VERSION "ZCUD_CAN1"

NS_ :

BS_:

BU_: ETC OGM POT SRS3 TRM ZCUD

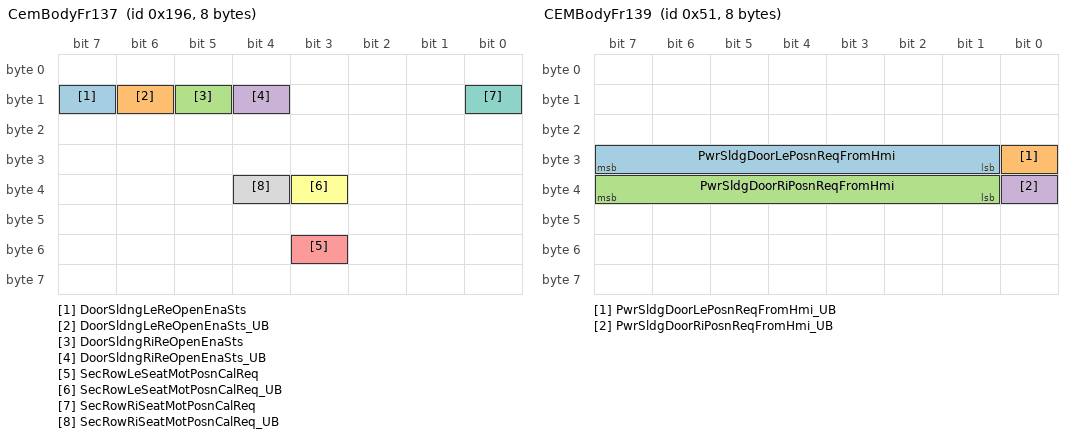
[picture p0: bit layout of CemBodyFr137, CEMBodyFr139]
BO_ 406 CemBodyFr137: 8 ZCUD
 SG_ DoorSldngLeReOpenEnaSts : 15|1@0+ (1,0) [0|1] "" Vector__XXX
 SG_ DoorSldngLeReOpenEnaSts_UB : 14|1@0+ (1,0) [0|1] "" Vector__XXX
 SG_ DoorSldngRiReOpenEnaSts : 13|1@0+ (1,0) [0|1] "" Vector__XXX
 SG_ DoorSldngRiReOpenEnaSts_UB : 12|1@0+ (1,0) [0|1] "" Vector__XXX
 SG_ SecRowLeSeatMotPosnCalReq : 51|1@0+ (1,0) [0|1] "" Vector__XXX
 SG_ SecRowLeSeatMotPosnCalReq_UB : 35|1@0+ (1,0) [0|1] "" Vector__XXX
 SG_ SecRowRiSeatMotPosnCalReq : 8|1@0+ (1,0) [0|1] "" Vector__XXX
 SG_ SecRowRiSeatMotPosnCalReq_UB : 36|1@0+ (1,0) [0|1] "" Vector__XXX

BO_ 81 CEMBodyFr139: 8 ZCUD
 SG_ PwrSldgDoorLePosnReqFromHmi : 31|7@0+ (1,0) [0|101] "%" Vector__XXX
 SG_ PwrSldgDoorLePosnReqFromHmi_UB : 24|1@0+ (1,0) [0|1] "" Vector__XXX
 SG_ PwrSldgDoorRiPosnReqFromHmi : 39|7@0+ (1,0) [0|101] "%" Vector__XXX
 SG_ PwrSldgDoorRiPosnReqFromHmi_UB : 32|1@0+ (1,0) [0|1] "" Vector__XXX

BO_ 1441 EtcToCmdXcpFr01: 8 ETC

BO_ 1412 EtcToRmlXcpFr01: 8 ETC

BO_ 1409 EtcToRmrXcpFr01: 8 ETC

BO_ 1413 EtcToSmblXcpFr01: 8 ETC

BO_ 1415 EtcToSmbrXcpFr01: 8 ETC

BO_ 1472 EtcToSmpXcpFr01: 8 ETC

BO_ 1465 EtcToTrmXcpFr01: 8 ETC

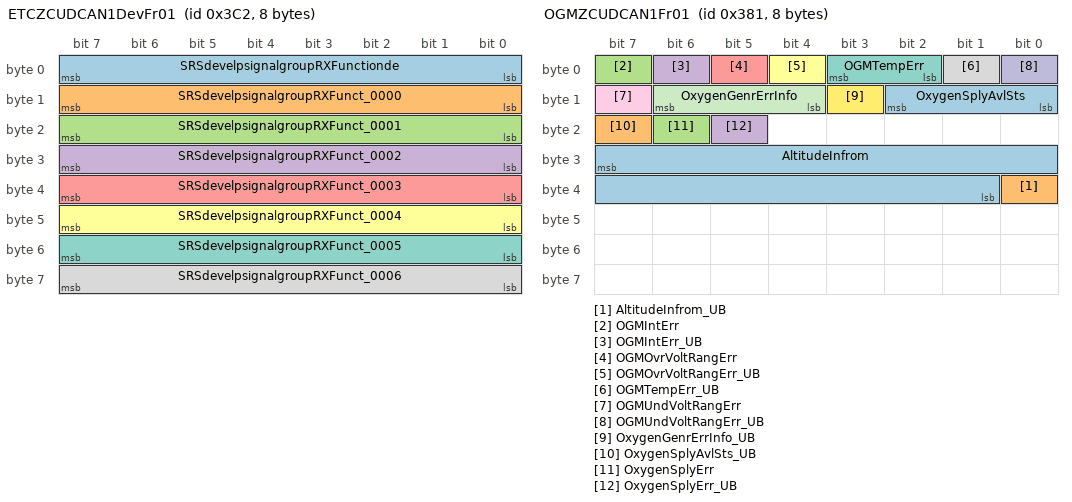
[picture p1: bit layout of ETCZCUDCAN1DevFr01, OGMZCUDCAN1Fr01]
BO_ 962 ETCZCUDCAN1DevFr01: 8 ETC
 SG_ SRSdevelpsignalgroupRXFunctionde : 7|8@0+ (1,0) [0|255] "Unitless"  SRS3
 SG_ SRSdevelpsignalgroupRXFunct_0000 : 15|8@0+ (1,0) [0|255] "Unitless"  SRS3
 SG_ SRSdevelpsignalgroupRXFunct_0001 : 23|8@0+ (1,0) [0|255] "Unitless"  SRS3
 SG_ SRSdevelpsignalgroupRXFunct_0002 : 31|8@0+ (1,0) [0|255] "Unitless"  SRS3
 SG_ SRSdevelpsignalgroupRXFunct_0003 : 39|8@0+ (1,0) [0|255] "Unitless"  SRS3
 SG_ SRSdevelpsignalgroupRXFunct_0004 : 47|8@0+ (1,0) [0|255] "Unitless"  SRS3
 SG_ SRSdevelpsignalgroupRXFunct_0005 : 55|8@0+ (1,0) [0|255] "Unitless"  SRS3
 SG_ SRSdevelpsignalgroupRXFunct_0006 : 63|8@0+ (1,0) [0|255] "Unitless"  SRS3

BO_ 1596 OgmToZcudZCUDCAN1DiagResFrame: 8 OGM
 SG_ OgmToZcudZCUDCan1DiagResNpdu : 7|64@0+ (1,0) [0|0] ""  ZCUD

BO_ 897 OGMZCUDCAN1Fr01: 8 OGM
 SG_ AltitudeInfrom : 31|15@0+ (1,0) [0|32767] "Unitless"  ZCUD
 SG_ AltitudeInfrom_UB : 32|1@0+ (1,0) [0|1] ""  ZCUD
 SG_ OGMIntErr : 7|1@0+ (1,0) [0|1] ""  ZCUD
 SG_ OGMIntErr_UB : 6|1@0+ (1,0) [0|1] ""  ZCUD
 SG_ OGMOvrVoltRangErr : 5|1@0+ (1,0) [0|1] ""  ZCUD
 SG_ OGMOvrVoltRangErr_UB : 4|1@0+ (1,0) [0|1] ""  ZCUD
 SG_ OGMTempErr : 3|2@0+ (1,0) [0|3] ""  ZCUD
 SG_ OGMTempErr_UB : 1|1@0+ (1,0) [0|1] ""  ZCUD
 SG_ OGMUndVoltRangErr : 15|1@0+ (1,0) [0|1] ""  ZCUD
 SG_ OGMUndVoltRangErr_UB : 0|1@0+ (1,0) [0|1] ""  ZCUD
 SG_ OxygenGenrErrInfo : 14|3@0+ (1,0) [0|7] ""  ZCUD
 SG_ OxygenGenrErrInfo_UB : 11|1@0+ (1,0) [0|1] ""  ZCUD
 SG_ OxygenSplyAvlSts : 10|3@0+ (1,0) [0|7] ""  ZCUD
 SG_ OxygenSplyAvlSts_UB : 23|1@0+ (1,0) [0|1] ""  ZCUD
 SG_ OxygenSplyErr : 22|1@0+ (1,0) [0|1] ""  ZCUD
 SG_ OxygenSplyErr_UB : 21|1@0+ (1,0) [0|1] ""  ZCUD

BO_ 769 OGMZCUDCAN1Fr02: 8 OGM
 SG_ OGMMissingSlaveSignal : 7|1@0+ (1,0) [0|1] ""  ZCUD
 SG_ OGMMissingSlaveSignal_UB : 6|1@0+ (1,0) [0|1] ""  ZCUD

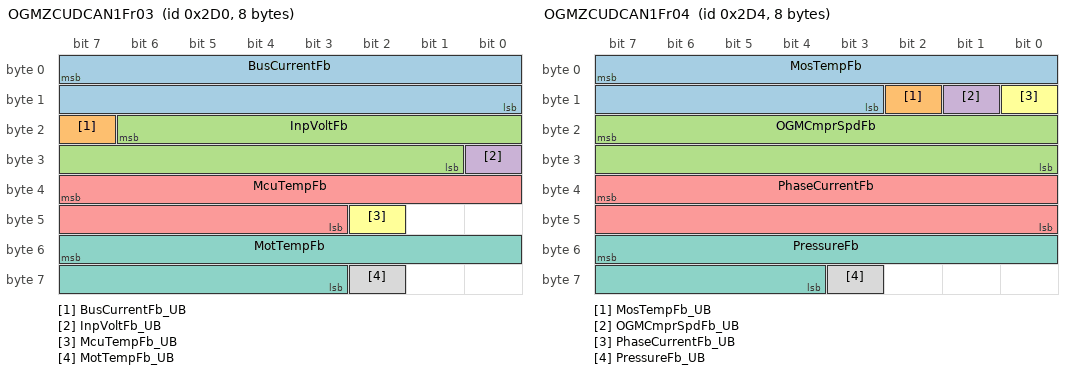
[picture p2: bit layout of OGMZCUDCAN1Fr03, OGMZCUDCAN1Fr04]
BO_ 720 OGMZCUDCAN1Fr03: 8 OGM
 SG_ BusCurrentFb : 7|16@0- (0.1,0) [-3276.8|3276.7] "A"  ZCUD
 SG_ BusCurrentFb_UB : 23|1@0+ (1,0) [0|1] ""  ZCUD
 SG_ InpVoltFb : 22|14@0+ (0.1,0) [0|1638.3] "Volt"  ZCUD
 SG_ InpVoltFb_UB : 24|1@0+ (1,0) [0|1] ""  ZCUD
 SG_ McuTempFb : 39|13@0- (0.1,0) [-256|255.9] "degC"  ZCUD
 SG_ McuTempFb_UB : 42|1@0+ (1,0) [0|1] ""  ZCUD
 SG_ MotTempFb : 55|13@0- (0.1,0) [-256|255.9] "degC"  ZCUD
 SG_ MotTempFb_UB : 58|1@0+ (1,0) [0|1] ""  ZCUD

BO_ 724 OGMZCUDCAN1Fr04: 8 OGM
 SG_ MosTempFb : 7|13@0- (0.1,0) [-256|255.9] "degC"  ZCUD
 SG_ MosTempFb_UB : 10|1@0+ (1,0) [0|1] ""  ZCUD
 SG_ OGMCmprSpdFb : 23|16@0+ (1,0) [0|65535] "Unitless"  ZCUD
 SG_ OGMCmprSpdFb_UB : 9|1@0+ (1,0) [0|1] ""  ZCUD
 SG_ PhaseCurrentFb : 39|16@0- (0.1,0) [-3276.8|3276.7] "A"  ZCUD
 SG_ PhaseCurrentFb_UB : 8|1@0+ (1,0) [0|1] ""  ZCUD
 SG_ PressureFb : 55|12@0+ (0.1,0) [0|409.5] "bar"  ZCUD
 SG_ PressureFb_UB : 59|1@0+ (1,0) [0|1] ""  ZCUD

BO_ 730 OGMZCUDCAN1Fr05: 8 OGM
 SG_ BackflushVlvErr : 7|2@0+ (1,0) [0|3] "Unitless"  ZCUD
 SG_ BackflushVlvErr_UB : 29|1@0+ (1,0) [0|1] ""  ZCUD
 SG_ ChgFilElmWarn : 5|2@0+ (1,0) [0|3] "Unitless"  ZCUD
 SG_ ChgFilElmWarn_UB : 28|1@0+ (1,0) [0|1] ""  ZCUD
 SG_ CoolgFanErr : 3|2@0+ (1,0) [0|3] "Unitless"  ZCUD
 SG_ CoolgFanErr_UB : 27|1@0+ (1,0) [0|1] ""  ZCUD
 SG_ McuOvrTempErr : 1|2@0+ (1,0) [0|3] "Unitless"  ZCUD
 SG_ McuOvrTempErr_UB : 26|1@0+ (1,0) [0|1] ""  ZCUD
 SG_ McuTempSnsrErr : 15|2@0+ (1,0) [0|3] "Unitless"  ZCUD
 SG_ McuTempSnsrErr_UB : 25|1@0+ (1,0) [0|1] ""  ZCUD
 SG_ MosOvrTempErr : 13|2@0+ (1,0) [0|3] "Unitless"  ZCUD
 SG_ MosOvrTempErr_UB : 24|1@0+ (1,0) [0|1] ""  ZCUD
 SG_ MosTempSnsrErr : 11|2@0+ (1,0) [0|3] "Unitless"  ZCUD
 SG_ MosTempSnsrErr_UB : 39|1@0+ (1,0) [0|1] ""  ZCUD
 SG_ MotTempSnsrErr : 9|2@0+ (1,0) [0|3] "Unitless"  ZCUD
 SG_ MotTempSnsrErr_UB : 38|1@0+ (1,0) [0|1] ""  ZCUD
 SG_ OxygenConcFlt : 23|2@0+ (1,0) [0|3] "Unitless"  ZCUD
 SG_ OxygenConcFlt_UB : 37|1@0+ (1,0) [0|1] ""  ZCUD
 SG_ OxygenTubeBlk : 21|2@0+ (1,0) [0|3] "Unitless"  ZCUD
 SG_ OxygenTubeBlk_UB : 36|1@0+ (1,0) [0|1] ""  ZCUD
 SG_ PressureFlt : 19|2@0+ (1,0) [0|3] "Unitless"  ZCUD
 SG_ PressureFlt_UB : 35|1@0+ (1,0) [0|1] ""  ZCUD
 SG_ PressureSnsrErr : 17|2@0+ (1,0) [0|3] "Unitless"  ZCUD
 SG_ PressureSnsrErr_UB : 34|1@0+ (1,0) [0|1] ""  ZCUD
 SG_ VlvVoltFlt : 31|2@0+ (1,0) [0|3] "Unitless"  ZCUD
 SG_ VlvVoltFlt_UB : 33|1@0+ (1,0) [0|1] ""  ZCUD

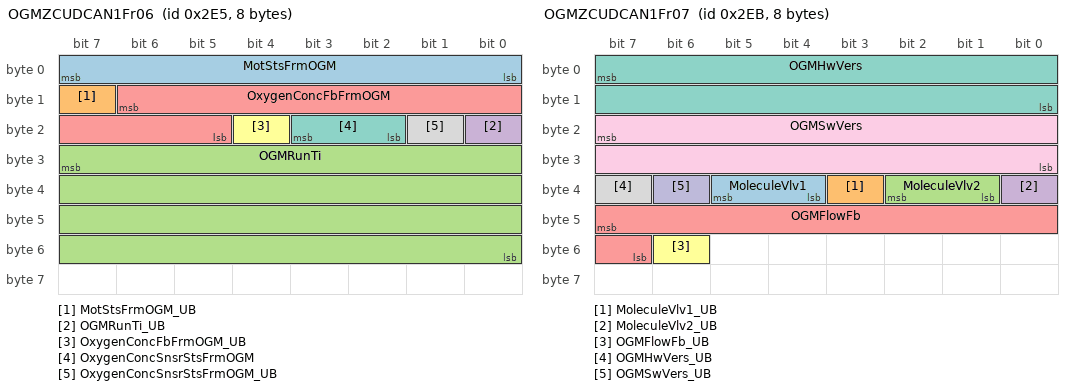
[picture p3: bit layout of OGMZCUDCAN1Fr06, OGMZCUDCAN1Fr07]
BO_ 741 OGMZCUDCAN1Fr06: 8 OGM
 SG_ MotStsFrmOGM : 7|8@0+ (1,0) [0|255] "Unitless"  ZCUD
 SG_ MotStsFrmOGM_UB : 15|1@0+ (1,0) [0|1] ""  ZCUD
 SG_ OGMRunTi : 31|32@0+ (1,0) [0|4294967295] "Unitless"  ZCUD
 SG_ OGMRunTi_UB : 16|1@0+ (1,0) [0|1] ""  ZCUD
 SG_ OxygenConcFbFrmOGM : 14|10@0+ (0.1,0) [0|100] "%"  ZCUD
 SG_ OxygenConcFbFrmOGM_UB : 20|1@0+ (1,0) [0|1] ""  ZCUD
 SG_ OxygenConcSnsrStsFrmOGM : 19|2@0+ (1,0) [0|3] "Unitless"  ZCUD
 SG_ OxygenConcSnsrStsFrmOGM_UB : 17|1@0+ (1,0) [0|1] ""  ZCUD

BO_ 747 OGMZCUDCAN1Fr07: 8 OGM
 SG_ MoleculeVlv1 : 37|2@0+ (1,0) [0|3] "Unitless"  ZCUD
 SG_ MoleculeVlv1_UB : 35|1@0+ (1,0) [0|1] ""  ZCUD
 SG_ MoleculeVlv2 : 34|2@0+ (1,0) [0|3] "Unitless"  ZCUD
 SG_ MoleculeVlv2_UB : 32|1@0+ (1,0) [0|1] ""  ZCUD
 SG_ OGMFlowFb : 47|9@0+ (0.1,0) [0|51.1] "L / min"  ZCUD
 SG_ OGMFlowFb_UB : 54|1@0+ (1,0) [0|1] ""  ZCUD
 SG_ OGMHwVers : 7|16@0+ (1,0) [0|65535] "Unitless"  ZCUD
 SG_ OGMHwVers_UB : 39|1@0+ (1,0) [0|1] ""  ZCUD
 SG_ OGMSwVers : 23|16@0+ (1,0) [0|65535] "Unitless"  ZCUD
 SG_ OGMSwVers_UB : 38|1@0+ (1,0) [0|1] ""  ZCUD

BO_ 704 OGMZCUDCAN1Fr08: 8 OGM
 SG_ OxygenSplyDesPwrCns : 7|11@0+ (1,0) [0|2047] "W"  ZCUD
 SG_ OxygenSplyDesPwrCns_UB : 12|1@0+ (1,0) [0|1] ""  ZCUD

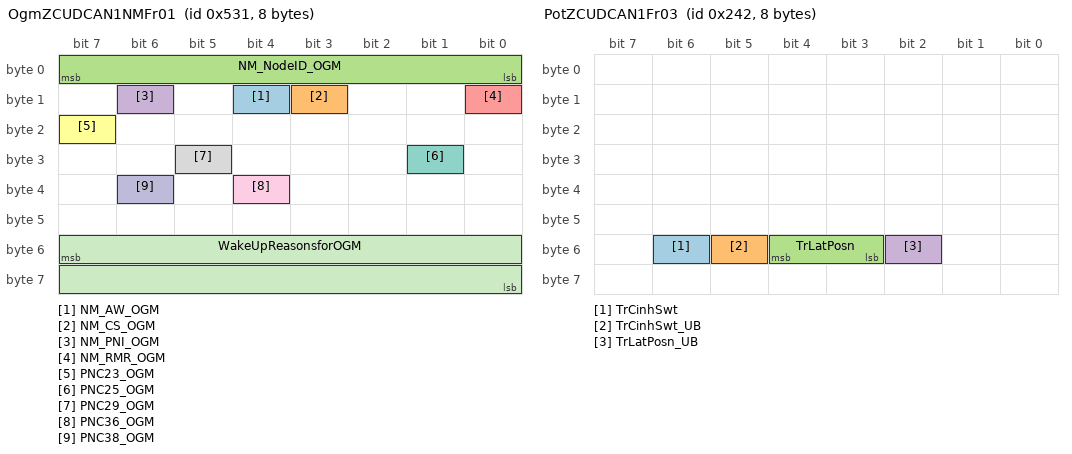
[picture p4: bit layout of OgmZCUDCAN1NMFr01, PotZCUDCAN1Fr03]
BO_ 1329 OgmZCUDCAN1NMFr01: 8 OGM
 SG_ NM_AW_OGM : 12|1@0+ (1,0) [0|0] ""  ZCUD
 SG_ NM_CS_OGM : 11|1@0+ (1,0) [0|0] ""  ZCUD
 SG_ NM_NodeID_OGM : 7|8@0+ (1,0) [0|0] ""  ZCUD
 SG_ NM_PNI_OGM : 14|1@0+ (1,0) [0|0] ""  ZCUD
 SG_ NM_RMR_OGM : 8|1@0+ (1,0) [0|0] ""  ZCUD
 SG_ PNC23_OGM : 23|1@0+ (1,0) [0|0] ""  ZCUD
 SG_ PNC25_OGM : 25|1@0+ (1,0) [0|0] ""  ZCUD
 SG_ PNC29_OGM : 29|1@0+ (1,0) [0|0] ""  ZCUD
 SG_ PNC36_OGM : 36|1@0+ (1,0) [0|0] ""  ZCUD
 SG_ PNC38_OGM : 38|1@0+ (1,0) [0|0] ""  ZCUD
 SG_ WakeUpReasonsforOGM : 55|16@0+ (1,0) [0|65535] "" Vector__XXX

BO_ 1346 OGMZCUDCAN1VFCVectorFr: 8 OGM
 SG_ VFCVectorOGMBlockID : 1|2@0+ (1,0) [0|3] "Unitless"  ZCUD
 SG_ VFCVectorOGMVFCid0 : 2|1@0+ (1,0) [0|1] ""  ZCUD
 SG_ VFCVectorOGMVFCid1 : 3|1@0+ (1,0) [0|1] ""  ZCUD
 SG_ VFCVectorOGMVFCid10 : 12|1@0+ (1,0) [0|1] ""  ZCUD
 SG_ VFCVectorOGMVFCid11 : 13|1@0+ (1,0) [0|1] ""  ZCUD
 SG_ VFCVectorOGMVFCid12 : 14|1@0+ (1,0) [0|1] ""  ZCUD
 SG_ VFCVectorOGMVFCid13 : 15|1@0+ (1,0) [0|1] ""  ZCUD
 SG_ VFCVectorOGMVFCid14 : 16|1@0+ (1,0) [0|1] ""  ZCUD
 SG_ VFCVectorOGMVFCid15 : 17|1@0+ (1,0) [0|1] ""  ZCUD
 SG_ VFCVectorOGMVFCid16 : 18|1@0+ (1,0) [0|1] ""  ZCUD
 SG_ VFCVectorOGMVFCid17 : 19|1@0+ (1,0) [0|1] ""  ZCUD
 SG_ VFCVectorOGMVFCid18 : 20|1@0+ (1,0) [0|1] ""  ZCUD
 SG_ VFCVectorOGMVFCid19 : 21|1@0+ (1,0) [0|1] ""  ZCUD
 SG_ VFCVectorOGMVFCid2 : 4|1@0+ (1,0) [0|1] ""  ZCUD
 SG_ VFCVectorOGMVFCid20 : 22|1@0+ (1,0) [0|1] ""  ZCUD
 SG_ VFCVectorOGMVFCid21 : 23|1@0+ (1,0) [0|1] ""  ZCUD
 SG_ VFCVectorOGMVFCid22 : 24|1@0+ (1,0) [0|1] ""  ZCUD
 SG_ VFCVectorOGMVFCid23 : 25|1@0+ (1,0) [0|1] ""  ZCUD
 SG_ VFCVectorOGMVFCid24 : 26|1@0+ (1,0) [0|1] ""  ZCUD
 SG_ VFCVectorOGMVFCid25 : 27|1@0+ (1,0) [0|1] ""  ZCUD
 SG_ VFCVectorOGMVFCid26 : 28|1@0+ (1,0) [0|1] ""  ZCUD
 SG_ VFCVectorOGMVFCid27 : 29|1@0+ (1,0) [0|1] ""  ZCUD
 SG_ VFCVectorOGMVFCid28 : 30|1@0+ (1,0) [0|1] ""  ZCUD
 SG_ VFCVectorOGMVFCid29 : 31|1@0+ (1,0) [0|1] ""  ZCUD
 SG_ VFCVectorOGMVFCid3 : 5|1@0+ (1,0) [0|1] ""  ZCUD
 SG_ VFCVectorOGMVFCid30 : 32|1@0+ (1,0) [0|1] ""  ZCUD
 SG_ VFCVectorOGMVFCid31 : 33|1@0+ (1,0) [0|1] ""  ZCUD
 SG_ VFCVectorOGMVFCid32 : 34|1@0+ (1,0) [0|1] ""  ZCUD
 SG_ VFCVectorOGMVFCid33 : 35|1@0+ (1,0) [0|1] ""  ZCUD
 SG_ VFCVectorOGMVFCid34 : 36|1@0+ (1,0) [0|1] ""  ZCUD
 SG_ VFCVectorOGMVFCid35 : 37|1@0+ (1,0) [0|1] ""  ZCUD
 SG_ VFCVectorOGMVFCid36 : 38|1@0+ (1,0) [0|1] ""  ZCUD
 SG_ VFCVectorOGMVFCid37 : 39|1@0+ (1,0) [0|1] ""  ZCUD
 SG_ VFCVectorOGMVFCid38 : 40|1@0+ (1,0) [0|1] ""  ZCUD
 SG_ VFCVectorOGMVFCid39 : 41|1@0+ (1,0) [0|1] ""  ZCUD
 SG_ VFCVectorOGMVFCid4 : 6|1@0+ (1,0) [0|1] ""  ZCUD
 SG_ VFCVectorOGMVFCid40 : 42|1@0+ (1,0) [0|1] ""  ZCUD
 SG_ VFCVectorOGMVFCid41 : 43|1@0+ (1,0) [0|1] ""  ZCUD
 SG_ VFCVectorOGMVFCid42 : 44|1@0+ (1,0) [0|1] ""  ZCUD
 SG_ VFCVectorOGMVFCid43 : 45|1@0+ (1,0) [0|1] ""  ZCUD
 SG_ VFCVectorOGMVFCid44 : 46|1@0+ (1,0) [0|1] ""  ZCUD
 SG_ VFCVectorOGMVFCid45 : 47|1@0+ (1,0) [0|1] ""  ZCUD
 SG_ VFCVectorOGMVFCid46 : 48|1@0+ (1,0) [0|1] ""  ZCUD
 SG_ VFCVectorOGMVFCid47 : 49|1@0+ (1,0) [0|1] ""  ZCUD
 SG_ VFCVectorOGMVFCid48 : 50|1@0+ (1,0) [0|1] ""  ZCUD
 SG_ VFCVectorOGMVFCid49 : 51|1@0+ (1,0) [0|1] ""  ZCUD
 SG_ VFCVectorOGMVFCid5 : 7|1@0+ (1,0) [0|1] ""  ZCUD
 SG_ VFCVectorOGMVFCid50 : 52|1@0+ (1,0) [0|1] ""  ZCUD
 SG_ VFCVectorOGMVFCid51 : 53|1@0+ (1,0) [0|1] ""  ZCUD
 SG_ VFCVectorOGMVFCid52 : 54|1@0+ (1,0) [0|1] ""  ZCUD
 SG_ VFCVectorOGMVFCid53 : 55|1@0+ (1,0) [0|1] ""  ZCUD
 SG_ VFCVectorOGMVFCid54 : 56|1@0+ (1,0) [0|1] ""  ZCUD
 SG_ VFCVectorOGMVFCid55 : 57|1@0+ (1,0) [0|1] ""  ZCUD
 SG_ VFCVectorOGMVFCid56 : 58|1@0+ (1,0) [0|1] ""  ZCUD
 SG_ VFCVectorOGMVFCid57 : 59|1@0+ (1,0) [0|1] ""  ZCUD
 SG_ VFCVectorOGMVFCid58 : 60|1@0+ (1,0) [0|1] ""  ZCUD
 SG_ VFCVectorOGMVFCid59 : 61|1@0+ (1,0) [0|1] ""  ZCUD
 SG_ VFCVectorOGMVFCid6 : 8|1@0+ (1,0) [0|1] ""  ZCUD
 SG_ VFCVectorOGMVFCid60 : 62|1@0+ (1,0) [0|1] ""  ZCUD
 SG_ VFCVectorOGMVFCid61 : 63|1@0+ (1,0) [0|1] ""  ZCUD
 SG_ VFCVectorOGMVFCid7 : 9|1@0+ (1,0) [0|1] ""  ZCUD
 SG_ VFCVectorOGMVFCid8 : 10|1@0+ (1,0) [0|1] ""  ZCUD
 SG_ VFCVectorOGMVFCid9 : 11|1@0+ (1,0) [0|1] ""  ZCUD

BO_ 1557 PotToZcudZCUDCan1DiagResFr: 8 POT
 SG_ PotToZcudZCUDCan1DiagResNpdu : 7|64@0+ (1,0) [0|0] ""  ZCUD

BO_ 416 PotZCUDCAN1Fr01: 8 POT
 SG_ TrCrashUnlckSts : 7|1@0+ (1,0) [0|1] ""  ZCUD
 SG_ TrCrashUnlckSts_UB : 6|1@0+ (1,0) [0|1] ""  ZCUD

BO_ 149 PotZCUDCAN1Fr02: 8 POT
 SG_ TrInsdOpenSwtSts : 51|1@0+ (1,0) [0|1] ""  ZCUD
 SG_ TrInsdOpenSwtSts_UB : 50|1@0+ (1,0) [0|1] ""  ZCUD

BO_ 578 PotZCUDCAN1Fr03: 8 POT
 SG_ TrCinhSwt : 54|1@0+ (1,0) [0|1] ""  ZCUD
 SG_ TrCinhSwt_UB : 53|1@0+ (1,0) [0|1] ""  ZCUD
 SG_ TrLatPosn : 52|2@0+ (1,0) [0|3] ""  ZCUD
 SG_ TrLatPosn_UB : 50|1@0+ (1,0) [0|1] ""  ZCUD

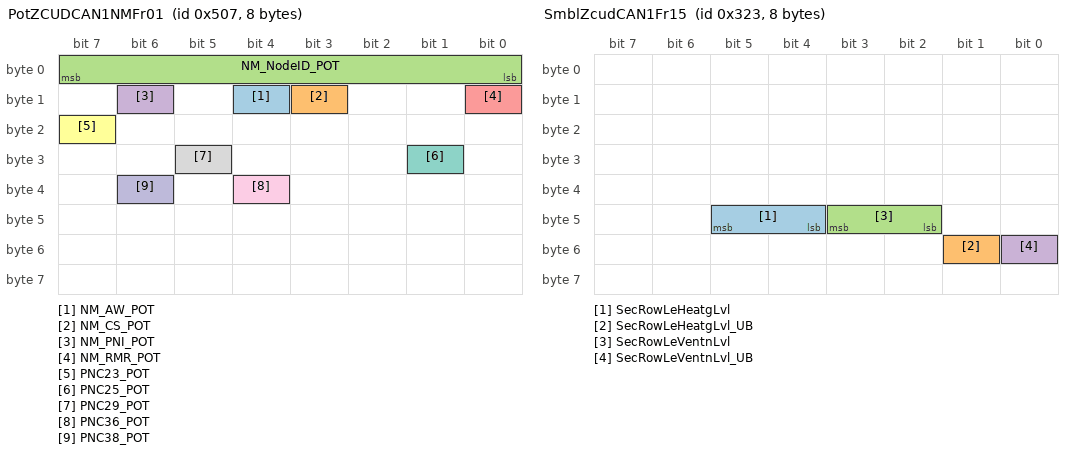
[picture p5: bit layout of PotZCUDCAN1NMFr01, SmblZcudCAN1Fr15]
BO_ 1287 PotZCUDCAN1NMFr01: 8 POT
 SG_ NM_AW_POT : 12|1@0+ (1,0) [0|0] ""  OGM
 SG_ NM_CS_POT : 11|1@0+ (1,0) [0|0] ""  OGM
 SG_ NM_NodeID_POT : 7|8@0+ (1,0) [0|0] ""  OGM
 SG_ NM_PNI_POT : 14|1@0+ (1,0) [0|0] ""  OGM
 SG_ NM_RMR_POT : 8|1@0+ (1,0) [0|0] ""  OGM
 SG_ PNC23_POT : 23|1@0+ (1,0) [0|0] ""  OGM
 SG_ PNC25_POT : 25|1@0+ (1,0) [0|0] ""  OGM
 SG_ PNC29_POT : 29|1@0+ (1,0) [0|0] ""  OGM
 SG_ PNC36_POT : 36|1@0+ (1,0) [0|0] ""  OGM
 SG_ PNC38_POT : 38|1@0+ (1,0) [0|0] ""  OGM

BO_ 803 SmblZcudCAN1Fr15: 8 ZCUD
 SG_ SecRowLeHeatgLvl : 45|2@0+ (1,0) [0|3] "" Vector__XXX
 SG_ SecRowLeHeatgLvl_UB : 49|1@0+ (1,0) [0|1] "" Vector__XXX
 SG_ SecRowLeVentnLvl : 43|2@0+ (1,0) [0|3] "" Vector__XXX
 SG_ SecRowLeVentnLvl_UB : 48|1@0+ (1,0) [0|1] "" Vector__XXX

BO_ 262 SmtlZcudCAN1Fr01: 8 ZCUD
 SG_ RowReLeModSwtSts : 2|1@0+ (1,0) [0|1] "" Vector__XXX
 SG_ RowReLeModSwtSts_UB : 15|1@0+ (1,0) [0|1] "" Vector__XXX

BO_ 261 SmtrZcudCAN1Fr01: 8 ZCUD
 SG_ RowReRiModSwtSts : 2|1@0+ (1,0) [0|1] "" Vector__XXX
 SG_ RowReRiModSwtSts_UB : 15|1@0+ (1,0) [0|1] "" Vector__XXX

BO_ 2041 SrsToZcudISO26021ZCUCAN1DiagResF: 8 SRS3
 SG_ SrsToZcudISO26021ZCUDCan1ResNpdu : 7|64@0+ (1,0) [0|0] ""  ZCUD

BO_ 1593 SrsToZcudZCUDCan1DiagResFr: 8 SRS3
 SG_ SrsToZcudZCUDCan1DiagResNpdu : 7|64@0+ (1,0) [0|0] ""  ZCUD

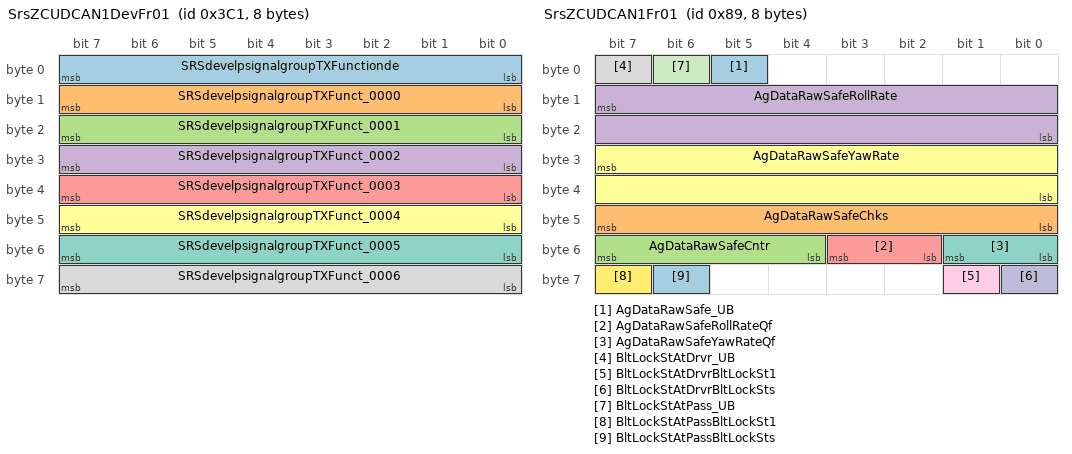
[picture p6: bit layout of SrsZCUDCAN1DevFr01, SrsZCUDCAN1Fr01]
BO_ 961 SrsZCUDCAN1DevFr01: 8 SRS3
 SG_ SRSdevelpsignalgroupTXFunctionde : 7|8@0+ (1,0) [0|255] "Unitless"  ETC
 SG_ SRSdevelpsignalgroupTXFunct_0000 : 15|8@0+ (1,0) [0|255] "Unitless"  ETC
 SG_ SRSdevelpsignalgroupTXFunct_0001 : 23|8@0+ (1,0) [0|255] "Unitless"  ETC
 SG_ SRSdevelpsignalgroupTXFunct_0002 : 31|8@0+ (1,0) [0|255] "Unitless"  ETC
 SG_ SRSdevelpsignalgroupTXFunct_0003 : 39|8@0+ (1,0) [0|255] "Unitless"  ETC
 SG_ SRSdevelpsignalgroupTXFunct_0004 : 47|8@0+ (1,0) [0|255] "Unitless"  ETC
 SG_ SRSdevelpsignalgroupTXFunct_0005 : 55|8@0+ (1,0) [0|255] "Unitless"  ETC
 SG_ SRSdevelpsignalgroupTXFunct_0006 : 63|8@0+ (1,0) [0|255] "Unitless"  ETC

BO_ 137 SrsZCUDCAN1Fr01: 8 SRS3
 SG_ AgDataRawSafe_UB : 5|1@0+ (1,0) [0|1] ""  ZCUD
 SG_ AgDataRawSafeChks : 47|8@0+ (1,0) [0|255] "Unitless"  ZCUD
 SG_ AgDataRawSafeCntr : 55|4@0+ (1,0) [0|15] "Unitless"  ZCUD
 SG_ AgDataRawSafeRollRate : 15|16@0- (0.000244140625,0) [-6|6] "rad/s"  ZCUD
 SG_ AgDataRawSafeRollRateQf : 51|2@0+ (1,0) [0|3] ""  ZCUD
 SG_ AgDataRawSafeYawRate : 31|16@0- (0.000244140625,0) [-6|6] "rad/s"  ZCUD
 SG_ AgDataRawSafeYawRateQf : 49|2@0+ (1,0) [0|3] ""  ZCUD
 SG_ BltLockStAtDrvr_UB : 7|1@0+ (1,0) [0|1] ""  ZCUD
 SG_ BltLockStAtDrvrBltLockSt1 : 57|1@0+ (1,0) [0|1] ""  ZCUD
 SG_ BltLockStAtDrvrBltLockSts : 56|1@0+ (1,0) [0|1] ""  ZCUD
 SG_ BltLockStAtPass_UB : 6|1@0+ (1,0) [0|1] ""  ZCUD
 SG_ BltLockStAtPassBltLockSt1 : 63|1@0+ (1,0) [0|1] ""  ZCUD
 SG_ BltLockStAtPassBltLockSts : 62|1@0+ (1,0) [0|1] ""  ZCUD

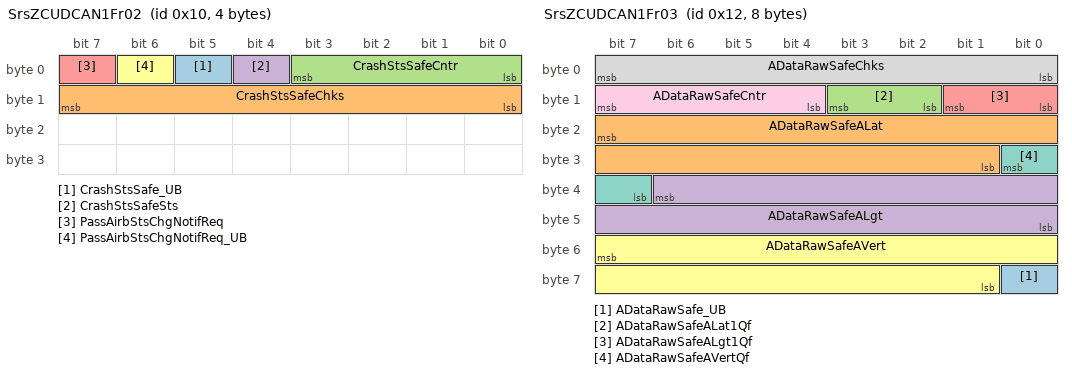
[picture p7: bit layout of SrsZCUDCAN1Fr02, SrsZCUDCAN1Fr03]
BO_ 16 SrsZCUDCAN1Fr02: 4 SRS3
 SG_ CrashStsSafe_UB : 5|1@0+ (1,0) [0|1] ""  ZCUD
 SG_ CrashStsSafeChks : 15|8@0+ (1,0) [0|255] "Unitless"  ZCUD
 SG_ CrashStsSafeCntr : 3|4@0+ (1,0) [0|15] "Unitless"  ZCUD
 SG_ CrashStsSafeSts : 4|1@0+ (1,0) [0|1] ""  ZCUD
 SG_ PassAirbStsChgNotifReq : 7|1@0+ (1,0) [0|1] ""  ZCUD
 SG_ PassAirbStsChgNotifReq_UB : 6|1@0+ (1,0) [0|1] ""  ZCUD

BO_ 18 SrsZCUDCAN1Fr03: 8 SRS3
 SG_ ADataRawSafe_UB : 56|1@0+ (1,0) [0|1] ""  ZCUD
 SG_ ADataRawSafeALat : 23|15@0- (0.0085,0) [-138.992|139.0005] "m/s^2"  ZCUD
 SG_ ADataRawSafeALat1Qf : 11|2@0+ (1,0) [0|3] ""  ZCUD
 SG_ ADataRawSafeALgt : 38|15@0- (0.0085,0) [-138.992|139.0005] "m/s^2"  ZCUD
 SG_ ADataRawSafeALgt1Qf : 9|2@0+ (1,0) [0|3] ""  ZCUD
 SG_ ADataRawSafeAVert : 55|15@0- (0.0085,0) [-138.992|139.0005] "m/s^2"  ZCUD
 SG_ ADataRawSafeAVertQf : 24|2@0+ (1,0) [0|3] ""  ZCUD
 SG_ ADataRawSafeChks : 7|8@0+ (1,0) [0|255] "Unitless"  ZCUD
 SG_ ADataRawSafeCntr : 15|4@0+ (1,0) [0|15] "Unitless"  ZCUD

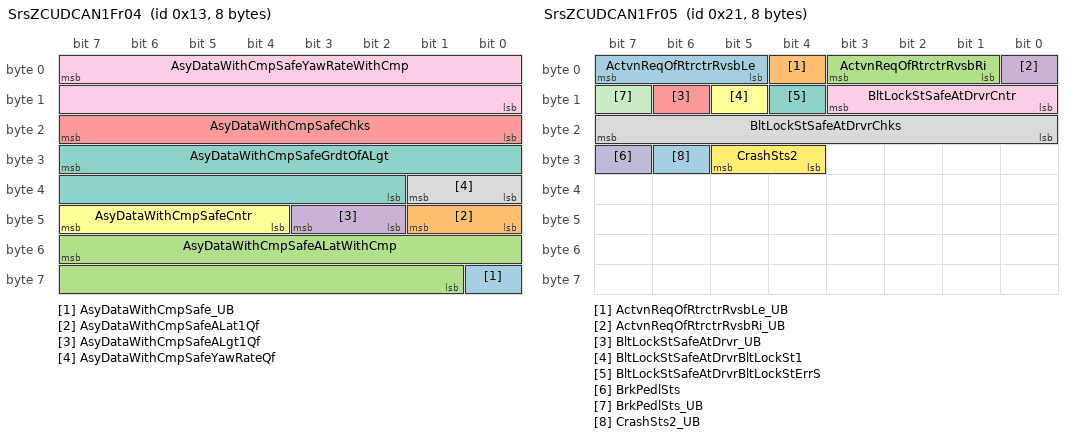
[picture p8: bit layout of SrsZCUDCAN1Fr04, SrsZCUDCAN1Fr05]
BO_ 19 SrsZCUDCAN1Fr04: 8 SRS3
 SG_ AsyDataWithCmpSafe_UB : 56|1@0+ (1,0) [0|1] ""  ZCUD
 SG_ AsyDataWithCmpSafeALat1Qf : 41|2@0+ (1,0) [0|3] ""  ZCUD
 SG_ AsyDataWithCmpSafeALatWithCmp : 55|15@0- (0.0085,0) [-138.992|139.0005] "m/s^2"  ZCUD
 SG_ AsyDataWithCmpSafeALgt1Qf : 43|2@0+ (1,0) [0|3] ""  ZCUD
 SG_ AsyDataWithCmpSafeChks : 23|8@0+ (1,0) [0|255] "Unitless"  ZCUD
 SG_ AsyDataWithCmpSafeCntr : 47|4@0+ (1,0) [0|15] "Unitless"  ZCUD
 SG_ AsyDataWithCmpSafeGrdtOfALgt : 31|14@0- (0.00390625,0) [-30|30] "m/s^3"  ZCUD
 SG_ AsyDataWithCmpSafeYawRateQf : 33|2@0+ (1,0) [0|3] ""  ZCUD
 SG_ AsyDataWithCmpSafeYawRateWithCmp : 7|16@0- (0.000244140625,0) [-6|6] "rad/s"  ZCUD

BO_ 33 SrsZCUDCAN1Fr05: 8 SRS3
 SG_ ActvnReqOfRtrctrRvsbLe : 7|3@0+ (1,0) [0|7] "" Vector__XXX
 SG_ ActvnReqOfRtrctrRvsbLe_UB : 4|1@0+ (1,0) [0|1] "" Vector__XXX
 SG_ ActvnReqOfRtrctrRvsbRi : 3|3@0+ (1,0) [0|7] "" Vector__XXX
 SG_ ActvnReqOfRtrctrRvsbRi_UB : 0|1@0+ (1,0) [0|1] "" Vector__XXX
 SG_ BltLockStSafeAtDrvr_UB : 14|1@0+ (1,0) [0|1] ""  ZCUD
 SG_ BltLockStSafeAtDrvrBltLockSt1 : 13|1@0+ (1,0) [0|1] ""  ZCUD
 SG_ BltLockStSafeAtDrvrBltLockStErrS : 12|1@0+ (1,0) [0|1] ""  ZCUD
 SG_ BltLockStSafeAtDrvrChks : 23|8@0+ (1,0) [0|255] "Unitless"  ZCUD
 SG_ BltLockStSafeAtDrvrCntr : 11|4@0+ (1,0) [0|15] "Unitless"  ZCUD
 SG_ BrkPedlSts : 31|1@0+ (1,0) [0|1] ""  ZCUD
 SG_ BrkPedlSts_UB : 15|1@0+ (1,0) [0|1] ""  ZCUD
 SG_ CrashSts2 : 29|2@0+ (1,0) [0|3] ""  ZCUD
 SG_ CrashSts2_UB : 30|1@0+ (1,0) [0|1] ""  ZCUD

BO_ 549 SrsZCUDCAN1Fr06: 8 SRS3
 SG_ BltLockStAtPassMid_UB : 24|1@0+ (1,0) [0|1] ""  ZCUD
 SG_ BltLockStAtPassMidBltLockEquid : 27|1@0+ (1,0) [0|1] ""  ZCUD
 SG_ BltLockStAtPassMidBltLockSt1 : 26|1@0+ (1,0) [0|1] ""  ZCUD
 SG_ BltLockStAtPassMidBltLockSts : 25|1@0+ (1,0) [0|1] ""  ZCUD
 SG_ BltLockStAtRowFrthLe_UB : 36|1@0+ (1,0) [0|1] ""  ZCUD
 SG_ BltLockStAtRowFrthLeBltLockEquid : 39|1@0+ (1,0) [0|1] ""  ZCUD
 SG_ BltLockStAtRowFrthLeBltLockSt1 : 38|1@0+ (1,0) [0|1] ""  ZCUD
 SG_ BltLockStAtRowFrthLeBltLockSts : 37|1@0+ (1,0) [0|1] ""  ZCUD
 SG_ BltLockStAtRowFrthMid_UB : 32|1@0+ (1,0) [0|1] ""  ZCUD
 SG_ BltLockStAtRowFrthMidBltLockEqui : 35|1@0+ (1,0) [0|1] ""  ZCUD
 SG_ BltLockStAtRowFrthMidBltLockSt1 : 34|1@0+ (1,0) [0|1] ""  ZCUD
 SG_ BltLockStAtRowFrthMidBltLockSts : 33|1@0+ (1,0) [0|1] ""  ZCUD
 SG_ BltLockStAtRowFrthRi_UB : 44|1@0+ (1,0) [0|1] ""  ZCUD
 SG_ BltLockStAtRowFrthRiBltLockEquid : 47|1@0+ (1,0) [0|1] ""  ZCUD
 SG_ BltLockStAtRowFrthRiBltLockSt1 : 46|1@0+ (1,0) [0|1] ""  ZCUD
 SG_ BltLockStAtRowFrthRiBltLockSts : 45|1@0+ (1,0) [0|1] ""  ZCUD
 SG_ BltLockStAtRowThrdMid_UB : 40|1@0+ (1,0) [0|1] ""  ZCUD
 SG_ BltLockStAtRowThrdMidBltLockEqui : 43|1@0+ (1,0) [0|1] ""  ZCUD
 SG_ BltLockStAtRowThrdMidBltLockSt1 : 42|1@0+ (1,0) [0|1] ""  ZCUD
 SG_ BltLockStAtRowThrdMidBltLockSts : 41|1@0+ (1,0) [0|1] ""  ZCUD
 SG_ SeatOccptAtRowFrthLe : 55|2@0+ (1,0) [0|3] ""  ZCUD
 SG_ SeatOccptAtRowFrthLe_UB : 30|1@0+ (1,0) [0|1] ""  ZCUD
 SG_ SeatOccptAtRowFrthMid : 53|2@0+ (1,0) [0|3] ""  ZCUD
 SG_ SeatOccptAtRowFrthMid_UB : 29|1@0+ (1,0) [0|1] ""  ZCUD
 SG_ SeatOccptAtRowFrthRi : 51|2@0+ (1,0) [0|3] ""  ZCUD
 SG_ SeatOccptAtRowFrthRi_UB : 28|1@0+ (1,0) [0|1] ""  ZCUD
 SG_ SeatOccptAtRowThrdMid : 63|2@0+ (1,0) [0|3] ""  ZCUD
 SG_ SeatOccptAtRowThrdMid_UB : 58|1@0+ (1,0) [0|1] ""  ZCUD

BO_ 322 SrsZCUDCAN1Fr07: 8 SRS3
 SG_ AgDataRaw2Safe_UB : 6|1@0+ (1,0) [0|1] ""  ZCUD
 SG_ AgDataRaw2SafeChks : 15|8@0+ (1,0) [0|255] "Unitless"  ZCUD
 SG_ AgDataRaw2SafeCntr : 3|4@0+ (1,0) [0|15] "Unitless"  ZCUD
 SG_ AgDataRaw2SafePitchRate : 23|16@0- (0.000244140625,0) [-6|6] "rad/s"  ZCUD
 SG_ AgDataRaw2SafePitchRateQf : 5|2@0+ (1,0) [0|3] ""  ZCUD
 SG_ PassAirbLampReq_UB : 33|1@0+ (1,0) [0|1] ""  ZCUD
 SG_ PassAirbLampReqChgOfPassAirbSts : 32|1@0+ (1,0) [0|1] ""  ZCUD
 SG_ PassAirbLampReqChks : 47|8@0+ (1,0) [0|255] "Unitless"  ZCUD
 SG_ PassAirbLampReqCntr : 51|4@0+ (1,0) [0|15] "Unitless"  ZCUD
 SG_ PassAirbLampReqPassAirbLampDiReq : 55|2@0+ (1,0) [0|3] ""  ZCUD
 SG_ PassAirbLampReqPassAirbLampEnaRe : 53|2@0+ (1,0) [0|3] ""  ZCUD
 SG_ ReqForAsyDataStorgFromRestrntSys : 38|1@0+ (1,0) [0|1] ""  ZCUD
 SG_ ReqForAsyDataStorgFromRestr_0000 : 37|1@0+ (1,0) [0|1] ""  ZCUD
 SG_ ReqForHzrdInt : 35|1@0+ (1,0) [0|1] ""  ZCUD
 SG_ ReqForHzrdInt_UB : 34|1@0+ (1,0) [0|1] ""  ZCUD
 SG_ SftyAirbRollovrSuppSts : 39|1@0+ (1,0) [0|1] ""  ZCUD
 SG_ SftyAirbRollovrSuppSts_UB : 7|1@0+ (1,0) [0|1] ""  ZCUD

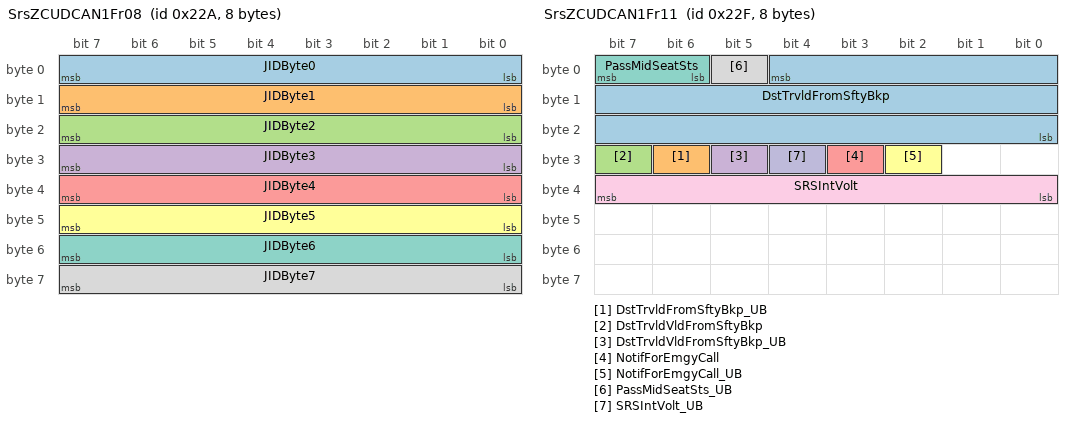
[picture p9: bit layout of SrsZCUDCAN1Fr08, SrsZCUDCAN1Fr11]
BO_ 554 SrsZCUDCAN1Fr08: 8 SRS3
 SG_ JIDByte0 : 7|8@0+ (1,0) [0|255] "Unitless"  ZCUD
 SG_ JIDByte1 : 15|8@0+ (1,0) [0|255] "Unitless"  ZCUD
 SG_ JIDByte2 : 23|8@0+ (1,0) [0|255] "Unitless"  ZCUD
 SG_ JIDByte3 : 31|8@0+ (1,0) [0|255] "Unitless"  ZCUD
 SG_ JIDByte4 : 39|8@0+ (1,0) [0|255] "Unitless"  ZCUD
 SG_ JIDByte5 : 47|8@0+ (1,0) [0|255] "Unitless"  ZCUD
 SG_ JIDByte6 : 55|8@0+ (1,0) [0|255] "Unitless"  ZCUD
 SG_ JIDByte7 : 63|8@0+ (1,0) [0|255] "Unitless"  ZCUD

BO_ 864 SrsZCUDCAN1Fr09: 8 SRS3
 SG_ BltCrashNotif_UB : 57|1@0+ (1,0) [0|1] ""  ZCUD
 SG_ BltCrashNotifDrvr : 61|2@0+ (1,0) [0|3] ""  ZCUD
 SG_ BltCrashNotifPass : 59|2@0+ (1,0) [0|3] ""  ZCUD
 SG_ PassAirbSts : 63|1@0+ (1,0) [0|1] ""  ZCUD
 SG_ PassAirbSts_UB : 62|1@0+ (1,0) [0|1] ""  ZCUD
 SG_ PedProtnMsgReqForFlt : 47|2@0+ (1,0) [0|3] ""  ZCUD
 SG_ PedProtnMsgReqForFlt_UB : 51|1@0+ (1,0) [0|1] ""  ZCUD
 SG_ PedProtnMsgReqForImpct : 53|1@0+ (1,0) [0|1] ""  ZCUD
 SG_ PedProtnMsgReqForImpct_UB : 52|1@0+ (1,0) [0|1] ""  ZCUD
 SG_ RecOfImpct_UB : 33|1@0+ (1,0) [0|1] ""  ZCUD
 SG_ RecOfImpctCrashFrnt : 16|1@0+ (1,0) [0|1] ""  ZCUD
 SG_ RecOfImpctCrashOffroadA : 34|1@0+ (1,0) [0|1] ""  ZCUD
 SG_ RecOfImpctCrashOffroadD : 35|1@0+ (1,0) [0|1] ""  ZCUD
 SG_ RecOfImpctCrashOffroadRT : 36|1@0+ (1,0) [0|1] ""  ZCUD
 SG_ RecOfImpctCrashOffroadRTsevere : 37|1@0+ (1,0) [0|1] ""  ZCUD
 SG_ RecOfImpctCrashPed : 38|1@0+ (1,0) [0|1] ""  ZCUD
 SG_ RecOfImpctCrashRe : 39|1@0+ (1,0) [0|1] ""  ZCUD
 SG_ RecOfImpctCrashRollovr : 24|1@0+ (1,0) [0|1] ""  ZCUD
 SG_ RecOfImpctCrashSideLe : 25|1@0+ (1,0) [0|1] ""  ZCUD
 SG_ RecOfImpctCrashSideRi : 26|1@0+ (1,0) [0|1] ""  ZCUD
 SG_ RecOfImpctCrashState : 28|2@0+ (1,0) [0|3] ""  ZCUD
 SG_ RecOfImpctImpctDvx : 7|8@0+ (1,0) [0|255] "Km/h"  ZCUD
 SG_ RecOfImpctImpctDvy : 15|8@0+ (1,0) [0|255] "Km/h"  ZCUD
 SG_ RecOfImpctImpctRollAg : 23|7@0+ (15,0) [0|1905] "Deg"  ZCUD
 SG_ RecOfImpctVehOri : 31|3@0+ (1,0) [0|7] ""  ZCUD
 SG_ RestrntSysLampReq : 45|2@0+ (1,0) [0|3] ""  ZCUD
 SG_ RestrntSysLampReq_UB : 50|1@0+ (1,0) [0|1] ""  ZCUD
 SG_ RestrntSysMsgReq : 43|2@0+ (1,0) [0|3] ""  ZCUD
 SG_ RestrntSysMsgReq_UB : 49|1@0+ (1,0) [0|1] ""  ZCUD
 SG_ SafetyCrashFb : 41|2@0+ (1,0) [0|3] ""  ZCUD
 SG_ SafetyCrashFb_UB : 48|1@0+ (1,0) [0|1] ""  ZCUD

BO_ 112 SrsZCUDCAN1Fr10: 8 SRS3
 SG_ BltLockStAtRowSecLe_UB : 4|1@0+ (1,0) [0|1] ""  ZCUD
 SG_ BltLockStAtRowSecLeBltLockEquid : 7|1@0+ (1,0) [0|1] ""  ZCUD
 SG_ BltLockStAtRowSecLeBltLockSt1 : 6|1@0+ (1,0) [0|1] ""  ZCUD
 SG_ BltLockStAtRowSecLeBltLockSts : 5|1@0+ (1,0) [0|1] ""  ZCUD
 SG_ BltLockStAtRowSecMid_UB : 0|1@0+ (1,0) [0|1] ""  ZCUD
 SG_ BltLockStAtRowSecMidBltLockEquid : 3|1@0+ (1,0) [0|1] ""  ZCUD
 SG_ BltLockStAtRowSecMidBltLockSt1 : 2|1@0+ (1,0) [0|1] ""  ZCUD
 SG_ BltLockStAtRowSecMidBltLockSts : 1|1@0+ (1,0) [0|1] ""  ZCUD
 SG_ BltLockStAtRowSecRi_UB : 12|1@0+ (1,0) [0|1] ""  ZCUD
 SG_ BltLockStAtRowSecRiBltLockEquid : 15|1@0+ (1,0) [0|1] ""  ZCUD
 SG_ BltLockStAtRowSecRiBltLockSt1 : 14|1@0+ (1,0) [0|1] ""  ZCUD
 SG_ BltLockStAtRowSecRiBltLockSts : 13|1@0+ (1,0) [0|1] ""  ZCUD
 SG_ BltLockStAtRowThrdLe_UB : 8|1@0+ (1,0) [0|1] ""  ZCUD
 SG_ BltLockStAtRowThrdLeBltLockEquid : 11|1@0+ (1,0) [0|1] ""  ZCUD
 SG_ BltLockStAtRowThrdLeBltLockSt1 : 10|1@0+ (1,0) [0|1] ""  ZCUD
 SG_ BltLockStAtRowThrdLeBltLockSts : 9|1@0+ (1,0) [0|1] ""  ZCUD
 SG_ BltLockStAtRowThrdRi_UB : 20|1@0+ (1,0) [0|1] ""  ZCUD
 SG_ BltLockStAtRowThrdRiBltLockEquid : 23|1@0+ (1,0) [0|1] ""  ZCUD
 SG_ BltLockStAtRowThrdRiBltLockSt1 : 22|1@0+ (1,0) [0|1] ""  ZCUD
 SG_ BltLockStAtRowThrdRiBltLockSts : 21|1@0+ (1,0) [0|1] ""  ZCUD
 SG_ RecOfPostImpctBrkgSuspc_UB : 41|1@0+ (1,0) [0|1] ""  ZCUD
 SG_ RecOfPostImpctBrkgSuspcChks : 39|8@0+ (1,0) [0|255] "Unitless"  ZCUD
 SG_ RecOfPostImpctBrkgSuspcCntr : 47|4@0+ (1,0) [0|15] "Unitless"  ZCUD
 SG_ RecOfPostImpctBrkgSuspcSuspcPost : 43|2@0+ (1,0) [0|3] ""  ZCUD

BO_ 559 SrsZCUDCAN1Fr11: 8 SRS3
 SG_ DstTrvldFromSftyBkp : 4|21@0+ (1,0) [0|2000000] "km"  ZCUD
 SG_ DstTrvldFromSftyBkp_UB : 30|1@0+ (1,0) [0|1] ""  ZCUD
 SG_ DstTrvldVldFromSftyBkp : 31|1@0+ (1,0) [0|1] ""  ZCUD
 SG_ DstTrvldVldFromSftyBkp_UB : 29|1@0+ (1,0) [0|1] ""  ZCUD
 SG_ NotifForEmgyCall : 27|1@0+ (1,0) [0|1] ""  ZCUD
 SG_ NotifForEmgyCall_UB : 26|1@0+ (1,0) [0|1] ""  ZCUD
 SG_ PassMidSeatSts : 7|2@0+ (1,0) [0|3] ""  ZCUD
 SG_ PassMidSeatSts_UB : 5|1@0+ (1,0) [0|1] ""  ZCUD
 SG_ SRSIntVolt : 39|8@0+ (0.1,0) [0|25.5] "Volt" Vector__XXX
 SG_ SRSIntVolt_UB : 28|1@0+ (1,0) [0|1] "" Vector__XXX

BO_ 328 SrsZCUDCAN1Fr12: 8 SRS3
 SG_ RecOfImpct2_UB : 21|1@0+ (1,0) [0|1] ""  ZCUD
 SG_ RecOfImpct2ImpctDvxSigned : 7|9@0+ (1,-255) [-255|257] "Km/h"  ZCUD
 SG_ RecOfImpct2ImpctDvySigned : 14|9@0+ (1,-255) [-255|257] "Km/h"  ZCUD
 SG_ RecOfPostImpctBrkgCfmd_UB : 30|1@0+ (1,0) [0|1] ""  ZCUD
 SG_ RecOfPostImpctBrkgCfmdChks : 63|8@0+ (1,0) [0|255] "Unitless"  ZCUD
 SG_ RecOfPostImpctBrkgCfmdCntr : 29|4@0+ (1,0) [0|15] "Unitless"  ZCUD
 SG_ RecOfPostImpctBrkgCfmdCrashFrnt : 25|2@0+ (1,0) [0|3] ""  ZCUD
 SG_ RecOfPostImpctBrkgCfmdCrashLarge : 39|2@0+ (1,0) [0|3] ""  ZCUD
 SG_ RecOfPostImpctBrkgCfmdCrashOffro : 37|2@0+ (1,0) [0|3] ""  ZCUD
 SG_ RecOfPostImpctBrkgCfmdCrash_0000 : 35|2@0+ (1,0) [0|3] ""  ZCUD
 SG_ RecOfPostImpctBrkgCfmdCrash_0001 : 33|2@0+ (1,0) [0|3] ""  ZCUD
 SG_ RecOfPostImpctBrkgCfmdCrash_0002 : 47|2@0+ (1,0) [0|3] ""  ZCUD
 SG_ RecOfPostImpctBrkgCfmdCrashOz : 45|2@0+ (1,0) [0|3] ""  ZCUD
 SG_ RecOfPostImpctBrkgCfmdCrashPed : 43|2@0+ (1,0) [0|3] ""  ZCUD
 SG_ RecOfPostImpctBrkgCfmdCrashRe : 41|2@0+ (1,0) [0|3] ""  ZCUD
 SG_ RecOfPostImpctBrkgCfmdCrashRollo : 55|2@0+ (1,0) [0|3] ""  ZCUD
 SG_ RecOfPostImpctBrkgCfmdCrashSideL : 53|2@0+ (1,0) [0|3] ""  ZCUD
 SG_ RecOfPostImpctBrkgCfmdCrashSideR : 51|2@0+ (1,0) [0|3] ""  ZCUD
 SG_ RecOfPostImpctBrkgCfmdPostImpctB : 49|2@0+ (1,0) [0|3] ""  ZCUD

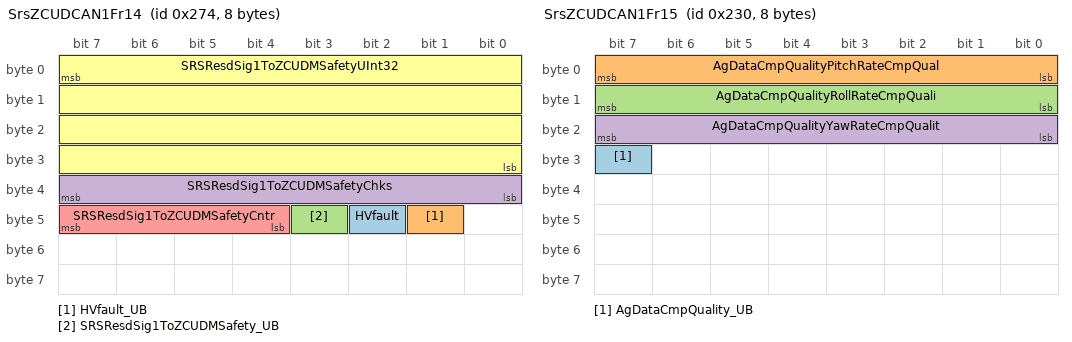
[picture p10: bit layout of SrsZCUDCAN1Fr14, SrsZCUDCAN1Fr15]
BO_ 628 SrsZCUDCAN1Fr14: 8 SRS3
 SG_ HVfault : 42|1@0+ (1,0) [0|1] ""  ZCUD
 SG_ HVfault_UB : 41|1@0+ (1,0) [0|1] ""  ZCUD
 SG_ SRSResdSig1ToZCUDMSafety_UB : 43|1@0+ (1,0) [0|1] ""  ZCUD
 SG_ SRSResdSig1ToZCUDMSafetyChks : 39|8@0+ (1,0) [0|255] "Unitless"  ZCUD
 SG_ SRSResdSig1ToZCUDMSafetyCntr : 47|4@0+ (1,0) [0|15] "Unitless"  ZCUD
 SG_ SRSResdSig1ToZCUDMSafetyUInt32 : 7|32@0+ (1,0) [0|4294967295] "Unitless"  ZCUD

BO_ 560 SrsZCUDCAN1Fr15: 8 SRS3
 SG_ AgDataCmpQuality_UB : 31|1@0+ (1,0) [0|1] ""  ZCUD
 SG_ AgDataCmpQualityPitchRateCmpQual : 7|8@0+ (1,0) [0|255] "Unitless"  ZCUD
 SG_ AgDataCmpQualityRollRateCmpQuali : 15|8@0+ (1,0) [0|255] "Unitless"  ZCUD
 SG_ AgDataCmpQualityYawRateCmpQualit : 23|8@0+ (1,0) [0|255] "Unitless"  ZCUD

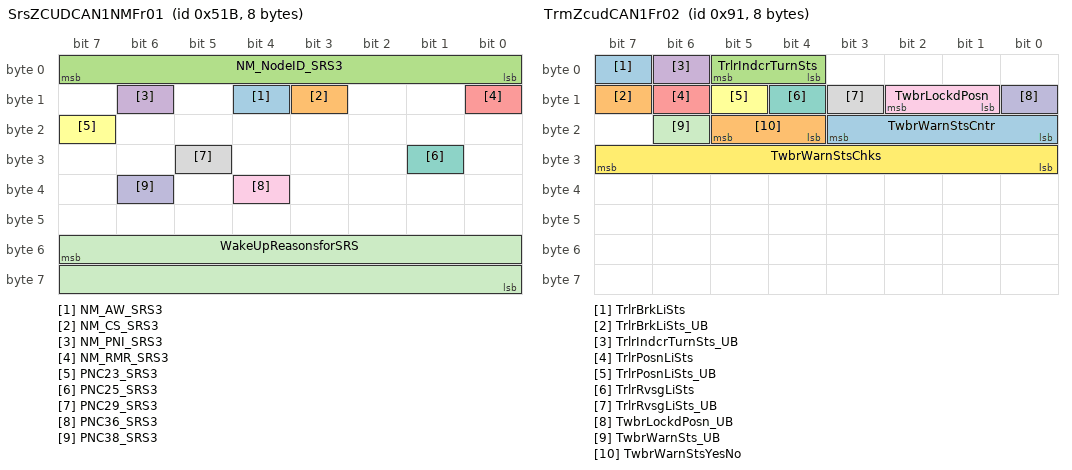
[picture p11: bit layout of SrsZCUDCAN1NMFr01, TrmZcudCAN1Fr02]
BO_ 1307 SrsZCUDCAN1NMFr01: 8 SRS3
 SG_ NM_AW_SRS3 : 12|1@0+ (1,0) [0|0] "" Vector__XXX
 SG_ NM_CS_SRS3 : 11|1@0+ (1,0) [0|0] "" Vector__XXX
 SG_ NM_NodeID_SRS3 : 7|8@0+ (1,0) [0|0] "" Vector__XXX
 SG_ NM_PNI_SRS3 : 14|1@0+ (1,0) [0|0] "" Vector__XXX
 SG_ NM_RMR_SRS3 : 8|1@0+ (1,0) [0|0] "" Vector__XXX
 SG_ PNC23_SRS3 : 23|1@0+ (1,0) [0|0] "" Vector__XXX
 SG_ PNC25_SRS3 : 25|1@0+ (1,0) [0|0] "" Vector__XXX
 SG_ PNC29_SRS3 : 29|1@0+ (1,0) [0|0] "" Vector__XXX
 SG_ PNC36_SRS3 : 36|1@0+ (1,0) [0|0] "" Vector__XXX
 SG_ PNC38_SRS3 : 38|1@0+ (1,0) [0|0] "" Vector__XXX
 SG_ WakeUpReasonsforSRS : 55|16@0+ (1,0) [0|65535] "" Vector__XXX

BO_ 1371 SrsZCUDCAN1VFCVectorFr: 8 SRS3
 SG_ VFCVectorSRSBlockID : 1|2@0+ (1,0) [0|3] "Unitless"  ZCUD
 SG_ VFCVectorSRSVFCid0 : 2|1@0+ (1,0) [0|1] ""  ZCUD
 SG_ VFCVectorSRSVFCid1 : 3|1@0+ (1,0) [0|1] ""  ZCUD
 SG_ VFCVectorSRSVFCid10 : 12|1@0+ (1,0) [0|1] ""  ZCUD
 SG_ VFCVectorSRSVFCid11 : 13|1@0+ (1,0) [0|1] ""  ZCUD
 SG_ VFCVectorSRSVFCid12 : 14|1@0+ (1,0) [0|1] ""  ZCUD
 SG_ VFCVectorSRSVFCid13 : 15|1@0+ (1,0) [0|1] ""  ZCUD
 SG_ VFCVectorSRSVFCid14 : 16|1@0+ (1,0) [0|1] ""  ZCUD
 SG_ VFCVectorSRSVFCid15 : 17|1@0+ (1,0) [0|1] ""  ZCUD
 SG_ VFCVectorSRSVFCid16 : 18|1@0+ (1,0) [0|1] ""  ZCUD
 SG_ VFCVectorSRSVFCid17 : 19|1@0+ (1,0) [0|1] ""  ZCUD
 SG_ VFCVectorSRSVFCid18 : 20|1@0+ (1,0) [0|1] ""  ZCUD
 SG_ VFCVectorSRSVFCid19 : 21|1@0+ (1,0) [0|1] ""  ZCUD
 SG_ VFCVectorSRSVFCid2 : 4|1@0+ (1,0) [0|1] ""  ZCUD
 SG_ VFCVectorSRSVFCid20 : 22|1@0+ (1,0) [0|1] ""  ZCUD
 SG_ VFCVectorSRSVFCid21 : 23|1@0+ (1,0) [0|1] ""  ZCUD
 SG_ VFCVectorSRSVFCid22 : 24|1@0+ (1,0) [0|1] ""  ZCUD
 SG_ VFCVectorSRSVFCid23 : 25|1@0+ (1,0) [0|1] ""  ZCUD
 SG_ VFCVectorSRSVFCid24 : 26|1@0+ (1,0) [0|1] ""  ZCUD
 SG_ VFCVectorSRSVFCid25 : 27|1@0+ (1,0) [0|1] ""  ZCUD
 SG_ VFCVectorSRSVFCid26 : 28|1@0+ (1,0) [0|1] ""  ZCUD
 SG_ VFCVectorSRSVFCid27 : 29|1@0+ (1,0) [0|1] ""  ZCUD
 SG_ VFCVectorSRSVFCid28 : 30|1@0+ (1,0) [0|1] ""  ZCUD
 SG_ VFCVectorSRSVFCid29 : 31|1@0+ (1,0) [0|1] ""  ZCUD
 SG_ VFCVectorSRSVFCid3 : 5|1@0+ (1,0) [0|1] ""  ZCUD
 SG_ VFCVectorSRSVFCid30 : 32|1@0+ (1,0) [0|1] ""  ZCUD
 SG_ VFCVectorSRSVFCid31 : 33|1@0+ (1,0) [0|1] ""  ZCUD
 SG_ VFCVectorSRSVFCid32 : 34|1@0+ (1,0) [0|1] ""  ZCUD
 SG_ VFCVectorSRSVFCid33 : 35|1@0+ (1,0) [0|1] ""  ZCUD
 SG_ VFCVectorSRSVFCid34 : 36|1@0+ (1,0) [0|1] ""  ZCUD
 SG_ VFCVectorSRSVFCid35 : 37|1@0+ (1,0) [0|1] ""  ZCUD
 SG_ VFCVectorSRSVFCid36 : 38|1@0+ (1,0) [0|1] ""  ZCUD
 SG_ VFCVectorSRSVFCid37 : 39|1@0+ (1,0) [0|1] ""  ZCUD
 SG_ VFCVectorSRSVFCid38 : 40|1@0+ (1,0) [0|1] ""  ZCUD
 SG_ VFCVectorSRSVFCid39 : 41|1@0+ (1,0) [0|1] ""  ZCUD
 SG_ VFCVectorSRSVFCid4 : 6|1@0+ (1,0) [0|1] ""  ZCUD
 SG_ VFCVectorSRSVFCid40 : 42|1@0+ (1,0) [0|1] ""  ZCUD
 SG_ VFCVectorSRSVFCid41 : 43|1@0+ (1,0) [0|1] ""  ZCUD
 SG_ VFCVectorSRSVFCid42 : 44|1@0+ (1,0) [0|1] ""  ZCUD
 SG_ VFCVectorSRSVFCid43 : 45|1@0+ (1,0) [0|1] ""  ZCUD
 SG_ VFCVectorSRSVFCid44 : 46|1@0+ (1,0) [0|1] ""  ZCUD
 SG_ VFCVectorSRSVFCid45 : 47|1@0+ (1,0) [0|1] ""  ZCUD
 SG_ VFCVectorSRSVFCid46 : 48|1@0+ (1,0) [0|1] ""  ZCUD
 SG_ VFCVectorSRSVFCid47 : 49|1@0+ (1,0) [0|1] ""  ZCUD
 SG_ VFCVectorSRSVFCid48 : 50|1@0+ (1,0) [0|1] ""  ZCUD
 SG_ VFCVectorSRSVFCid49 : 51|1@0+ (1,0) [0|1] ""  ZCUD
 SG_ VFCVectorSRSVFCid5 : 7|1@0+ (1,0) [0|1] ""  ZCUD
 SG_ VFCVectorSRSVFCid50 : 52|1@0+ (1,0) [0|1] ""  ZCUD
 SG_ VFCVectorSRSVFCid51 : 53|1@0+ (1,0) [0|1] ""  ZCUD
 SG_ VFCVectorSRSVFCid52 : 54|1@0+ (1,0) [0|1] ""  ZCUD
 SG_ VFCVectorSRSVFCid53 : 55|1@0+ (1,0) [0|1] ""  ZCUD
 SG_ VFCVectorSRSVFCid54 : 56|1@0+ (1,0) [0|1] ""  ZCUD
 SG_ VFCVectorSRSVFCid55 : 57|1@0+ (1,0) [0|1] ""  ZCUD
 SG_ VFCVectorSRSVFCid56 : 58|1@0+ (1,0) [0|1] ""  ZCUD
 SG_ VFCVectorSRSVFCid57 : 59|1@0+ (1,0) [0|1] ""  ZCUD
 SG_ VFCVectorSRSVFCid58 : 60|1@0+ (1,0) [0|1] ""  ZCUD
 SG_ VFCVectorSRSVFCid59 : 61|1@0+ (1,0) [0|1] ""  ZCUD
 SG_ VFCVectorSRSVFCid6 : 8|1@0+ (1,0) [0|1] ""  ZCUD
 SG_ VFCVectorSRSVFCid60 : 62|1@0+ (1,0) [0|1] ""  ZCUD
 SG_ VFCVectorSRSVFCid61 : 63|1@0+ (1,0) [0|1] ""  ZCUD
 SG_ VFCVectorSRSVFCid7 : 9|1@0+ (1,0) [0|1] ""  ZCUD
 SG_ VFCVectorSRSVFCid8 : 10|1@0+ (1,0) [0|1] ""  ZCUD
 SG_ VFCVectorSRSVFCid9 : 11|1@0+ (1,0) [0|1] ""  ZCUD

BO_ 1464 TrmtoEtcXcpFr01: 8 TRM

BO_ 1559 TrmToZcudZCUDCAN1DiagResFrame: 8 TRM
 SG_ TrmToZcudZCUDCAN1DiagResNpdu : 7|64@0+ (1,0) [0|0] ""  ZCUD

BO_ 208 TrmZcudCAN1Fr01: 4 TRM
 SG_ TrlrFogLiSts : 17|1@0+ (1,0) [0|1] ""  ZCUD
 SG_ TrlrFogLiSts_UB : 16|1@0+ (1,0) [0|1] ""  ZCUD
 SG_ TrlrLampActvtChk : 15|1@0+ (1,0) [0|1] ""  ZCUD
 SG_ TrlrLampActvtChk_UB : 8|1@0+ (1,0) [0|1] ""  ZCUD
 SG_ TrlrLampChkSts : 7|3@0+ (1,0) [0|7] ""  ZCUD
 SG_ TrlrLampChkSts_UB : 23|1@0+ (1,0) [0|1] ""  ZCUD
 SG_ TrlrLeIndcrFltSts : 1|1@0+ (1,0) [0|1] ""  ZCUD
 SG_ TrlrLeIndcrFltSts_UB : 10|1@0+ (1,0) [0|1] ""  ZCUD
 SG_ TrlrLiFltSts : 4|3@0+ (1,0) [0|7] ""  ZCUD
 SG_ TrlrLiFltSts_UB : 22|1@0+ (1,0) [0|1] ""  ZCUD
 SG_ TrlrPrmntPwrActv : 14|1@0+ (1,0) [0|1] ""  ZCUD
 SG_ TrlrPrmntPwrActv_UB : 21|1@0+ (1,0) [0|1] ""  ZCUD
 SG_ TrlrPrsnt : 13|1@0+ (1,0) [0|1] ""  ZCUD
 SG_ TrlrPrsnt_UB : 20|1@0+ (1,0) [0|1] ""  ZCUD
 SG_ TrlrRiIndcrFltSts : 0|1@0+ (1,0) [0|1] ""  ZCUD
 SG_ TrlrRiIndcrFltSts_UB : 9|1@0+ (1,0) [0|1] ""  ZCUD
 SG_ TrlrSrvReq : 12|1@0+ (1,0) [0|1] ""  ZCUD
 SG_ TrlrSrvReq_UB : 19|1@0+ (1,0) [0|1] ""  ZCUD

BO_ 145 TrmZcudCAN1Fr02: 8 TRM
 SG_ TrlrBrkLiSts : 7|1@0+ (1,0) [0|1] ""  ZCUD
 SG_ TrlrBrkLiSts_UB : 15|1@0+ (1,0) [0|1] ""  ZCUD
 SG_ TrlrIndcrTurnSts : 5|2@0+ (1,0) [0|3] ""  ZCUD
 SG_ TrlrIndcrTurnSts_UB : 6|1@0+ (1,0) [0|1] ""  ZCUD
 SG_ TrlrPosnLiSts : 14|1@0+ (1,0) [0|1] ""  ZCUD
 SG_ TrlrPosnLiSts_UB : 13|1@0+ (1,0) [0|1] ""  ZCUD
 SG_ TrlrRvsgLiSts : 12|1@0+ (1,0) [0|1] ""  ZCUD
 SG_ TrlrRvsgLiSts_UB : 11|1@0+ (1,0) [0|1] ""  ZCUD
 SG_ TwbrLockdPosn : 10|2@0+ (1,0) [0|3] ""  ZCUD
 SG_ TwbrLockdPosn_UB : 8|1@0+ (1,0) [0|1] ""  ZCUD
 SG_ TwbrWarnSts_UB : 22|1@0+ (1,0) [0|1] ""  ZCUD
 SG_ TwbrWarnStsChks : 31|8@0+ (1,0) [0|255] "Unitless"  ZCUD
 SG_ TwbrWarnStsCntr : 19|4@0+ (1,0) [0|15] "Unitless"  ZCUD
 SG_ TwbrWarnStsYesNo : 21|2@0+ (1,0) [0|3] ""  ZCUD

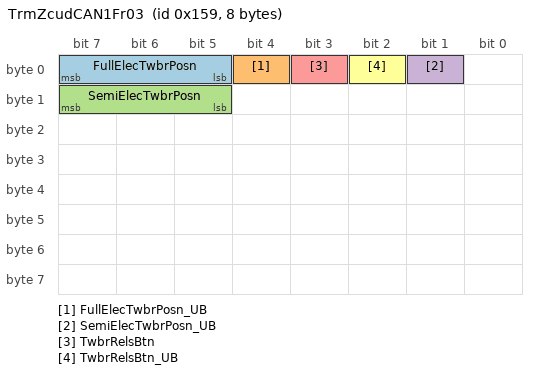
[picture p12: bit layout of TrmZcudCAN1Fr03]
BO_ 345 TrmZcudCAN1Fr03: 8 TRM
 SG_ FullElecTwbrPosn : 7|3@0+ (1,0) [0|7] ""  ZCUD
 SG_ FullElecTwbrPosn_UB : 4|1@0+ (1,0) [0|1] ""  ZCUD
 SG_ SemiElecTwbrPosn : 15|3@0+ (1,0) [0|7] ""  ZCUD
 SG_ SemiElecTwbrPosn_UB : 1|1@0+ (1,0) [0|1] ""  ZCUD
 SG_ TwbrRelsBtn : 3|1@0+ (1,0) [0|1] ""  ZCUD
 SG_ TwbrRelsBtn_UB : 2|1@0+ (1,0) [0|1] ""  ZCUD

CM_ BU_ ETC "External Tester Connector";
CM_ BU_ TRM "Trailer Module";
CM_ SG_ 406 DoorSldngLeReOpenEnaSts "left sliding door open enable status according to  Lid status";
CM_ SG_ 406 DoorSldngRiReOpenEnaSts "Right sliding door open enable status according to  Lid status";
CM_ SG_ 406 SecRowLeSeatMotPosnCalReq "SecRowLeSeatMotPosnCalReq";
CM_ SG_ 406 SecRowRiSeatMotPosnCalReq "SecRowRiSeatMotPosnCalReq";
CM_ SG_ 81 PwrSldgDoorLePosnReqFromHmi "Control the left power sliding door 0-100% position status";
CM_ SG_ 81 PwrSldgDoorRiPosnReqFromHmi "Control the right power sliding door 0-100% position status";
CM_ SG_ 962 SRSdevelpsignalgroupRXFunctionde "SRS development signal";
CM_ SG_ 962 SRSdevelpsignalgroupRXFunct_0000 "SRS development signal";
CM_ SG_ 962 SRSdevelpsignalgroupRXFunct_0001 "SRS development signal";
CM_ SG_ 962 SRSdevelpsignalgroupRXFunct_0002 "SRS development signal";
CM_ SG_ 962 SRSdevelpsignalgroupRXFunct_0003 "SRS development signal";
CM_ SG_ 962 SRSdevelpsignalgroupRXFunct_0004 "SRS development signal";
CM_ SG_ 962 SRSdevelpsignalgroupRXFunct_0005 "SRS development signal";
CM_ SG_ 962 SRSdevelpsignalgroupRXFunct_0006 "SRS development signal";
CM_ SG_ 897 AltitudeInfrom "AltitudeInfrom information";
CM_ SG_ 897 OGMIntErr "GOM internal fault";
CM_ SG_ 897 OGMOvrVoltRangErr "OGM over voltage ranger error";
CM_ SG_ 897 OGMTempErr "OGM temperature range error";
CM_ SG_ 897 OGMUndVoltRangErr "OGM under voltage range error";
CM_ SG_ 897 OxygenGenrErrInfo "Oxygen generation error information";
CM_ SG_ 897 OxygenSplyAvlSts "Oxygen supply module actual status";
CM_ SG_ 897 OxygenSplyErr "Oxygen supply error status";
CM_ SG_ 769 OGMMissingSlaveSignal "OGM missing slave signal";
CM_ SG_ 720 BusCurrentFb "Bus current feedback";
CM_ SG_ 720 InpVoltFb "Input voltage feedback";
CM_ SG_ 720 McuTempFb "mcu temperature feedback";
CM_ SG_ 720 MotTempFb "Motor temperature value feedback";
CM_ SG_ 724 MosTempFb "mos temperature feedback";
CM_ SG_ 724 OGMCmprSpdFb "OGM Compressor Speed feedback";
CM_ SG_ 724 PhaseCurrentFb "Phase current feedback";
CM_ SG_ 724 PressureFb "Pressure feedback";
CM_ SG_ 730 BackflushVlvErr "The back-blowing valve is faulty";
CM_ SG_ 730 ChgFilElmWarn "Reminder for filter element replacement";
CM_ SG_ 730 CoolgFanErr "Cooling fan failure";
CM_ SG_ 730 McuOvrTempErr "Mcu Excessive temperature";
CM_ SG_ 730 McuTempSnsrErr "Mcu temperature sensor failure";
CM_ SG_ 730 MosOvrTempErr "Mos Excessive temperature";
CM_ SG_ 730 MosTempSnsrErr "MOS temperature sensor failure";
CM_ SG_ 730 MotTempSnsrErr "Motor temperature sensor failure";
CM_ SG_ 730 OxygenConcFlt "The oxygen concentration in the oxygen generator is abnormal";
CM_ SG_ 730 OxygenTubeBlk "The oxygen inhalation tube is clogged";
CM_ SG_ 730 PressureFlt "Abnormal pressure";
CM_ SG_ 730 PressureSnsrErr "Pressure sensor failure";
CM_ SG_ 730 VlvVoltFlt "Abnormal working voltage of the valve";
CM_ SG_ 741 MotStsFrmOGM "Motor status";
CM_ SG_ 741 OGMRunTi "The total operating time of the oxygen generator";
CM_ SG_ 741 OxygenConcFbFrmOGM "The status of the oxygen concentration sensor in the oxygen generator";
CM_ SG_ 741 OxygenConcSnsrStsFrmOGM "Oxygen concentration feedback from the oxygen generator";
CM_ SG_ 747 MoleculeVlv1 "Molecular sieve valve 1 failure";
CM_ SG_ 747 MoleculeVlv2 "Molecular sieve valve 2 failure";
CM_ SG_ 747 OGMFlowFb "Oxygen generator flow feedback";
CM_ SG_ 747 OGMHwVers "Hardware version number";
CM_ SG_ 747 OGMSwVers "Software version number";
CM_ SG_ 704 OxygenSplyDesPwrCns "power consumption for oxygen sulply.";
CM_ SG_ 1329 WakeUpReasonsforOGM "ECUWakeupReasons";
CM_ SG_ 1346 VFCVectorOGMBlockID "BlockID";
CM_ SG_ 1346 VFCVectorOGMVFCid0 "SettingsComfort";
CM_ SG_ 1346 VFCVectorOGMVFCid1 "ParkingDrivingClimatization";
CM_ SG_ 1346 VFCVectorOGMVFCid10 "ExteriorLighting";
CM_ SG_ 1346 VFCVectorOGMVFCid11 "VFC11";
CM_ SG_ 1346 VFCVectorOGMVFCid12 "Alarm";
CM_ SG_ 1346 VFCVectorOGMVFCid13 "VFC13";
CM_ SG_ 1346 VFCVectorOGMVFCid14 "InteriorLighting";
CM_ SG_ 1346 VFCVectorOGMVFCid15 "VFC15";
CM_ SG_ 1346 VFCVectorOGMVFCid16 "Locking";
CM_ SG_ 1346 VFCVectorOGMVFCid17 "RemoteKeyFunctionality";
CM_ SG_ 1346 VFCVectorOGMVFCid18 "PropulsionStart";
CM_ SG_ 1346 VFCVectorOGMVFCid19 "VFC19";
CM_ SG_ 1346 VFCVectorOGMVFCid2 "PostClimatisation";
CM_ SG_ 1346 VFCVectorOGMVFCid20 "VFC20";
CM_ SG_ 1346 VFCVectorOGMVFCid21 "PowerClosures";
CM_ SG_ 1346 VFCVectorOGMVFCid22 "VehicleDriving";
CM_ SG_ 1346 VFCVectorOGMVFCid23 "VFC23";
CM_ SG_ 1346 VFCVectorOGMVFCid24 "SettingsProfile";
CM_ SG_ 1346 VFCVectorOGMVFCid25 "SeatComfortFunctions";
CM_ SG_ 1346 VFCVectorOGMVFCid26 "Brake";
CM_ SG_ 1346 VFCVectorOGMVFCid27 "InfotainmentPoll";
CM_ SG_ 1346 VFCVectorOGMVFCid28 "HVEnergyStorage";
CM_ SG_ 1346 VFCVectorOGMVFCid29 "VFC29";
CM_ SG_ 1346 VFCVectorOGMVFCid3 "PowertrainParkingClimatization";
CM_ SG_ 1346 VFCVectorOGMVFCid30 "TelematicsConnectivity";
CM_ SG_ 1346 VFCVectorOGMVFCid31 "VFC31";
CM_ SG_ 1346 VFCVectorOGMVFCid32 "VFC32";
CM_ SG_ 1346 VFCVectorOGMVFCid33 "Diagnostics";
CM_ SG_ 1346 VFCVectorOGMVFCid34 "VehicleModeManagement";
CM_ SG_ 1346 VFCVectorOGMVFCid35 "TrailerCaravanFunctions";
CM_ SG_ 1346 VFCVectorOGMVFCid36 "Immobilizer";
CM_ SG_ 1346 VFCVectorOGMVFCid37 "Windows";
CM_ SG_ 1346 VFCVectorOGMVFCid38 "Visibility";
CM_ SG_ 1346 VFCVectorOGMVFCid39 "VFC39";
CM_ SG_ 1346 VFCVectorOGMVFCid4 "VFC4";
CM_ SG_ 1346 VFCVectorOGMVFCid40 "VFC40";
CM_ SG_ 1346 VFCVectorOGMVFCid41 "InfotainmentPush";
CM_ SG_ 1346 VFCVectorOGMVFCid42 "ChargingHV";
CM_ SG_ 1346 VFCVectorOGMVFCid43 "BodyPreClimatisation";
CM_ SG_ 1346 VFCVectorOGMVFCid44 "Crash";
CM_ SG_ 1346 VFCVectorOGMVFCid45 "GlobalShortDuration";
CM_ SG_ 1346 VFCVectorOGMVFCid46 "ExteriorLightsHazard";
CM_ SG_ 1346 VFCVectorOGMVFCid47 "VFC47";
CM_ SG_ 1346 VFCVectorOGMVFCid48 "DoorOpenWarning";
CM_ SG_ 1346 VFCVectorOGMVFCid49 "ChargingLVInit";
CM_ SG_ 1346 VFCVectorOGMVFCid5 "VFC5";
CM_ SG_ 1346 VFCVectorOGMVFCid50 "VFC50";
CM_ SG_ 1346 VFCVectorOGMVFCid51 "VFC51";
CM_ SG_ 1346 VFCVectorOGMVFCid52 "HVBatteryThermalEventWarning";
CM_ SG_ 1346 VFCVectorOGMVFCid53 "VisualAssist";
CM_ SG_ 1346 VFCVectorOGMVFCid54 "PassiveSafety";
CM_ SG_ 1346 VFCVectorOGMVFCid55 "LifeDetection";
CM_ SG_ 1346 VFCVectorOGMVFCid56 "BackboneFlexray";
CM_ SG_ 1346 VFCVectorOGMVFCid57 "Functionmarket";
CM_ SG_ 1346 VFCVectorOGMVFCid58 "VFCid58";
CM_ SG_ 1346 VFCVectorOGMVFCid59 "VFCid59";
CM_ SG_ 1346 VFCVectorOGMVFCid6 "SettingsVehicle";
CM_ SG_ 1346 VFCVectorOGMVFCid60 "VFCid60";
CM_ SG_ 1346 VFCVectorOGMVFCid61 "VFCid61";
CM_ SG_ 1346 VFCVectorOGMVFCid7 "VFC7";
CM_ SG_ 1346 VFCVectorOGMVFCid8 "VFC8";
CM_ SG_ 1346 VFCVectorOGMVFCid9 "IPWakeup";
CM_ SG_ 416 TrCrashUnlckSts "Signal of trunk unlock position status";
CM_ SG_ 149 TrInsdOpenSwtSts "Trunk inside opening switch status";
CM_ SG_ 578 TrCinhSwt "Trunk cinch reset switch status";
CM_ SG_ 578 TrLatPosn "Trunk latch position, contains fully closed, secondary position, fully opened.";
CM_ SG_ 803 SecRowLeHeatgLvl "Second row left heating level.";
CM_ SG_ 803 SecRowLeVentnLvl "Second row left ventilation level.";
CM_ SG_ 262 RowReLeModSwtSts "Indicate the rear row lin switch is used to control second row seat or third row seat";
CM_ SG_ 261 RowReRiModSwtSts "Indicate the rear row lin switch is used to control second row seat or third row seat";
CM_ SG_ 961 SRSdevelpsignalgroupTXFunctionde "SRS development signal";
CM_ SG_ 961 SRSdevelpsignalgroupTXFunct_0000 "SRS development signal";
CM_ SG_ 961 SRSdevelpsignalgroupTXFunct_0001 "SRS development signal";
CM_ SG_ 961 SRSdevelpsignalgroupTXFunct_0002 "SRS development signal";
CM_ SG_ 961 SRSdevelpsignalgroupTXFunct_0003 "SRS development signal";
CM_ SG_ 961 SRSdevelpsignalgroupTXFunct_0004 "SRS development signal";
CM_ SG_ 961 SRSdevelpsignalgroupTXFunct_0005 "SRS development signal";
CM_ SG_ 961 SRSdevelpsignalgroupTXFunct_0006 "SRS development signal";
CM_ SG_ 137 AgDataRawSafeChks "IMU angular rate data. Check summa";
CM_ SG_ 137 AgDataRawSafeCntr "IMU angular rate data. Counter";
CM_ SG_ 137 AgDataRawSafeRollRate "IMU angular rate data. Roll Rate";
CM_ SG_ 137 AgDataRawSafeRollRateQf "IMU angular rate data. Quality factor for Roll Rate";
CM_ SG_ 137 AgDataRawSafeYawRate "IMU angular rate data. Yaw Rate";
CM_ SG_ 137 AgDataRawSafeYawRateQf "IMU angular rate data. Quality Factor for Yaw Rate";
CM_ SG_ 137 BltLockStAtDrvrBltLockSt1 "State of belt lock at driver seating position Belt lock state, locked/unlocked";
CM_ SG_ 137 BltLockStAtDrvrBltLockSts "State of belt lock at driver seating position Belt lock status, OK/NOK";
CM_ SG_ 137 BltLockStAtPassBltLockSt1 "State of belt lock at passenger seating position Belt lock state, locked/unlocked";
CM_ SG_ 137 BltLockStAtPassBltLockSts "State of belt lock at passenger seating position Belt lock status, OK/NOK";
CM_ SG_ 16 CrashStsSafeChks "Checksum for E2E";
CM_ SG_ 16 CrashStsSafeCntr "Counter for E2E";
CM_ SG_ 16 CrashStsSafeSts "Information if a crash has been detected by SRS.";
CM_ SG_ 16 PassAirbStsChgNotifReq "Request for a popup window notification to promot user to change the passenger airbag status.";
CM_ SG_ 18 ADataRawSafeALat "IMU acceleration data Lateral acceleration";
CM_ SG_ 18 ADataRawSafeALat1Qf "IMU acceleration data Quality factor for Lateral acceleration signal";
CM_ SG_ 18 ADataRawSafeALgt "IMU acceleration data Longitudinal acceleration";
CM_ SG_ 18 ADataRawSafeALgt1Qf "IMU acceleration data Quality factor for Longitudinal acceleration";
CM_ SG_ 18 ADataRawSafeAVert "IMU acceleration data Vertical acceleration";
CM_ SG_ 18 ADataRawSafeAVertQf "IMU acceleration data Quality factor for Vertical acceleration";
CM_ SG_ 18 ADataRawSafeChks "IMU acceleration data Check sum";
CM_ SG_ 18 ADataRawSafeCntr "IMU acceleration data Counter";
CM_ SG_ 19 AsyDataWithCmpSafeALat1Qf "IMU processed special data. Quality factor for Lateral acceleration signal";
CM_ SG_ 19 AsyDataWithCmpSafeALatWithCmp "IMU processed special data.  Compensated Lateral acceleration";
CM_ SG_ 19 AsyDataWithCmpSafeALgt1Qf "IMU processed special data. Quality factor for Longitudinal acceleration";
CM_ SG_ 19 AsyDataWithCmpSafeChks "IMU processed special data. Check sum";
CM_ SG_ 19 AsyDataWithCmpSafeCntr "IMU processed special data. Counter";
CM_ SG_ 19 AsyDataWithCmpSafeGrdtOfALgt "IMU processed special data. Derivative of Longitudinal acceleration";
CM_ SG_ 19 AsyDataWithCmpSafeYawRateQf "IMU processed special data. Quality Factor for Yaw Rate";
CM_ SG_ 19 AsyDataWithCmpSafeYawRateWithCmp "IMU processed special data. Compensated Yaw rate";
CM_ SG_ 33 ActvnReqOfRtrctrRvsbLe "Belt pre-tensioning request from the DART/CWS algo in the SRS.";
CM_ SG_ 33 ActvnReqOfRtrctrRvsbRi "Belt pre-tensioning request from the DART/CWS algo in the SRS.";
CM_ SG_ 33 BltLockStSafeAtDrvrBltLockSt1 "State of belt lock at driver seating position Belt lock state, locked/unlocked";
CM_ SG_ 33 BltLockStSafeAtDrvrBltLockStErrS "State of belt lock at driver seating position Belt lock status, OK/NOK";
CM_ SG_ 33 BltLockStSafeAtDrvrChks "Counter for E2E";
CM_ SG_ 33 BltLockStSafeAtDrvrCntr "Checksum for E2E";
CM_ SG_ 33 BrkPedlSts "If the brake pedal decoupling has been activated.";
CM_ SG_ 33 CrashSts2 "Information if a crash or slight crash has been detected by SRS.";
CM_ SG_ 549 BltLockStAtPassMidBltLockEquid "Belt lock state at 1st row middle passenger seat position. Signal gives out if the belt lock sensor is equipped or not.";
CM_ SG_ 549 BltLockStAtPassMidBltLockSt1 "Belt lock state at 1st row middle passenger seat position. Signal gives out if the belt lock is locked or unlocked. ";
CM_ SG_ 549 BltLockStAtPassMidBltLockSts "Belt lock state at 1st row middle passenger seat position. Signal gives out if the belt lock is faulty or not.";
CM_ SG_ 549 BltLockStAtRowFrthLeBltLockEquid "Signal gives out if belt lock detection sensor is equipped at the 4th row outer left seat.";
CM_ SG_ 549 BltLockStAtRowFrthLeBltLockSt1 "Belt lock state at 4th row outer left seat posiiton. Signal gives out if the belt lock is locked or unlocked. ";
CM_ SG_ 549 BltLockStAtRowFrthLeBltLockSts "Belt lock fault status at the 4th row outer left seat. Signal gives out if belt lock is faulty or not.";
CM_ SG_ 549 BltLockStAtRowFrthMidBltLockEqui "Signal gives out if belt lock detection sensor is equipped at the 4th row middle seat.";
CM_ SG_ 549 BltLockStAtRowFrthMidBltLockSt1 "Belt lock state at 4th row middle seat posiiton. Signal gives out if the belt lock is locked or unlocked.";
CM_ SG_ 549 BltLockStAtRowFrthMidBltLockSts "Belt lock fault status at the 4th row  middle seat. Signal gives out if belt lock is faulty or not.";
CM_ SG_ 549 BltLockStAtRowFrthRiBltLockEquid "Signal gives out if belt lock detection sensor is equipped at the 4th row outer right seat.";
CM_ SG_ 549 BltLockStAtRowFrthRiBltLockSt1 "Belt lock state at 4th row outer right seat posiiton. Signal gives out if the belt lock is locked or unlocked.";
CM_ SG_ 549 BltLockStAtRowFrthRiBltLockSts "Belt lock fault status at the 4th row outer right seat. Signal gives out if belt lock is faulty or not.";
CM_ SG_ 549 BltLockStAtRowThrdMidBltLockEqui "State of belt lock at seating position at middle third row If the belt lock is equipped";
CM_ SG_ 549 BltLockStAtRowThrdMidBltLockSt1 "State of belt lock at seating position at middle third row Belt lock state,  locked/unlocked";
CM_ SG_ 549 BltLockStAtRowThrdMidBltLockSts "State of belt lock at seating position at middle third row Belt lock status, OK/NOK";
CM_ SG_ 549 SeatOccptAtRowFrthLe "Occupation status based on occupant detection sensor at the 4th row outer left seat. ";
CM_ SG_ 549 SeatOccptAtRowFrthMid "Occupation status based on occupant detection sensor at the 4th middle seat. ";
CM_ SG_ 549 SeatOccptAtRowFrthRi "Occupation status based on occupant detection sensor at the 4th row outer right seat. ";
CM_ SG_ 549 SeatOccptAtRowThrdMid "Occupant presence status at 3rd row ,  right position.";
CM_ SG_ 322 AgDataRaw2SafeChks "IMU pitch rate data. Check sum";
CM_ SG_ 322 AgDataRaw2SafeCntr "IMU pitch rate data. Counter";
CM_ SG_ 322 AgDataRaw2SafePitchRate "IMU pitch rate data. Pitch Rate";
CM_ SG_ 322 AgDataRaw2SafePitchRateQf "IMU pitch rate data. Quality factor for Pitch Rate";
CM_ SG_ 322 PassAirbLampReqChgOfPassAirbSts "Indication request for passenger airbag lamp status. Reqest for indication of passenger airbag status in DIM";
CM_ SG_ 322 PassAirbLampReqChks "Indication request for passenger airbag lamp status. Checksum for validity check of PAD and PAE request messages";
CM_ SG_ 322 PassAirbLampReqCntr "Indication request for passenger airbag lamp status. Counter for validity check of PAD and PAE request messages";
CM_ SG_ 322 PassAirbLampReqPassAirbLampDiReq "Indication request for passenger airbag lamp status. Requested status for PAD lamp";
CM_ SG_ 322 PassAirbLampReqPassAirbLampEnaRe "Indication request for passenger airbag lamp status. Requested status for PAE Lamp";
CM_ SG_ 322 ReqForAsyDataStorgFromRestrntSys "ASY Data Storg from restrn system";
CM_ SG_ 322 ReqForHzrdInt "0-Lower crash not happen 
1-Lower crash happened";
CM_ SG_ 322 SftyAirbRollovrSuppSts "Roll-over deactivation actual state";
CM_ SG_ 554 JIDByte0 "IMU identification number. Byte0";
CM_ SG_ 554 JIDByte1 "IMU identification number. Byte1";
CM_ SG_ 554 JIDByte2 "IMU identification number. Byte2";
CM_ SG_ 554 JIDByte3 "IMU identification number. Byte3";
CM_ SG_ 554 JIDByte4 "IMU identification number. Byte4";
CM_ SG_ 554 JIDByte5 "IMU identification number. Byte5";
CM_ SG_ 554 JIDByte6 "IMU identification number. Byte6";
CM_ SG_ 554 JIDByte7 "IMU identification number. Byte7";
CM_ SG_ 864 BltCrashNotifDrvr "Status signal for driver belt pyrotechnic activation.";
CM_ SG_ 864 BltCrashNotifPass "Status signal for passenger belt pyrotechnic activation.";
CM_ SG_ 864 PassAirbSts "Passenger airbag status, based on PACOS input.";
CM_ SG_ 864 PedProtnMsgReqForFlt "Indication request for pedestrian protection faults.";
CM_ SG_ 864 PedProtnMsgReqForImpct "Text message request to inform about triggering of the pedestrian protection system.";
CM_ SG_ 864 RecOfImpctCrashFrnt "Crash information, if crash is frontal";
CM_ SG_ 864 RecOfImpctCrashOffroadA "Incident information, if driving off road and becoming airbourne has been detected.";
CM_ SG_ 864 RecOfImpctCrashOffroadD "Inicdent information, if driving into a ditch has been detected";
CM_ SG_ 864 RecOfImpctCrashOffroadRT "Incident information, if driving off the road and into rough terrain has been detected.";
CM_ SG_ 864 RecOfImpctCrashOffroadRTsevere "Incident information, if driving off road and into severe rough terrain has been detected.";
CM_ SG_ 864 RecOfImpctCrashPed "Incident information, if a pedestrian protection triggering has been made";
CM_ SG_ 864 RecOfImpctCrashRe "Crash information, if crash is rear";
CM_ SG_ 864 RecOfImpctCrashRollovr "Crash information, if crash is roll-over";
CM_ SG_ 864 RecOfImpctCrashSideLe "Crash information, if crash is left side";
CM_ SG_ 864 RecOfImpctCrashSideRi "Crash information, if crash is right side";
CM_ SG_ 864 RecOfImpctCrashState "Crash information, State of the crash";
CM_ SG_ 864 RecOfImpctImpctDvx "Crash information, change in velocity in x-direction";
CM_ SG_ 864 RecOfImpctImpctDvy "Crash information, change in velocity in y-direction";
CM_ SG_ 864 RecOfImpctImpctRollAg "Crash information, cumulative roll angle";
CM_ SG_ 864 RecOfImpctVehOri "Crash information, Vehicle orientation once crash subsides";
CM_ SG_ 864 RestrntSysLampReq "Indication request for SRS faults.";
CM_ SG_ 864 RestrntSysMsgReq "Text message request for SRS faults.";
CM_ SG_ 864 SafetyCrashFb "If brake pedal has been disconnected after a crash it is NOK, else OK after crash.";
CM_ SG_ 112 BltLockStAtRowSecLeBltLockEquid "State of belt lock at seating position at left of second row If the belt lock is equipped";
CM_ SG_ 112 BltLockStAtRowSecLeBltLockSt1 "State of belt lock at seating position at left of second row Belt lock state,  locked/unlocked";
CM_ SG_ 112 BltLockStAtRowSecLeBltLockSts "State of belt lock at seating position at left of second row Belt lock status, OK/NOK";
CM_ SG_ 112 BltLockStAtRowSecMidBltLockEquid "State of belt lock at seating position at middle of second row If the belt lock is equipped";
CM_ SG_ 112 BltLockStAtRowSecMidBltLockSt1 "State of belt lock at seating position at middle of second row Belt lock state,  locked/unlocked";
CM_ SG_ 112 BltLockStAtRowSecMidBltLockSts "State of belt lock at seating position at middle of second row Belt lock status, OK/NOK";
CM_ SG_ 112 BltLockStAtRowSecRiBltLockEquid "State of belt lock at seating position at right of second row If the belt lock is equipped";
CM_ SG_ 112 BltLockStAtRowSecRiBltLockSt1 "State of belt lock at seating position at right of second row Belt lock state,  locked/unlocked";
CM_ SG_ 112 BltLockStAtRowSecRiBltLockSts "State of belt lock at seating position at right of second row Belt lock status, OK/NOK";
CM_ SG_ 112 BltLockStAtRowThrdLeBltLockEquid "State of belt lock at seating position at left of third row If the belt lock is equipped";
CM_ SG_ 112 BltLockStAtRowThrdLeBltLockSt1 "State of belt lock at seating position at left of third row Belt lock state,  locked/unlocked";
CM_ SG_ 112 BltLockStAtRowThrdLeBltLockSts "State of belt lock at seating position at left of third row Belt lock status, OK/NOK";
CM_ SG_ 112 BltLockStAtRowThrdRiBltLockEquid "State of belt lock at seating position at right of third row If the belt lock is equipped";
CM_ SG_ 112 BltLockStAtRowThrdRiBltLockSt1 "State of belt lock at seating position at right of third row Belt lock state,  locked/unlocked";
CM_ SG_ 112 BltLockStAtRowThrdRiBltLockSts "State of belt lock at seating position at right of third row Belt lock status, OK/NOK";
CM_ SG_ 112 RecOfPostImpctBrkgSuspcChks "Signal checksum";
CM_ SG_ 112 RecOfPostImpctBrkgSuspcCntr "Signal counter";
CM_ SG_ 112 RecOfPostImpctBrkgSuspcSuspcPost "ASIL-B(D) signal to inform that a crash has occurred.";
CM_ SG_ 559 DstTrvldFromSftyBkp "Saved backupvalue";
CM_ SG_ 559 DstTrvldVldFromSftyBkp "Indication if the transmitted backupvalue is valid or not";
CM_ SG_ 559 NotifForEmgyCall "Information if there is a need for the vehicle to perform an emergency call.";
CM_ SG_ 559 PassMidSeatSts "Occupation status based on occupant detection sensor at front row middle seat. ";
CM_ SG_ 559 SRSIntVolt "SRS internal voltage";
CM_ SG_ 328 RecOfImpct2ImpctDvxSigned "Crash information , changed velocity in x direction , data with sign";
CM_ SG_ 328 RecOfImpct2ImpctDvySigned "Crash information , changed velocity in y direction, data with sign";
CM_ SG_ 328 RecOfPostImpctBrkgCfmdChks "E2E checksum";
CM_ SG_ 328 RecOfPostImpctBrkgCfmdCntr "E2E counter";
CM_ SG_ 328 RecOfPostImpctBrkgCfmdCrashFrnt "Crash type = front.";
CM_ SG_ 328 RecOfPostImpctBrkgCfmdCrashLarge "Large Animal";
CM_ SG_ 328 RecOfPostImpctBrkgCfmdCrashOffro "Airbourne";
CM_ SG_ 328 RecOfPostImpctBrkgCfmdCrash_0000 "Ditch";
CM_ SG_ 328 RecOfPostImpctBrkgCfmdCrash_0001 "Rough Terrain";
CM_ SG_ 328 RecOfPostImpctBrkgCfmdCrash_0002 "Rough Terrain, severe";
CM_ SG_ 328 RecOfPostImpctBrkgCfmdCrashOz "Crash type = side offzone (i.e. behind C-pillar or in front of A-pillar.) ";
CM_ SG_ 328 RecOfPostImpctBrkgCfmdCrashPed "Crash type = pedestrian impact";
CM_ SG_ 328 RecOfPostImpctBrkgCfmdCrashRe "Crash type = rear";
CM_ SG_ 328 RecOfPostImpctBrkgCfmdCrashRollo "Crash type = rollover";
CM_ SG_ 328 RecOfPostImpctBrkgCfmdCrashSideL "Crash type = left side.";
CM_ SG_ 328 RecOfPostImpctBrkgCfmdCrashSideR "Crash type = right side.";
CM_ SG_ 328 RecOfPostImpctBrkgCfmdPostImpctB "ASIL-B(D) signal to inform that a crash has occurred.";
CM_ SG_ 628 HVfault "0: No fault 
1: There is one fault qualified at least  ";
CM_ SG_ 628 SRSResdSig1ToZCUDMSafetyChks "SRSResdSig1ToZCUDMSafety";
CM_ SG_ 628 SRSResdSig1ToZCUDMSafetyCntr "SRSResdSig1ToZCUDMSafety";
CM_ SG_ 628 SRSResdSig1ToZCUDMSafetyUInt32 "SRSResdSig1ToZCUDMSafety";
CM_ SG_ 560 AgDataCmpQualityPitchRateCmpQual "Quality of offset compensation for pitchrate";
CM_ SG_ 560 AgDataCmpQualityRollRateCmpQuali "Quality of offset compensation for rollrate";
CM_ SG_ 560 AgDataCmpQualityYawRateCmpQualit "Quality of offset compensation for yawrate";
CM_ SG_ 1307 WakeUpReasonsforSRS "WakeUpReasons";
CM_ SG_ 1371 VFCVectorSRSBlockID "BlockID";
CM_ SG_ 1371 VFCVectorSRSVFCid0 "SettingsComfort";
CM_ SG_ 1371 VFCVectorSRSVFCid1 "ParkingDrivingClimatization";
CM_ SG_ 1371 VFCVectorSRSVFCid10 "ExteriorLighting";
CM_ SG_ 1371 VFCVectorSRSVFCid11 "VFC11";
CM_ SG_ 1371 VFCVectorSRSVFCid12 "Alarm";
CM_ SG_ 1371 VFCVectorSRSVFCid13 "VFC13";
CM_ SG_ 1371 VFCVectorSRSVFCid14 "InteriorLighting";
CM_ SG_ 1371 VFCVectorSRSVFCid15 "VFC15";
CM_ SG_ 1371 VFCVectorSRSVFCid16 "Locking";
CM_ SG_ 1371 VFCVectorSRSVFCid17 "RemoteKeyFunctionality";
CM_ SG_ 1371 VFCVectorSRSVFCid18 "PropulsionStart";
CM_ SG_ 1371 VFCVectorSRSVFCid19 "VFC19";
CM_ SG_ 1371 VFCVectorSRSVFCid2 "PostClimatisation";
CM_ SG_ 1371 VFCVectorSRSVFCid20 "VFC20";
CM_ SG_ 1371 VFCVectorSRSVFCid21 "PowerClosures";
CM_ SG_ 1371 VFCVectorSRSVFCid22 "VehicleDriving";
CM_ SG_ 1371 VFCVectorSRSVFCid23 "VFC23";
CM_ SG_ 1371 VFCVectorSRSVFCid24 "SettingsProfile";
CM_ SG_ 1371 VFCVectorSRSVFCid25 "SeatComfortFunctions";
CM_ SG_ 1371 VFCVectorSRSVFCid26 "Brake";
CM_ SG_ 1371 VFCVectorSRSVFCid27 "InfotainmentPoll";
CM_ SG_ 1371 VFCVectorSRSVFCid28 "HVEnergyStorage";
CM_ SG_ 1371 VFCVectorSRSVFCid29 "VFC29";
CM_ SG_ 1371 VFCVectorSRSVFCid3 "PowertrainParkingClimatization";
CM_ SG_ 1371 VFCVectorSRSVFCid30 "TelematicsConnectivity";
CM_ SG_ 1371 VFCVectorSRSVFCid31 "VFC31";
CM_ SG_ 1371 VFCVectorSRSVFCid32 "VFC32";
CM_ SG_ 1371 VFCVectorSRSVFCid33 "Diagnostics";
CM_ SG_ 1371 VFCVectorSRSVFCid34 "VehicleModeManagement";
CM_ SG_ 1371 VFCVectorSRSVFCid35 "TrailerCaravanFunctions";
CM_ SG_ 1371 VFCVectorSRSVFCid36 "Immobilizer";
CM_ SG_ 1371 VFCVectorSRSVFCid37 "Windows";
CM_ SG_ 1371 VFCVectorSRSVFCid38 "Visibility";
CM_ SG_ 1371 VFCVectorSRSVFCid39 "VFC39";
CM_ SG_ 1371 VFCVectorSRSVFCid4 "VFC4";
CM_ SG_ 1371 VFCVectorSRSVFCid40 "VFC40";
CM_ SG_ 1371 VFCVectorSRSVFCid41 "InfotainmentPush";
CM_ SG_ 1371 VFCVectorSRSVFCid42 "ChargingHV";
CM_ SG_ 1371 VFCVectorSRSVFCid43 "BodyPreClimatisation";
CM_ SG_ 1371 VFCVectorSRSVFCid44 "Crash";
CM_ SG_ 1371 VFCVectorSRSVFCid45 "GlobalShortDuration";
CM_ SG_ 1371 VFCVectorSRSVFCid46 "ExteriorLightsHazard";
CM_ SG_ 1371 VFCVectorSRSVFCid47 "VFC47";
CM_ SG_ 1371 VFCVectorSRSVFCid48 "DoorOpenWarning";
CM_ SG_ 1371 VFCVectorSRSVFCid49 "ChargingLVInit";
CM_ SG_ 1371 VFCVectorSRSVFCid5 "VFC5";
CM_ SG_ 1371 VFCVectorSRSVFCid50 "VFC50";
CM_ SG_ 1371 VFCVectorSRSVFCid51 "VFC51";
CM_ SG_ 1371 VFCVectorSRSVFCid52 "HVBatteryThermalEventWarning";
CM_ SG_ 1371 VFCVectorSRSVFCid53 "VisualAssist";
CM_ SG_ 1371 VFCVectorSRSVFCid54 "PassiveSafety";
CM_ SG_ 1371 VFCVectorSRSVFCid55 "LifeDetection";
CM_ SG_ 1371 VFCVectorSRSVFCid56 "BackboneFlexray";
CM_ SG_ 1371 VFCVectorSRSVFCid57 "Functionmarket";
CM_ SG_ 1371 VFCVectorSRSVFCid58 "VFC58";
CM_ SG_ 1371 VFCVectorSRSVFCid59 "VFC59";
CM_ SG_ 1371 VFCVectorSRSVFCid6 "SettingsVehicle";
CM_ SG_ 1371 VFCVectorSRSVFCid60 "VFC60";
CM_ SG_ 1371 VFCVectorSRSVFCid61 "VFC61";
CM_ SG_ 1371 VFCVectorSRSVFCid7 "VFC7";
CM_ SG_ 1371 VFCVectorSRSVFCid8 "VFC8";
CM_ SG_ 1371 VFCVectorSRSVFCid9 "IPWakeup";
CM_ SG_ 208 TrlrFogLiSts "Trailer fog lights on/off status.";
CM_ SG_ 208 TrlrLampActvtChk "TrlrLampActvtChkNotAvl - Disable trailer lamp check.
TrlrLampActvtChkAvl - Enable trailer lamp check.";
CM_ SG_ 208 TrlrLampChkSts "TrlrLampChkStrtd - Trailer lamp check started.
TrlrLampChkCmpl - Trailer lamp check Completed.
CnclOper - Cancelled operation by user.
TrlrLampEngOffReqd - Required user to turn off the engine.
Resd1/2/3 - Reserved1/2/3.";
CM_ SG_ 208 TrlrLeIndcrFltSts "No Flt - Left DI works well.
Flt - Left DI is in fault status.";
CM_ SG_ 208 TrlrLiFltSts "0 - Brake light and both DIs work well.
1 - Right DI is in failure status.
2 - Left DI is in failure status.
3 - Both DIs are in failure status.
4 - Brake light is in failure status.
5 - Brake light and right DI are in failure status.
6 - Brake light and left DI are in failure status.
7 - Brake light and both DIs are in failure status.";
CM_ SG_ 208 TrlrPrmntPwrActv "YES - Power supply with KL-30.
NO - Power off.";
CM_ SG_ 208 TrlrPrsnt "TrlrNotPrsnt - Trailer caravan is not connected to the vehicle.
TrlrPrsnt - Trailer caravan is connected to the vehicle.";
CM_ SG_ 208 TrlrRiIndcrFltSts "No Flt - Right DI works well.
Flt - Right DI is in fault status.";
CM_ SG_ 208 TrlrSrvReq "No Flt - Towbar release button works well.
Flt - Towba release button is stuck.";
CM_ SG_ 145 TrlrBrkLiSts "Trailer brake lights on/off status.";
CM_ SG_ 145 TrlrIndcrTurnSts "Trailer direction indicators on/off status.";
CM_ SG_ 145 TrlrPosnLiSts "Trailer position lights on/off status.";
CM_ SG_ 145 TrlrRvsgLiSts "Trailer reversing light on/off status.";
CM_ SG_ 145 TwbrLockdPosn "To indicate if the towbar is in locked position.";
CM_ SG_ 145 TwbrWarnStsChks "Checksum";
CM_ SG_ 145 TwbrWarnStsCntr "Counter";
CM_ SG_ 145 TwbrWarnStsYesNo "To inform the driver if electrical-towbar is released by accident during driving.";
CM_ SG_ 345 FullElecTwbrPosn "To indicate the towbar position";
CM_ SG_ 345 SemiElecTwbrPosn "SemiElecTwbrPosn";
CM_ SG_ 345 TwbrRelsBtn "To indicate if the towbar release button is pressed or not.";
BA_DEF_ BU_  "NodeLayerModules" STRING ;
BA_DEF_ BU_  "NmAsrNodeIdentifier" INT 0 255;
BA_DEF_ BU_  "NmAsrNode" ENUM  "No","Yes";
BA_DEF_ BU_  "ILused" ENUM  "No","Yes";
BA_DEF_  "ProtocolType" STRING ;
BA_DEF_  "NmAsrMessageCount" INT 0 255;
BA_DEF_  "NmAsrBaseAddress" HEX 0 536870911;
BA_DEF_  "BusType" STRING ;
BA_DEF_  "BaudRateCANFD" FLOAT 1000 10000000;
BA_DEF_  "Baudrate" INT 1000 1000000;
BA_DEF_  "DBName" STRING ;
BA_DEF_ BO_  "NmAsrMessage" ENUM  "No","Yes";
BA_DEF_ BO_  "GenMsgStartDelayTime" INT 0 65536;
BA_DEF_ BO_  "GenMsgSendType" ENUM  "cyclic","spontaneous","not-used","not-used","not-used","cyclicAndSpontaneous","not-used","cyclicIfActive","NoMsgSendType";
BA_DEF_ BO_  "GenMsgILSupport" ENUM  "No","Yes";
BA_DEF_ BO_  "GenMsgDelayTime" INT 0 65536;
BA_DEF_ BO_  "GenMsgCycleTime" INT 0 65536;
BA_DEF_ BO_  "CANFD_BRS" ENUM  "0","1";
BA_DEF_ BO_  "VFrameFormat" ENUM  "StandardCAN","ExtendedCAN","reserved","J1939PG","reserved","reserved","reserved","reserved","reserved","reserved","reserved","reserved","reserved","reserved","StandardCAN_FD","ExtendedCAN_FD";
BA_DEF_ SG_  "GenSigStartValue" HEX 0 80000000;
BA_DEF_ SG_  "GenSigSendType" ENUM  "Cyclic","OnWrite","OnWriteWithRepetition","OnChange","OnChangeWithRepetition","IfActive","IfActiveWithRepetition","NoSigSendType";
BA_DEF_ SG_  "GenSigFuncType" ENUM  "NoFunction","n/a","n/a","n/a","n/a","n/a","n/a","n/a","n/a","n/a","n/a","n/a","n/a","n/a","n/a","CHK","CNTR","n/a","n/a","n/a","CNTR_AR_01","CRC_AR_01_BOTH","CRC_AR_01_ALT","CRC_AR_01_LOW","CRC_AR_01_NIBBLE","CNTR_AR_04","CRC_AR_04A","CNTR_AR_05","CRC_AR_05";
BA_DEF_ SG_  "GenSigDataID" STRING ;
BA_DEF_ SG_  "SystemSignalLongSymbol" STRING ;
BA_DEF_ BO_  "SystemMessageLongSymbol" STRING ;
BA_DEF_DEF_  "NodeLayerModules" "CANoeILNLSPA.dll";
BA_DEF_DEF_  "NmAsrNodeIdentifier" 0;
BA_DEF_DEF_  "NmAsrNode" "No";
BA_DEF_DEF_  "ILused" "Yes";
BA_DEF_DEF_  "ProtocolType" "";
BA_DEF_DEF_  "NmAsrMessageCount" 64;
BA_DEF_DEF_  "NmAsrBaseAddress" 1280;
BA_DEF_DEF_  "BusType" "";
BA_DEF_DEF_  "BaudRateCANFD" 2000;
BA_DEF_DEF_  "Baudrate" 500;
BA_DEF_DEF_  "DBName" "";
BA_DEF_DEF_  "NmAsrMessage" "No";
BA_DEF_DEF_  "GenMsgStartDelayTime" 0;
BA_DEF_DEF_  "GenMsgSendType" "NoMsgSendType";
BA_DEF_DEF_  "GenMsgILSupport" "Yes";
BA_DEF_DEF_  "GenMsgDelayTime" 0;
BA_DEF_DEF_  "GenMsgCycleTime" 0;
BA_DEF_DEF_  "CANFD_BRS" "1";
BA_DEF_DEF_  "VFrameFormat" "J1939PG";
BA_DEF_DEF_  "GenSigStartValue" 0;
BA_DEF_DEF_  "GenSigSendType" "NoSigSendType";
BA_DEF_DEF_  "GenSigFuncType" "NoFunction";
BA_DEF_DEF_  "GenSigDataID" "";
BA_DEF_DEF_  "SystemSignalLongSymbol" "";
BA_DEF_DEF_  "SystemMessageLongSymbol" "";
BA_ "Baudrate" 500000;
BA_ "ProtocolType" "CAN";
BA_ "BusType" "CAN";
BA_ "DBName" "ZCUD_CAN1";
BA_ "ILused" BU_ ETC 0;
BA_ "NmAsrNodeIdentifier" BU_ OGM 49;
BA_ "NmAsrNode" BU_ OGM 1;
BA_ "NodeLayerModules" BU_ OGM "CANoeILNLSPA.dll,AsrNM33.dll";
BA_ "NmAsrNodeIdentifier" BU_ POT 7;
BA_ "NmAsrNode" BU_ POT 1;
BA_ "NodeLayerModules" BU_ POT "CANoeILNLSPA.dll,AsrNM33.dll";
BA_ "NmAsrNodeIdentifier" BU_ SRS3 27;
BA_ "NmAsrNode" BU_ SRS3 1;
BA_ "NodeLayerModules" BU_ SRS3 "CANoeILNLSPA.dll,AsrNM33.dll";
BA_ "NmAsrNodeIdentifier" BU_ TRM 10;
BA_ "NmAsrNode" BU_ TRM 1;
BA_ "NodeLayerModules" BU_ TRM "CANoeILNLSPA.dll,AsrNM33.dll";
BA_ "NmAsrNodeIdentifier" BU_ ZCUD 1;
BA_ "NmAsrNode" BU_ ZCUD 1;
BA_ "NodeLayerModules" BU_ ZCUD "CANoeILNLVector.dll";
BA_ "VFrameFormat" BO_ 406 0;
BA_ "GenMsgSendType" BO_ 406 0;
BA_ "GenMsgCycleTime" BO_ 406 55;
BA_ "VFrameFormat" BO_ 81 0;
BA_ "GenMsgSendType" BO_ 81 0;
BA_ "GenMsgCycleTime" BO_ 81 20;
BA_ "VFrameFormat" BO_ 1441 0;
BA_ "GenMsgSendType" BO_ 1441 1;
BA_ "GenMsgDelayTime" BO_ 1441 100;
BA_ "VFrameFormat" BO_ 1412 0;
BA_ "GenMsgSendType" BO_ 1412 1;
BA_ "GenMsgDelayTime" BO_ 1412 5;
BA_ "VFrameFormat" BO_ 1409 0;
BA_ "GenMsgSendType" BO_ 1409 1;
BA_ "GenMsgDelayTime" BO_ 1409 5;
BA_ "VFrameFormat" BO_ 1413 0;
BA_ "GenMsgSendType" BO_ 1413 1;
BA_ "GenMsgDelayTime" BO_ 1413 5;
BA_ "VFrameFormat" BO_ 1415 0;
BA_ "GenMsgSendType" BO_ 1415 1;
BA_ "GenMsgDelayTime" BO_ 1415 5;
BA_ "VFrameFormat" BO_ 1472 0;
BA_ "GenMsgSendType" BO_ 1472 1;
BA_ "GenMsgDelayTime" BO_ 1472 100;
BA_ "VFrameFormat" BO_ 1465 0;
BA_ "GenMsgSendType" BO_ 1465 1;
BA_ "GenMsgDelayTime" BO_ 1465 10;
BA_ "VFrameFormat" BO_ 962 0;
BA_ "GenMsgSendType" BO_ 962 1;
BA_ "GenMsgDelayTime" BO_ 962 95;
BA_ "VFrameFormat" BO_ 1596 0;
BA_ "GenMsgSendType" BO_ 1596 1;
BA_ "GenMsgDelayTime" BO_ 1596 5;
BA_ "VFrameFormat" BO_ 897 0;
BA_ "GenMsgSendType" BO_ 897 0;
BA_ "GenMsgCycleTime" BO_ 897 500;
BA_ "VFrameFormat" BO_ 769 0;
BA_ "GenMsgSendType" BO_ 769 0;
BA_ "GenMsgCycleTime" BO_ 769 160;
BA_ "VFrameFormat" BO_ 720 0;
BA_ "GenMsgSendType" BO_ 720 0;
BA_ "GenMsgCycleTime" BO_ 720 150;
BA_ "VFrameFormat" BO_ 724 0;
BA_ "GenMsgSendType" BO_ 724 0;
BA_ "GenMsgCycleTime" BO_ 724 150;
BA_ "VFrameFormat" BO_ 730 0;
BA_ "GenMsgSendType" BO_ 730 0;
BA_ "GenMsgCycleTime" BO_ 730 150;
BA_ "VFrameFormat" BO_ 741 0;
BA_ "GenMsgSendType" BO_ 741 0;
BA_ "GenMsgCycleTime" BO_ 741 150;
BA_ "VFrameFormat" BO_ 747 0;
BA_ "GenMsgSendType" BO_ 747 0;
BA_ "GenMsgCycleTime" BO_ 747 150;
BA_ "VFrameFormat" BO_ 704 0;
BA_ "GenMsgSendType" BO_ 704 0;
BA_ "GenMsgCycleTime" BO_ 704 100;
BA_ "VFrameFormat" BO_ 1329 0;
BA_ "GenMsgSendType" BO_ 1329 1;
BA_ "GenMsgILSupport" BO_ 1329 0;
BA_ "NmAsrMessage" BO_ 1329 1;
BA_ "GenMsgDelayTime" BO_ 1329 20;
BA_ "VFrameFormat" BO_ 1346 0;
BA_ "GenMsgSendType" BO_ 1346 0;
BA_ "GenMsgCycleTime" BO_ 1346 1000;
BA_ "VFrameFormat" BO_ 1557 0;
BA_ "GenMsgSendType" BO_ 1557 1;
BA_ "GenMsgDelayTime" BO_ 1557 5;
BA_ "VFrameFormat" BO_ 416 0;
BA_ "GenMsgSendType" BO_ 416 0;
BA_ "GenMsgCycleTime" BO_ 416 300;
BA_ "VFrameFormat" BO_ 149 0;
BA_ "GenMsgSendType" BO_ 149 0;
BA_ "GenMsgCycleTime" BO_ 149 45;
BA_ "VFrameFormat" BO_ 578 0;
BA_ "GenMsgSendType" BO_ 578 0;
BA_ "GenMsgCycleTime" BO_ 578 100;
BA_ "VFrameFormat" BO_ 1287 0;
BA_ "GenMsgSendType" BO_ 1287 1;
BA_ "GenMsgILSupport" BO_ 1287 0;
BA_ "NmAsrMessage" BO_ 1287 1;
BA_ "GenMsgDelayTime" BO_ 1287 20;
BA_ "VFrameFormat" BO_ 803 0;
BA_ "GenMsgSendType" BO_ 803 0;
BA_ "GenMsgCycleTime" BO_ 803 250;
BA_ "VFrameFormat" BO_ 262 0;
BA_ "GenMsgSendType" BO_ 262 0;
BA_ "GenMsgCycleTime" BO_ 262 20;
BA_ "VFrameFormat" BO_ 261 0;
BA_ "GenMsgSendType" BO_ 261 0;
BA_ "GenMsgCycleTime" BO_ 261 20;
BA_ "VFrameFormat" BO_ 2041 0;
BA_ "GenMsgSendType" BO_ 2041 1;
BA_ "GenMsgDelayTime" BO_ 2041 5;
BA_ "SystemMessageLongSymbol" BO_ 2041 "SrsToZcudISO26021ZCUCAN1DiagResFrame11";
BA_ "VFrameFormat" BO_ 1593 0;
BA_ "GenMsgSendType" BO_ 1593 1;
BA_ "GenMsgDelayTime" BO_ 1593 5;
BA_ "VFrameFormat" BO_ 961 0;
BA_ "GenMsgSendType" BO_ 961 1;
BA_ "GenMsgDelayTime" BO_ 961 95;
BA_ "VFrameFormat" BO_ 137 0;
BA_ "GenMsgSendType" BO_ 137 0;
BA_ "GenMsgCycleTime" BO_ 137 10;
BA_ "VFrameFormat" BO_ 16 0;
BA_ "GenMsgSendType" BO_ 16 5;
BA_ "GenMsgDelayTime" BO_ 16 10;
BA_ "GenMsgCycleTime" BO_ 16 200;
BA_ "VFrameFormat" BO_ 18 0;
BA_ "GenMsgSendType" BO_ 18 0;
BA_ "GenMsgCycleTime" BO_ 18 10;
BA_ "VFrameFormat" BO_ 19 0;
BA_ "GenMsgSendType" BO_ 19 0;
BA_ "GenMsgCycleTime" BO_ 19 10;
BA_ "VFrameFormat" BO_ 33 0;
BA_ "GenMsgSendType" BO_ 33 0;
BA_ "GenMsgCycleTime" BO_ 33 10;
BA_ "VFrameFormat" BO_ 549 0;
BA_ "GenMsgSendType" BO_ 549 0;
BA_ "GenMsgCycleTime" BO_ 549 250;
BA_ "VFrameFormat" BO_ 322 0;
BA_ "GenMsgSendType" BO_ 322 0;
BA_ "GenMsgCycleTime" BO_ 322 30;
BA_ "VFrameFormat" BO_ 554 0;
BA_ "GenMsgSendType" BO_ 554 0;
BA_ "GenMsgCycleTime" BO_ 554 100;
BA_ "VFrameFormat" BO_ 864 0;
BA_ "GenMsgSendType" BO_ 864 0;
BA_ "GenMsgCycleTime" BO_ 864 350;
BA_ "VFrameFormat" BO_ 112 0;
BA_ "GenMsgSendType" BO_ 112 0;
BA_ "GenMsgCycleTime" BO_ 112 20;
BA_ "VFrameFormat" BO_ 559 0;
BA_ "GenMsgSendType" BO_ 559 0;
BA_ "GenMsgCycleTime" BO_ 559 100;
BA_ "VFrameFormat" BO_ 328 0;
BA_ "GenMsgSendType" BO_ 328 0;
BA_ "GenMsgCycleTime" BO_ 328 30;
BA_ "VFrameFormat" BO_ 628 0;
BA_ "GenMsgSendType" BO_ 628 0;
BA_ "GenMsgCycleTime" BO_ 628 80;
BA_ "VFrameFormat" BO_ 560 0;
BA_ "GenMsgSendType" BO_ 560 0;
BA_ "GenMsgCycleTime" BO_ 560 70;
BA_ "VFrameFormat" BO_ 1307 0;
BA_ "GenMsgSendType" BO_ 1307 1;
BA_ "GenMsgILSupport" BO_ 1307 0;
BA_ "NmAsrMessage" BO_ 1307 1;
BA_ "GenMsgDelayTime" BO_ 1307 20;
BA_ "VFrameFormat" BO_ 1371 0;
BA_ "GenMsgSendType" BO_ 1371 0;
BA_ "GenMsgCycleTime" BO_ 1371 1000;
BA_ "VFrameFormat" BO_ 1464 0;
BA_ "GenMsgSendType" BO_ 1464 1;
BA_ "GenMsgDelayTime" BO_ 1464 10;
BA_ "VFrameFormat" BO_ 1559 0;
BA_ "GenMsgSendType" BO_ 1559 1;
BA_ "GenMsgDelayTime" BO_ 1559 5;
BA_ "VFrameFormat" BO_ 208 0;
BA_ "GenMsgSendType" BO_ 208 0;
BA_ "GenMsgCycleTime" BO_ 208 30;
BA_ "VFrameFormat" BO_ 145 0;
BA_ "GenMsgSendType" BO_ 145 0;
BA_ "GenMsgCycleTime" BO_ 145 40;
BA_ "VFrameFormat" BO_ 345 0;
BA_ "GenMsgSendType" BO_ 345 0;
BA_ "GenMsgCycleTime" BO_ 345 50;
BA_ "GenSigSendType" SG_ 406 DoorSldngLeReOpenEnaSts 0;
BA_ "GenSigSendType" SG_ 406 DoorSldngRiReOpenEnaSts 0;
BA_ "GenSigSendType" SG_ 406 SecRowLeSeatMotPosnCalReq 0;
BA_ "GenSigSendType" SG_ 406 SecRowRiSeatMotPosnCalReq 0;
BA_ "GenSigSendType" SG_ 81 PwrSldgDoorLePosnReqFromHmi 0;
BA_ "GenSigStartValue" SG_ 81 PwrSldgDoorLePosnReqFromHmi 101;
BA_ "GenSigSendType" SG_ 81 PwrSldgDoorRiPosnReqFromHmi 0;
BA_ "GenSigStartValue" SG_ 81 PwrSldgDoorRiPosnReqFromHmi 101;
BA_ "GenSigSendType" SG_ 962 SRSdevelpsignalgroupRXFunctionde 1;
BA_ "SystemSignalLongSymbol" SG_ 962 SRSdevelpsignalgroupRXFunctionde "SRSdevelpsignalgroupRXFunctiondevpsignalgroup1";
BA_ "GenSigSendType" SG_ 962 SRSdevelpsignalgroupRXFunct_0000 1;
BA_ "SystemSignalLongSymbol" SG_ 962 SRSdevelpsignalgroupRXFunct_0000 "SRSdevelpsignalgroupRXFunctiondevpsignalgroup2";
BA_ "GenSigSendType" SG_ 962 SRSdevelpsignalgroupRXFunct_0001 1;
BA_ "SystemSignalLongSymbol" SG_ 962 SRSdevelpsignalgroupRXFunct_0001 "SRSdevelpsignalgroupRXFunctiondevpsignalgroup3";
BA_ "GenSigSendType" SG_ 962 SRSdevelpsignalgroupRXFunct_0002 1;
BA_ "SystemSignalLongSymbol" SG_ 962 SRSdevelpsignalgroupRXFunct_0002 "SRSdevelpsignalgroupRXFunctiondevpsignalgroup4";
BA_ "GenSigSendType" SG_ 962 SRSdevelpsignalgroupRXFunct_0003 1;
BA_ "SystemSignalLongSymbol" SG_ 962 SRSdevelpsignalgroupRXFunct_0003 "SRSdevelpsignalgroupRXFunctiondevpsignalgroup5";
BA_ "GenSigSendType" SG_ 962 SRSdevelpsignalgroupRXFunct_0004 1;
BA_ "SystemSignalLongSymbol" SG_ 962 SRSdevelpsignalgroupRXFunct_0004 "SRSdevelpsignalgroupRXFunctiondevpsignalgroup6";
BA_ "GenSigSendType" SG_ 962 SRSdevelpsignalgroupRXFunct_0005 1;
BA_ "SystemSignalLongSymbol" SG_ 962 SRSdevelpsignalgroupRXFunct_0005 "SRSdevelpsignalgroupRXFunctiondevpsignalgroup7";
BA_ "GenSigSendType" SG_ 962 SRSdevelpsignalgroupRXFunct_0006 1;
BA_ "SystemSignalLongSymbol" SG_ 962 SRSdevelpsignalgroupRXFunct_0006 "SRSdevelpsignalgroupRXFunctiondevpsignalgroup8";
BA_ "GenSigSendType" SG_ 897 AltitudeInfrom 0;
BA_ "GenSigSendType" SG_ 897 OGMIntErr 0;
BA_ "GenSigSendType" SG_ 897 OGMOvrVoltRangErr 0;
BA_ "GenSigSendType" SG_ 897 OGMTempErr 0;
BA_ "GenSigSendType" SG_ 897 OGMUndVoltRangErr 0;
BA_ "GenSigSendType" SG_ 897 OxygenGenrErrInfo 0;
BA_ "GenSigSendType" SG_ 897 OxygenSplyAvlSts 0;
BA_ "GenSigSendType" SG_ 897 OxygenSplyErr 0;
BA_ "GenSigSendType" SG_ 769 OGMMissingSlaveSignal 0;
BA_ "GenSigSendType" SG_ 720 BusCurrentFb 0;
BA_ "GenSigSendType" SG_ 720 InpVoltFb 0;
BA_ "GenSigSendType" SG_ 720 McuTempFb 0;
BA_ "GenSigSendType" SG_ 720 MotTempFb 0;
BA_ "GenSigSendType" SG_ 724 MosTempFb 0;
BA_ "GenSigSendType" SG_ 724 OGMCmprSpdFb 0;
BA_ "GenSigSendType" SG_ 724 PhaseCurrentFb 0;
BA_ "GenSigSendType" SG_ 724 PressureFb 0;
BA_ "GenSigSendType" SG_ 730 BackflushVlvErr 0;
BA_ "GenSigSendType" SG_ 730 ChgFilElmWarn 0;
BA_ "GenSigSendType" SG_ 730 CoolgFanErr 0;
BA_ "GenSigSendType" SG_ 730 McuOvrTempErr 0;
BA_ "GenSigSendType" SG_ 730 McuTempSnsrErr 0;
BA_ "GenSigSendType" SG_ 730 MosOvrTempErr 0;
BA_ "GenSigSendType" SG_ 730 MosTempSnsrErr 0;
BA_ "GenSigSendType" SG_ 730 MotTempSnsrErr 0;
BA_ "GenSigSendType" SG_ 730 OxygenConcFlt 0;
BA_ "GenSigSendType" SG_ 730 OxygenTubeBlk 0;
BA_ "GenSigSendType" SG_ 730 PressureFlt 0;
BA_ "GenSigSendType" SG_ 730 PressureSnsrErr 0;
BA_ "GenSigSendType" SG_ 730 VlvVoltFlt 0;
BA_ "GenSigSendType" SG_ 741 MotStsFrmOGM 0;
BA_ "GenSigSendType" SG_ 741 OGMRunTi 0;
BA_ "GenSigSendType" SG_ 741 OxygenConcFbFrmOGM 0;
BA_ "GenSigSendType" SG_ 741 OxygenConcSnsrStsFrmOGM 0;
BA_ "GenSigSendType" SG_ 747 MoleculeVlv1 0;
BA_ "GenSigSendType" SG_ 747 MoleculeVlv2 0;
BA_ "GenSigSendType" SG_ 747 OGMFlowFb 0;
BA_ "GenSigSendType" SG_ 747 OGMHwVers 0;
BA_ "GenSigSendType" SG_ 747 OGMSwVers 0;
BA_ "GenSigSendType" SG_ 704 OxygenSplyDesPwrCns 0;
BA_ "GenSigSendType" SG_ 1329 WakeUpReasonsforOGM 0;
BA_ "GenSigSendType" SG_ 1346 VFCVectorOGMBlockID 0;
BA_ "GenSigSendType" SG_ 1346 VFCVectorOGMVFCid0 0;
BA_ "GenSigSendType" SG_ 1346 VFCVectorOGMVFCid1 0;
BA_ "GenSigSendType" SG_ 1346 VFCVectorOGMVFCid10 0;
BA_ "GenSigSendType" SG_ 1346 VFCVectorOGMVFCid11 0;
BA_ "GenSigSendType" SG_ 1346 VFCVectorOGMVFCid12 0;
BA_ "GenSigSendType" SG_ 1346 VFCVectorOGMVFCid13 0;
BA_ "GenSigSendType" SG_ 1346 VFCVectorOGMVFCid14 0;
BA_ "GenSigSendType" SG_ 1346 VFCVectorOGMVFCid15 0;
BA_ "GenSigSendType" SG_ 1346 VFCVectorOGMVFCid16 0;
BA_ "GenSigSendType" SG_ 1346 VFCVectorOGMVFCid17 0;
BA_ "GenSigSendType" SG_ 1346 VFCVectorOGMVFCid18 0;
BA_ "GenSigSendType" SG_ 1346 VFCVectorOGMVFCid19 0;
BA_ "GenSigSendType" SG_ 1346 VFCVectorOGMVFCid2 0;
BA_ "GenSigSendType" SG_ 1346 VFCVectorOGMVFCid20 0;
BA_ "GenSigSendType" SG_ 1346 VFCVectorOGMVFCid21 0;
BA_ "GenSigSendType" SG_ 1346 VFCVectorOGMVFCid22 0;
BA_ "GenSigSendType" SG_ 1346 VFCVectorOGMVFCid23 0;
BA_ "GenSigSendType" SG_ 1346 VFCVectorOGMVFCid24 0;
BA_ "GenSigSendType" SG_ 1346 VFCVectorOGMVFCid25 0;
BA_ "GenSigSendType" SG_ 1346 VFCVectorOGMVFCid26 0;
BA_ "GenSigSendType" SG_ 1346 VFCVectorOGMVFCid27 0;
BA_ "GenSigSendType" SG_ 1346 VFCVectorOGMVFCid28 0;
BA_ "GenSigSendType" SG_ 1346 VFCVectorOGMVFCid29 0;
BA_ "GenSigSendType" SG_ 1346 VFCVectorOGMVFCid3 0;
BA_ "GenSigSendType" SG_ 1346 VFCVectorOGMVFCid30 0;
BA_ "GenSigSendType" SG_ 1346 VFCVectorOGMVFCid31 0;
BA_ "GenSigSendType" SG_ 1346 VFCVectorOGMVFCid32 0;
BA_ "GenSigSendType" SG_ 1346 VFCVectorOGMVFCid33 0;
BA_ "GenSigSendType" SG_ 1346 VFCVectorOGMVFCid34 0;
BA_ "GenSigSendType" SG_ 1346 VFCVectorOGMVFCid35 0;
BA_ "GenSigSendType" SG_ 1346 VFCVectorOGMVFCid36 0;
BA_ "GenSigSendType" SG_ 1346 VFCVectorOGMVFCid37 0;
BA_ "GenSigSendType" SG_ 1346 VFCVectorOGMVFCid38 0;
BA_ "GenSigSendType" SG_ 1346 VFCVectorOGMVFCid39 0;
BA_ "GenSigSendType" SG_ 1346 VFCVectorOGMVFCid4 0;
BA_ "GenSigSendType" SG_ 1346 VFCVectorOGMVFCid40 0;
BA_ "GenSigSendType" SG_ 1346 VFCVectorOGMVFCid41 0;
BA_ "GenSigSendType" SG_ 1346 VFCVectorOGMVFCid42 0;
BA_ "GenSigSendType" SG_ 1346 VFCVectorOGMVFCid43 0;
BA_ "GenSigSendType" SG_ 1346 VFCVectorOGMVFCid44 0;
BA_ "GenSigSendType" SG_ 1346 VFCVectorOGMVFCid45 0;
BA_ "GenSigSendType" SG_ 1346 VFCVectorOGMVFCid46 0;
BA_ "GenSigSendType" SG_ 1346 VFCVectorOGMVFCid47 0;
BA_ "GenSigSendType" SG_ 1346 VFCVectorOGMVFCid48 0;
BA_ "GenSigSendType" SG_ 1346 VFCVectorOGMVFCid49 0;
BA_ "GenSigSendType" SG_ 1346 VFCVectorOGMVFCid5 0;
BA_ "GenSigSendType" SG_ 1346 VFCVectorOGMVFCid50 0;
BA_ "GenSigSendType" SG_ 1346 VFCVectorOGMVFCid51 0;
BA_ "GenSigSendType" SG_ 1346 VFCVectorOGMVFCid52 0;
BA_ "GenSigSendType" SG_ 1346 VFCVectorOGMVFCid53 0;
BA_ "GenSigSendType" SG_ 1346 VFCVectorOGMVFCid54 0;
BA_ "GenSigSendType" SG_ 1346 VFCVectorOGMVFCid55 0;
BA_ "GenSigSendType" SG_ 1346 VFCVectorOGMVFCid56 0;
BA_ "GenSigSendType" SG_ 1346 VFCVectorOGMVFCid57 0;
BA_ "GenSigSendType" SG_ 1346 VFCVectorOGMVFCid58 0;
BA_ "GenSigSendType" SG_ 1346 VFCVectorOGMVFCid59 0;
BA_ "GenSigSendType" SG_ 1346 VFCVectorOGMVFCid6 0;
BA_ "GenSigSendType" SG_ 1346 VFCVectorOGMVFCid60 0;
BA_ "GenSigSendType" SG_ 1346 VFCVectorOGMVFCid61 0;
BA_ "GenSigSendType" SG_ 1346 VFCVectorOGMVFCid7 0;
BA_ "GenSigSendType" SG_ 1346 VFCVectorOGMVFCid8 0;
BA_ "GenSigSendType" SG_ 1346 VFCVectorOGMVFCid9 0;
BA_ "GenSigSendType" SG_ 416 TrCrashUnlckSts 0;
BA_ "GenSigSendType" SG_ 149 TrInsdOpenSwtSts 0;
BA_ "GenSigSendType" SG_ 578 TrCinhSwt 0;
BA_ "GenSigSendType" SG_ 578 TrLatPosn 0;
BA_ "GenSigSendType" SG_ 803 SecRowLeHeatgLvl 0;
BA_ "GenSigSendType" SG_ 803 SecRowLeVentnLvl 0;
BA_ "GenSigSendType" SG_ 262 RowReLeModSwtSts 0;
BA_ "GenSigSendType" SG_ 261 RowReRiModSwtSts 0;
BA_ "SystemSignalLongSymbol" SG_ 2041 SrsToZcudISO26021ZCUDCan1ResNpdu "SrsToZcudISO26021ZCUDCan1ResNpdu11";
BA_ "GenSigSendType" SG_ 961 SRSdevelpsignalgroupTXFunctionde 1;
BA_ "SystemSignalLongSymbol" SG_ 961 SRSdevelpsignalgroupTXFunctionde "SRSdevelpsignalgroupTXFunctiondevpsignalgroup1";
BA_ "GenSigSendType" SG_ 961 SRSdevelpsignalgroupTXFunct_0000 1;
BA_ "SystemSignalLongSymbol" SG_ 961 SRSdevelpsignalgroupTXFunct_0000 "SRSdevelpsignalgroupTXFunctiondevpsignalgroup2";
BA_ "GenSigSendType" SG_ 961 SRSdevelpsignalgroupTXFunct_0001 1;
BA_ "SystemSignalLongSymbol" SG_ 961 SRSdevelpsignalgroupTXFunct_0001 "SRSdevelpsignalgroupTXFunctiondevpsignalgroup3";
BA_ "GenSigSendType" SG_ 961 SRSdevelpsignalgroupTXFunct_0002 1;
BA_ "SystemSignalLongSymbol" SG_ 961 SRSdevelpsignalgroupTXFunct_0002 "SRSdevelpsignalgroupTXFunctiondevpsignalgroup4";
BA_ "GenSigSendType" SG_ 961 SRSdevelpsignalgroupTXFunct_0003 1;
BA_ "SystemSignalLongSymbol" SG_ 961 SRSdevelpsignalgroupTXFunct_0003 "SRSdevelpsignalgroupTXFunctiondevpsignalgroup5";
BA_ "GenSigSendType" SG_ 961 SRSdevelpsignalgroupTXFunct_0004 1;
BA_ "SystemSignalLongSymbol" SG_ 961 SRSdevelpsignalgroupTXFunct_0004 "SRSdevelpsignalgroupTXFunctiondevpsignalgroup6";
BA_ "GenSigSendType" SG_ 961 SRSdevelpsignalgroupTXFunct_0005 1;
BA_ "SystemSignalLongSymbol" SG_ 961 SRSdevelpsignalgroupTXFunct_0005 "SRSdevelpsignalgroupTXFunctiondevpsignalgroup7";
BA_ "GenSigSendType" SG_ 961 SRSdevelpsignalgroupTXFunct_0006 1;
BA_ "SystemSignalLongSymbol" SG_ 961 SRSdevelpsignalgroupTXFunct_0006 "SRSdevelpsignalgroupTXFunctiondevpsignalgroup8";
BA_ "GenSigSendType" SG_ 137 AgDataRawSafeChks 0;
BA_ "GenSigFuncType" SG_ 137 AgDataRawSafeChks 15;
BA_ "GenSigDataID" SG_ 137 AgDataRawSafeChks "0x23";
BA_ "GenSigStartValue" SG_ 137 AgDataRawSafeChks 255;
BA_ "GenSigSendType" SG_ 137 AgDataRawSafeCntr 0;
BA_ "GenSigFuncType" SG_ 137 AgDataRawSafeCntr 16;
BA_ "GenSigSendType" SG_ 137 AgDataRawSafeRollRate 0;
BA_ "GenSigSendType" SG_ 137 AgDataRawSafeRollRateQf 0;
BA_ "GenSigStartValue" SG_ 137 AgDataRawSafeRollRateQf 1;
BA_ "GenSigSendType" SG_ 137 AgDataRawSafeYawRate 0;
BA_ "GenSigSendType" SG_ 137 AgDataRawSafeYawRateQf 0;
BA_ "GenSigStartValue" SG_ 137 AgDataRawSafeYawRateQf 1;
BA_ "GenSigSendType" SG_ 137 BltLockStAtDrvrBltLockSt1 0;
BA_ "GenSigStartValue" SG_ 137 BltLockStAtDrvrBltLockSt1 1;
BA_ "GenSigSendType" SG_ 137 BltLockStAtDrvrBltLockSts 0;
BA_ "GenSigSendType" SG_ 137 BltLockStAtPassBltLockSt1 0;
BA_ "GenSigStartValue" SG_ 137 BltLockStAtPassBltLockSt1 1;
BA_ "GenSigSendType" SG_ 137 BltLockStAtPassBltLockSts 0;
BA_ "GenSigSendType" SG_ 16 CrashStsSafeChks 1;
BA_ "GenSigFuncType" SG_ 16 CrashStsSafeChks 15;
BA_ "GenSigDataID" SG_ 16 CrashStsSafeChks "0x40B";
BA_ "GenSigStartValue" SG_ 16 CrashStsSafeChks 255;
BA_ "GenSigSendType" SG_ 16 CrashStsSafeCntr 1;
BA_ "GenSigFuncType" SG_ 16 CrashStsSafeCntr 16;
BA_ "GenSigSendType" SG_ 16 CrashStsSafeSts 1;
BA_ "GenSigSendType" SG_ 16 PassAirbStsChgNotifReq 0;
BA_ "GenSigSendType" SG_ 18 ADataRawSafeALat 0;
BA_ "GenSigSendType" SG_ 18 ADataRawSafeALat1Qf 0;
BA_ "GenSigStartValue" SG_ 18 ADataRawSafeALat1Qf 1;
BA_ "GenSigSendType" SG_ 18 ADataRawSafeALgt 0;
BA_ "GenSigSendType" SG_ 18 ADataRawSafeALgt1Qf 0;
BA_ "GenSigStartValue" SG_ 18 ADataRawSafeALgt1Qf 1;
BA_ "GenSigSendType" SG_ 18 ADataRawSafeAVert 0;
BA_ "GenSigStartValue" SG_ 18 ADataRawSafeAVert 1155;
BA_ "GenSigSendType" SG_ 18 ADataRawSafeAVertQf 0;
BA_ "GenSigStartValue" SG_ 18 ADataRawSafeAVertQf 1;
BA_ "GenSigSendType" SG_ 18 ADataRawSafeChks 0;
BA_ "GenSigFuncType" SG_ 18 ADataRawSafeChks 15;
BA_ "GenSigDataID" SG_ 18 ADataRawSafeChks "0x22";
BA_ "GenSigStartValue" SG_ 18 ADataRawSafeChks 255;
BA_ "GenSigSendType" SG_ 18 ADataRawSafeCntr 0;
BA_ "GenSigFuncType" SG_ 18 ADataRawSafeCntr 16;
BA_ "GenSigSendType" SG_ 19 AsyDataWithCmpSafeALat1Qf 0;
BA_ "GenSigStartValue" SG_ 19 AsyDataWithCmpSafeALat1Qf 1;
BA_ "GenSigSendType" SG_ 19 AsyDataWithCmpSafeALatWithCmp 0;
BA_ "GenSigSendType" SG_ 19 AsyDataWithCmpSafeALgt1Qf 0;
BA_ "GenSigStartValue" SG_ 19 AsyDataWithCmpSafeALgt1Qf 1;
BA_ "GenSigSendType" SG_ 19 AsyDataWithCmpSafeChks 0;
BA_ "GenSigFuncType" SG_ 19 AsyDataWithCmpSafeChks 15;
BA_ "GenSigDataID" SG_ 19 AsyDataWithCmpSafeChks "0x24";
BA_ "GenSigStartValue" SG_ 19 AsyDataWithCmpSafeChks 255;
BA_ "GenSigSendType" SG_ 19 AsyDataWithCmpSafeCntr 0;
BA_ "GenSigFuncType" SG_ 19 AsyDataWithCmpSafeCntr 16;
BA_ "GenSigSendType" SG_ 19 AsyDataWithCmpSafeGrdtOfALgt 0;
BA_ "GenSigSendType" SG_ 19 AsyDataWithCmpSafeYawRateQf 0;
BA_ "GenSigStartValue" SG_ 19 AsyDataWithCmpSafeYawRateQf 1;
BA_ "GenSigSendType" SG_ 19 AsyDataWithCmpSafeYawRateWithCmp 0;
BA_ "GenSigSendType" SG_ 33 ActvnReqOfRtrctrRvsbLe 0;
BA_ "GenSigSendType" SG_ 33 ActvnReqOfRtrctrRvsbRi 0;
BA_ "GenSigSendType" SG_ 33 BltLockStSafeAtDrvrBltLockSt1 0;
BA_ "GenSigStartValue" SG_ 33 BltLockStSafeAtDrvrBltLockSt1 1;
BA_ "GenSigSendType" SG_ 33 BltLockStSafeAtDrvrBltLockStErrS 0;
BA_ "SystemSignalLongSymbol" SG_ 33 BltLockStSafeAtDrvrBltLockStErrS "BltLockStSafeAtDrvrBltLockStErrSts";
BA_ "GenSigSendType" SG_ 33 BltLockStSafeAtDrvrChks 0;
BA_ "GenSigFuncType" SG_ 33 BltLockStSafeAtDrvrChks 15;
BA_ "GenSigDataID" SG_ 33 BltLockStSafeAtDrvrChks "0x40C";
BA_ "GenSigStartValue" SG_ 33 BltLockStSafeAtDrvrChks 255;
BA_ "GenSigSendType" SG_ 33 BltLockStSafeAtDrvrCntr 0;
BA_ "GenSigFuncType" SG_ 33 BltLockStSafeAtDrvrCntr 16;
BA_ "GenSigSendType" SG_ 33 BrkPedlSts 0;
BA_ "GenSigSendType" SG_ 33 CrashSts2 1;
BA_ "GenSigSendType" SG_ 549 BltLockStAtPassMidBltLockEquid 0;
BA_ "GenSigStartValue" SG_ 549 BltLockStAtPassMidBltLockEquid 1;
BA_ "GenSigSendType" SG_ 549 BltLockStAtPassMidBltLockSt1 0;
BA_ "GenSigSendType" SG_ 549 BltLockStAtPassMidBltLockSts 0;
BA_ "GenSigStartValue" SG_ 549 BltLockStAtPassMidBltLockSts 1;
BA_ "GenSigSendType" SG_ 549 BltLockStAtRowFrthLeBltLockEquid 0;
BA_ "GenSigStartValue" SG_ 549 BltLockStAtRowFrthLeBltLockEquid 1;
BA_ "GenSigSendType" SG_ 549 BltLockStAtRowFrthLeBltLockSt1 0;
BA_ "GenSigSendType" SG_ 549 BltLockStAtRowFrthLeBltLockSts 0;
BA_ "GenSigStartValue" SG_ 549 BltLockStAtRowFrthLeBltLockSts 1;
BA_ "GenSigSendType" SG_ 549 BltLockStAtRowFrthMidBltLockEqui 0;
BA_ "GenSigStartValue" SG_ 549 BltLockStAtRowFrthMidBltLockEqui 1;
BA_ "SystemSignalLongSymbol" SG_ 549 BltLockStAtRowFrthMidBltLockEqui "BltLockStAtRowFrthMidBltLockEquid";
BA_ "GenSigSendType" SG_ 549 BltLockStAtRowFrthMidBltLockSt1 0;
BA_ "GenSigSendType" SG_ 549 BltLockStAtRowFrthMidBltLockSts 0;
BA_ "GenSigStartValue" SG_ 549 BltLockStAtRowFrthMidBltLockSts 1;
BA_ "GenSigSendType" SG_ 549 BltLockStAtRowFrthRiBltLockEquid 0;
BA_ "GenSigStartValue" SG_ 549 BltLockStAtRowFrthRiBltLockEquid 1;
BA_ "GenSigSendType" SG_ 549 BltLockStAtRowFrthRiBltLockSt1 0;
BA_ "GenSigSendType" SG_ 549 BltLockStAtRowFrthRiBltLockSts 0;
BA_ "GenSigStartValue" SG_ 549 BltLockStAtRowFrthRiBltLockSts 1;
BA_ "GenSigSendType" SG_ 549 BltLockStAtRowThrdMidBltLockEqui 0;
BA_ "GenSigStartValue" SG_ 549 BltLockStAtRowThrdMidBltLockEqui 1;
BA_ "SystemSignalLongSymbol" SG_ 549 BltLockStAtRowThrdMidBltLockEqui "BltLockStAtRowThrdMidBltLockEquid";
BA_ "GenSigSendType" SG_ 549 BltLockStAtRowThrdMidBltLockSt1 0;
BA_ "GenSigSendType" SG_ 549 BltLockStAtRowThrdMidBltLockSts 0;
BA_ "GenSigStartValue" SG_ 549 BltLockStAtRowThrdMidBltLockSts 1;
BA_ "GenSigSendType" SG_ 549 SeatOccptAtRowFrthLe 0;
BA_ "GenSigSendType" SG_ 549 SeatOccptAtRowFrthMid 0;
BA_ "GenSigSendType" SG_ 549 SeatOccptAtRowFrthRi 0;
BA_ "GenSigSendType" SG_ 549 SeatOccptAtRowThrdMid 0;
BA_ "GenSigSendType" SG_ 322 AgDataRaw2SafeChks 0;
BA_ "GenSigFuncType" SG_ 322 AgDataRaw2SafeChks 15;
BA_ "GenSigDataID" SG_ 322 AgDataRaw2SafeChks "0x404";
BA_ "GenSigStartValue" SG_ 322 AgDataRaw2SafeChks 255;
BA_ "GenSigSendType" SG_ 322 AgDataRaw2SafeCntr 0;
BA_ "GenSigFuncType" SG_ 322 AgDataRaw2SafeCntr 16;
BA_ "GenSigSendType" SG_ 322 AgDataRaw2SafePitchRate 0;
BA_ "GenSigSendType" SG_ 322 AgDataRaw2SafePitchRateQf 0;
BA_ "GenSigStartValue" SG_ 322 AgDataRaw2SafePitchRateQf 1;
BA_ "GenSigSendType" SG_ 322 PassAirbLampReqChgOfPassAirbSts 0;
BA_ "GenSigSendType" SG_ 322 PassAirbLampReqChks 0;
BA_ "GenSigFuncType" SG_ 322 PassAirbLampReqChks 15;
BA_ "GenSigDataID" SG_ 322 PassAirbLampReqChks "0x475";
BA_ "GenSigStartValue" SG_ 322 PassAirbLampReqChks 255;
BA_ "GenSigSendType" SG_ 322 PassAirbLampReqCntr 0;
BA_ "GenSigFuncType" SG_ 322 PassAirbLampReqCntr 16;
BA_ "GenSigSendType" SG_ 322 PassAirbLampReqPassAirbLampDiReq 0;
BA_ "GenSigStartValue" SG_ 322 PassAirbLampReqPassAirbLampDiReq 2;
BA_ "GenSigSendType" SG_ 322 PassAirbLampReqPassAirbLampEnaRe 0;
BA_ "GenSigStartValue" SG_ 322 PassAirbLampReqPassAirbLampEnaRe 2;
BA_ "SystemSignalLongSymbol" SG_ 322 PassAirbLampReqPassAirbLampEnaRe "PassAirbLampReqPassAirbLampEnaReq";
BA_ "GenSigSendType" SG_ 322 ReqForAsyDataStorgFromRestrntSys 0;
BA_ "SystemSignalLongSymbol" SG_ 322 ReqForAsyDataStorgFromRestr_0000 "ReqForAsyDataStorgFromRestrntSys_UB";
BA_ "GenSigSendType" SG_ 322 ReqForHzrdInt 0;
BA_ "GenSigSendType" SG_ 322 SftyAirbRollovrSuppSts 0;
BA_ "GenSigSendType" SG_ 554 JIDByte0 0;
BA_ "GenSigStartValue" SG_ 554 JIDByte0 255;
BA_ "GenSigSendType" SG_ 554 JIDByte1 0;
BA_ "GenSigStartValue" SG_ 554 JIDByte1 255;
BA_ "GenSigSendType" SG_ 554 JIDByte2 0;
BA_ "GenSigStartValue" SG_ 554 JIDByte2 255;
BA_ "GenSigSendType" SG_ 554 JIDByte3 0;
BA_ "GenSigStartValue" SG_ 554 JIDByte3 255;
BA_ "GenSigSendType" SG_ 554 JIDByte4 0;
BA_ "GenSigStartValue" SG_ 554 JIDByte4 255;
BA_ "GenSigSendType" SG_ 554 JIDByte5 0;
BA_ "GenSigStartValue" SG_ 554 JIDByte5 255;
BA_ "GenSigSendType" SG_ 554 JIDByte6 0;
BA_ "GenSigStartValue" SG_ 554 JIDByte6 255;
BA_ "GenSigSendType" SG_ 554 JIDByte7 0;
BA_ "GenSigStartValue" SG_ 554 JIDByte7 255;
BA_ "GenSigSendType" SG_ 864 BltCrashNotifDrvr 0;
BA_ "GenSigSendType" SG_ 864 BltCrashNotifPass 0;
BA_ "GenSigSendType" SG_ 864 PassAirbSts 0;
BA_ "GenSigStartValue" SG_ 864 PassAirbSts 1;
BA_ "GenSigSendType" SG_ 864 PedProtnMsgReqForFlt 0;
BA_ "GenSigSendType" SG_ 864 PedProtnMsgReqForImpct 0;
BA_ "GenSigSendType" SG_ 864 RecOfImpctCrashFrnt 0;
BA_ "GenSigSendType" SG_ 864 RecOfImpctCrashOffroadA 0;
BA_ "GenSigSendType" SG_ 864 RecOfImpctCrashOffroadD 0;
BA_ "GenSigSendType" SG_ 864 RecOfImpctCrashOffroadRT 0;
BA_ "GenSigSendType" SG_ 864 RecOfImpctCrashOffroadRTsevere 0;
BA_ "GenSigSendType" SG_ 864 RecOfImpctCrashPed 0;
BA_ "GenSigSendType" SG_ 864 RecOfImpctCrashRe 0;
BA_ "GenSigSendType" SG_ 864 RecOfImpctCrashRollovr 0;
BA_ "GenSigSendType" SG_ 864 RecOfImpctCrashSideLe 0;
BA_ "GenSigSendType" SG_ 864 RecOfImpctCrashSideRi 0;
BA_ "GenSigSendType" SG_ 864 RecOfImpctCrashState 0;
BA_ "GenSigSendType" SG_ 864 RecOfImpctImpctDvx 0;
BA_ "GenSigSendType" SG_ 864 RecOfImpctImpctDvy 0;
BA_ "GenSigSendType" SG_ 864 RecOfImpctImpctRollAg 0;
BA_ "GenSigSendType" SG_ 864 RecOfImpctVehOri 0;
BA_ "GenSigStartValue" SG_ 864 RecOfImpctVehOri 4;
BA_ "GenSigSendType" SG_ 864 RestrntSysLampReq 0;
BA_ "GenSigSendType" SG_ 864 RestrntSysMsgReq 0;
BA_ "GenSigStartValue" SG_ 864 RestrntSysMsgReq 1;
BA_ "GenSigSendType" SG_ 864 SafetyCrashFb 0;
BA_ "GenSigSendType" SG_ 112 BltLockStAtRowSecLeBltLockEquid 0;
BA_ "GenSigStartValue" SG_ 112 BltLockStAtRowSecLeBltLockEquid 1;
BA_ "GenSigSendType" SG_ 112 BltLockStAtRowSecLeBltLockSt1 0;
BA_ "GenSigSendType" SG_ 112 BltLockStAtRowSecLeBltLockSts 0;
BA_ "GenSigStartValue" SG_ 112 BltLockStAtRowSecLeBltLockSts 1;
BA_ "GenSigSendType" SG_ 112 BltLockStAtRowSecMidBltLockEquid 0;
BA_ "GenSigStartValue" SG_ 112 BltLockStAtRowSecMidBltLockEquid 1;
BA_ "GenSigSendType" SG_ 112 BltLockStAtRowSecMidBltLockSt1 0;
BA_ "GenSigSendType" SG_ 112 BltLockStAtRowSecMidBltLockSts 0;
BA_ "GenSigStartValue" SG_ 112 BltLockStAtRowSecMidBltLockSts 1;
BA_ "GenSigSendType" SG_ 112 BltLockStAtRowSecRiBltLockEquid 0;
BA_ "GenSigStartValue" SG_ 112 BltLockStAtRowSecRiBltLockEquid 1;
BA_ "GenSigSendType" SG_ 112 BltLockStAtRowSecRiBltLockSt1 0;
BA_ "GenSigSendType" SG_ 112 BltLockStAtRowSecRiBltLockSts 0;
BA_ "GenSigStartValue" SG_ 112 BltLockStAtRowSecRiBltLockSts 1;
BA_ "GenSigSendType" SG_ 112 BltLockStAtRowThrdLeBltLockEquid 0;
BA_ "GenSigStartValue" SG_ 112 BltLockStAtRowThrdLeBltLockEquid 1;
BA_ "GenSigSendType" SG_ 112 BltLockStAtRowThrdLeBltLockSt1 0;
BA_ "GenSigSendType" SG_ 112 BltLockStAtRowThrdLeBltLockSts 0;
BA_ "GenSigStartValue" SG_ 112 BltLockStAtRowThrdLeBltLockSts 1;
BA_ "GenSigSendType" SG_ 112 BltLockStAtRowThrdRiBltLockEquid 0;
BA_ "GenSigStartValue" SG_ 112 BltLockStAtRowThrdRiBltLockEquid 1;
BA_ "GenSigSendType" SG_ 112 BltLockStAtRowThrdRiBltLockSt1 0;
BA_ "GenSigSendType" SG_ 112 BltLockStAtRowThrdRiBltLockSts 0;
BA_ "GenSigStartValue" SG_ 112 BltLockStAtRowThrdRiBltLockSts 1;
BA_ "GenSigSendType" SG_ 112 RecOfPostImpctBrkgSuspcChks 0;
BA_ "GenSigFuncType" SG_ 112 RecOfPostImpctBrkgSuspcChks 15;
BA_ "GenSigDataID" SG_ 112 RecOfPostImpctBrkgSuspcChks "0x19";
BA_ "GenSigStartValue" SG_ 112 RecOfPostImpctBrkgSuspcChks 255;
BA_ "GenSigSendType" SG_ 112 RecOfPostImpctBrkgSuspcCntr 0;
BA_ "GenSigFuncType" SG_ 112 RecOfPostImpctBrkgSuspcCntr 16;
BA_ "GenSigSendType" SG_ 112 RecOfPostImpctBrkgSuspcSuspcPost 0;
BA_ "GenSigStartValue" SG_ 112 RecOfPostImpctBrkgSuspcSuspcPost 1;
BA_ "SystemSignalLongSymbol" SG_ 112 RecOfPostImpctBrkgSuspcSuspcPost "RecOfPostImpctBrkgSuspcSuspcPostImpctBrkg";
BA_ "GenSigSendType" SG_ 559 DstTrvldFromSftyBkp 0;
BA_ "GenSigSendType" SG_ 559 DstTrvldVldFromSftyBkp 0;
BA_ "GenSigSendType" SG_ 559 NotifForEmgyCall 0;
BA_ "GenSigSendType" SG_ 559 PassMidSeatSts 0;
BA_ "GenSigSendType" SG_ 559 SRSIntVolt 0;
BA_ "GenSigSendType" SG_ 328 RecOfImpct2ImpctDvxSigned 0;
BA_ "GenSigStartValue" SG_ 328 RecOfImpct2ImpctDvxSigned 255;
BA_ "GenSigSendType" SG_ 328 RecOfImpct2ImpctDvySigned 0;
BA_ "GenSigStartValue" SG_ 328 RecOfImpct2ImpctDvySigned 255;
BA_ "GenSigSendType" SG_ 328 RecOfPostImpctBrkgCfmdChks 0;
BA_ "GenSigFuncType" SG_ 328 RecOfPostImpctBrkgCfmdChks 15;
BA_ "GenSigDataID" SG_ 328 RecOfPostImpctBrkgCfmdChks "0x4A";
BA_ "GenSigStartValue" SG_ 328 RecOfPostImpctBrkgCfmdChks 255;
BA_ "GenSigSendType" SG_ 328 RecOfPostImpctBrkgCfmdCntr 0;
BA_ "GenSigFuncType" SG_ 328 RecOfPostImpctBrkgCfmdCntr 16;
BA_ "GenSigSendType" SG_ 328 RecOfPostImpctBrkgCfmdCrashFrnt 0;
BA_ "GenSigStartValue" SG_ 328 RecOfPostImpctBrkgCfmdCrashFrnt 1;
BA_ "GenSigSendType" SG_ 328 RecOfPostImpctBrkgCfmdCrashLarge 0;
BA_ "GenSigStartValue" SG_ 328 RecOfPostImpctBrkgCfmdCrashLarge 1;
BA_ "SystemSignalLongSymbol" SG_ 328 RecOfPostImpctBrkgCfmdCrashLarge "RecOfPostImpctBrkgCfmdCrashLargeAnimal";
BA_ "GenSigSendType" SG_ 328 RecOfPostImpctBrkgCfmdCrashOffro 0;
BA_ "GenSigStartValue" SG_ 328 RecOfPostImpctBrkgCfmdCrashOffro 1;
BA_ "SystemSignalLongSymbol" SG_ 328 RecOfPostImpctBrkgCfmdCrashOffro "RecOfPostImpctBrkgCfmdCrashOffroadA";
BA_ "GenSigSendType" SG_ 328 RecOfPostImpctBrkgCfmdCrash_0000 0;
BA_ "GenSigStartValue" SG_ 328 RecOfPostImpctBrkgCfmdCrash_0000 1;
BA_ "SystemSignalLongSymbol" SG_ 328 RecOfPostImpctBrkgCfmdCrash_0000 "RecOfPostImpctBrkgCfmdCrashOffroadD";
BA_ "GenSigSendType" SG_ 328 RecOfPostImpctBrkgCfmdCrash_0001 0;
BA_ "GenSigStartValue" SG_ 328 RecOfPostImpctBrkgCfmdCrash_0001 1;
BA_ "SystemSignalLongSymbol" SG_ 328 RecOfPostImpctBrkgCfmdCrash_0001 "RecOfPostImpctBrkgCfmdCrashOffroadRT";
BA_ "GenSigSendType" SG_ 328 RecOfPostImpctBrkgCfmdCrash_0002 0;
BA_ "GenSigStartValue" SG_ 328 RecOfPostImpctBrkgCfmdCrash_0002 1;
BA_ "SystemSignalLongSymbol" SG_ 328 RecOfPostImpctBrkgCfmdCrash_0002 "RecOfPostImpctBrkgCfmdCrashOffroadRTsevere";
BA_ "GenSigSendType" SG_ 328 RecOfPostImpctBrkgCfmdCrashOz 0;
BA_ "GenSigStartValue" SG_ 328 RecOfPostImpctBrkgCfmdCrashOz 1;
BA_ "GenSigSendType" SG_ 328 RecOfPostImpctBrkgCfmdCrashPed 0;
BA_ "GenSigStartValue" SG_ 328 RecOfPostImpctBrkgCfmdCrashPed 1;
BA_ "GenSigSendType" SG_ 328 RecOfPostImpctBrkgCfmdCrashRe 0;
BA_ "GenSigStartValue" SG_ 328 RecOfPostImpctBrkgCfmdCrashRe 1;
BA_ "GenSigSendType" SG_ 328 RecOfPostImpctBrkgCfmdCrashRollo 0;
BA_ "GenSigStartValue" SG_ 328 RecOfPostImpctBrkgCfmdCrashRollo 1;
BA_ "SystemSignalLongSymbol" SG_ 328 RecOfPostImpctBrkgCfmdCrashRollo "RecOfPostImpctBrkgCfmdCrashRollovr";
BA_ "GenSigSendType" SG_ 328 RecOfPostImpctBrkgCfmdCrashSideL 0;
BA_ "GenSigStartValue" SG_ 328 RecOfPostImpctBrkgCfmdCrashSideL 1;
BA_ "SystemSignalLongSymbol" SG_ 328 RecOfPostImpctBrkgCfmdCrashSideL "RecOfPostImpctBrkgCfmdCrashSideLe";
BA_ "GenSigSendType" SG_ 328 RecOfPostImpctBrkgCfmdCrashSideR 0;
BA_ "GenSigStartValue" SG_ 328 RecOfPostImpctBrkgCfmdCrashSideR 1;
BA_ "SystemSignalLongSymbol" SG_ 328 RecOfPostImpctBrkgCfmdCrashSideR "RecOfPostImpctBrkgCfmdCrashSideRi";
BA_ "GenSigSendType" SG_ 328 RecOfPostImpctBrkgCfmdPostImpctB 0;
BA_ "GenSigStartValue" SG_ 328 RecOfPostImpctBrkgCfmdPostImpctB 1;
BA_ "SystemSignalLongSymbol" SG_ 328 RecOfPostImpctBrkgCfmdPostImpctB "RecOfPostImpctBrkgCfmdPostImpctBrkgCfmd";
BA_ "GenSigSendType" SG_ 628 HVfault 0;
BA_ "GenSigSendType" SG_ 628 SRSResdSig1ToZCUDMSafetyChks 0;
BA_ "GenSigFuncType" SG_ 628 SRSResdSig1ToZCUDMSafetyChks 15;
BA_ "GenSigDataID" SG_ 628 SRSResdSig1ToZCUDMSafetyChks "0xEDE";
BA_ "GenSigSendType" SG_ 628 SRSResdSig1ToZCUDMSafetyCntr 0;
BA_ "GenSigFuncType" SG_ 628 SRSResdSig1ToZCUDMSafetyCntr 16;
BA_ "GenSigSendType" SG_ 628 SRSResdSig1ToZCUDMSafetyUInt32 0;
BA_ "GenSigSendType" SG_ 560 AgDataCmpQualityPitchRateCmpQual 0;
BA_ "SystemSignalLongSymbol" SG_ 560 AgDataCmpQualityPitchRateCmpQual "AgDataCmpQualityPitchRateCmpQuality";
BA_ "GenSigSendType" SG_ 560 AgDataCmpQualityRollRateCmpQuali 0;
BA_ "SystemSignalLongSymbol" SG_ 560 AgDataCmpQualityRollRateCmpQuali "AgDataCmpQualityRollRateCmpQuality";
BA_ "GenSigSendType" SG_ 560 AgDataCmpQualityYawRateCmpQualit 0;
BA_ "SystemSignalLongSymbol" SG_ 560 AgDataCmpQualityYawRateCmpQualit "AgDataCmpQualityYawRateCmpQuality";
BA_ "GenSigSendType" SG_ 1307 WakeUpReasonsforSRS 0;
BA_ "GenSigSendType" SG_ 1371 VFCVectorSRSBlockID 0;
BA_ "GenSigSendType" SG_ 1371 VFCVectorSRSVFCid0 0;
BA_ "GenSigSendType" SG_ 1371 VFCVectorSRSVFCid1 0;
BA_ "GenSigSendType" SG_ 1371 VFCVectorSRSVFCid10 0;
BA_ "GenSigSendType" SG_ 1371 VFCVectorSRSVFCid11 0;
BA_ "GenSigSendType" SG_ 1371 VFCVectorSRSVFCid12 0;
BA_ "GenSigSendType" SG_ 1371 VFCVectorSRSVFCid13 0;
BA_ "GenSigSendType" SG_ 1371 VFCVectorSRSVFCid14 0;
BA_ "GenSigSendType" SG_ 1371 VFCVectorSRSVFCid15 0;
BA_ "GenSigSendType" SG_ 1371 VFCVectorSRSVFCid16 0;
BA_ "GenSigSendType" SG_ 1371 VFCVectorSRSVFCid17 0;
BA_ "GenSigSendType" SG_ 1371 VFCVectorSRSVFCid18 0;
BA_ "GenSigSendType" SG_ 1371 VFCVectorSRSVFCid19 0;
BA_ "GenSigSendType" SG_ 1371 VFCVectorSRSVFCid2 0;
BA_ "GenSigSendType" SG_ 1371 VFCVectorSRSVFCid20 0;
BA_ "GenSigSendType" SG_ 1371 VFCVectorSRSVFCid21 0;
BA_ "GenSigSendType" SG_ 1371 VFCVectorSRSVFCid22 0;
BA_ "GenSigSendType" SG_ 1371 VFCVectorSRSVFCid23 0;
BA_ "GenSigSendType" SG_ 1371 VFCVectorSRSVFCid24 0;
BA_ "GenSigSendType" SG_ 1371 VFCVectorSRSVFCid25 0;
BA_ "GenSigSendType" SG_ 1371 VFCVectorSRSVFCid26 0;
BA_ "GenSigSendType" SG_ 1371 VFCVectorSRSVFCid27 0;
BA_ "GenSigSendType" SG_ 1371 VFCVectorSRSVFCid28 0;
BA_ "GenSigSendType" SG_ 1371 VFCVectorSRSVFCid29 0;
BA_ "GenSigSendType" SG_ 1371 VFCVectorSRSVFCid3 0;
BA_ "GenSigSendType" SG_ 1371 VFCVectorSRSVFCid30 0;
BA_ "GenSigSendType" SG_ 1371 VFCVectorSRSVFCid31 0;
BA_ "GenSigSendType" SG_ 1371 VFCVectorSRSVFCid32 0;
BA_ "GenSigSendType" SG_ 1371 VFCVectorSRSVFCid33 0;
BA_ "GenSigSendType" SG_ 1371 VFCVectorSRSVFCid34 0;
BA_ "GenSigSendType" SG_ 1371 VFCVectorSRSVFCid35 0;
BA_ "GenSigSendType" SG_ 1371 VFCVectorSRSVFCid36 0;
BA_ "GenSigSendType" SG_ 1371 VFCVectorSRSVFCid37 0;
BA_ "GenSigSendType" SG_ 1371 VFCVectorSRSVFCid38 0;
BA_ "GenSigSendType" SG_ 1371 VFCVectorSRSVFCid39 0;
BA_ "GenSigSendType" SG_ 1371 VFCVectorSRSVFCid4 0;
BA_ "GenSigSendType" SG_ 1371 VFCVectorSRSVFCid40 0;
BA_ "GenSigSendType" SG_ 1371 VFCVectorSRSVFCid41 0;
BA_ "GenSigSendType" SG_ 1371 VFCVectorSRSVFCid42 0;
BA_ "GenSigSendType" SG_ 1371 VFCVectorSRSVFCid43 0;
BA_ "GenSigSendType" SG_ 1371 VFCVectorSRSVFCid44 0;
BA_ "GenSigSendType" SG_ 1371 VFCVectorSRSVFCid45 0;
BA_ "GenSigSendType" SG_ 1371 VFCVectorSRSVFCid46 0;
BA_ "GenSigSendType" SG_ 1371 VFCVectorSRSVFCid47 0;
BA_ "GenSigSendType" SG_ 1371 VFCVectorSRSVFCid48 0;
BA_ "GenSigSendType" SG_ 1371 VFCVectorSRSVFCid49 0;
BA_ "GenSigSendType" SG_ 1371 VFCVectorSRSVFCid5 0;
BA_ "GenSigSendType" SG_ 1371 VFCVectorSRSVFCid50 0;
BA_ "GenSigSendType" SG_ 1371 VFCVectorSRSVFCid51 0;
BA_ "GenSigSendType" SG_ 1371 VFCVectorSRSVFCid52 0;
BA_ "GenSigSendType" SG_ 1371 VFCVectorSRSVFCid53 0;
BA_ "GenSigSendType" SG_ 1371 VFCVectorSRSVFCid54 0;
BA_ "GenSigSendType" SG_ 1371 VFCVectorSRSVFCid55 0;
BA_ "GenSigSendType" SG_ 1371 VFCVectorSRSVFCid56 0;
BA_ "GenSigSendType" SG_ 1371 VFCVectorSRSVFCid57 0;
BA_ "GenSigSendType" SG_ 1371 VFCVectorSRSVFCid58 0;
BA_ "GenSigSendType" SG_ 1371 VFCVectorSRSVFCid59 0;
BA_ "GenSigSendType" SG_ 1371 VFCVectorSRSVFCid6 0;
BA_ "GenSigSendType" SG_ 1371 VFCVectorSRSVFCid60 0;
BA_ "GenSigSendType" SG_ 1371 VFCVectorSRSVFCid61 0;
BA_ "GenSigSendType" SG_ 1371 VFCVectorSRSVFCid7 0;
BA_ "GenSigSendType" SG_ 1371 VFCVectorSRSVFCid8 0;
BA_ "GenSigSendType" SG_ 1371 VFCVectorSRSVFCid9 0;
BA_ "GenSigSendType" SG_ 208 TrlrFogLiSts 0;
BA_ "GenSigSendType" SG_ 208 TrlrLampActvtChk 0;
BA_ "GenSigSendType" SG_ 208 TrlrLampChkSts 0;
BA_ "GenSigSendType" SG_ 208 TrlrLeIndcrFltSts 0;
BA_ "GenSigSendType" SG_ 208 TrlrLiFltSts 0;
BA_ "GenSigSendType" SG_ 208 TrlrPrmntPwrActv 0;
BA_ "GenSigStartValue" SG_ 208 TrlrPrmntPwrActv 1;
BA_ "GenSigSendType" SG_ 208 TrlrPrsnt 0;
BA_ "GenSigSendType" SG_ 208 TrlrRiIndcrFltSts 0;
BA_ "GenSigSendType" SG_ 208 TrlrSrvReq 0;
BA_ "GenSigSendType" SG_ 145 TrlrBrkLiSts 0;
BA_ "GenSigSendType" SG_ 145 TrlrIndcrTurnSts 0;
BA_ "GenSigSendType" SG_ 145 TrlrPosnLiSts 0;
BA_ "GenSigSendType" SG_ 145 TrlrRvsgLiSts 0;
BA_ "GenSigSendType" SG_ 145 TwbrLockdPosn 0;
BA_ "GenSigSendType" SG_ 145 TwbrWarnStsChks 0;
BA_ "GenSigFuncType" SG_ 145 TwbrWarnStsChks 15;
BA_ "GenSigDataID" SG_ 145 TwbrWarnStsChks "0x1F43";
BA_ "GenSigSendType" SG_ 145 TwbrWarnStsCntr 0;
BA_ "GenSigFuncType" SG_ 145 TwbrWarnStsCntr 16;
BA_ "GenSigSendType" SG_ 145 TwbrWarnStsYesNo 0;
BA_ "GenSigStartValue" SG_ 145 TwbrWarnStsYesNo 2;
BA_ "GenSigSendType" SG_ 345 FullElecTwbrPosn 0;
BA_ "GenSigSendType" SG_ 345 SemiElecTwbrPosn 0;
BA_ "GenSigSendType" SG_ 345 TwbrRelsBtn 0;
VAL_ 406 DoorSldngLeReOpenEnaSts 1 "EnableDisableCoding_Enabled" 0 "EnableDisableCoding_Disabled" ;
VAL_ 406 DoorSldngRiReOpenEnaSts 1 "EnableDisableCoding_Enabled" 0 "EnableDisableCoding_Disabled" ;
VAL_ 406 SecRowLeSeatMotPosnCalReq 1 "Boolean_TRUE" 0 "Boolean_FALSE" ;
VAL_ 406 SecRowRiSeatMotPosnCalReq 1 "Boolean_TRUE" 0 "Boolean_FALSE" ;
VAL_ 897 OGMIntErr 1 "Err1_Err" 0 "Err1_NoErr" ;
VAL_ 897 OGMOvrVoltRangErr 1 "Err1_Err" 0 "Err1_NoErr" ;
VAL_ 897 OGMTempErr 3 "TempErr_Invalid" 2 "TempErr_UnderTemp" 1 "TempErr_OverTemp" 0 "TempErr_Normal" ;
VAL_ 897 OGMUndVoltRangErr 1 "Err1_Err" 0 "Err1_NoErr" ;
VAL_ 897 OxygenGenrErrInfo 7 "OxygengenrErrInfo_Rsvd" 6 "OxygengenrErrInfo_AirCmprErr" 5 "OxygengenrErrInfo_RadrErr" 4 "OxygengenrErrInfo_FilErr" 3 "OxygengenrErrInfo_DryerErr" 2 "OxygengenrErrInfo_SolnVlvErr" 1 "OxygengenrErrInfo_HumidifierErr" 0 "OxygengenrErrInfo_Normal" ;
VAL_ 897 OxygenSplyAvlSts 7 "OxygenSplyAvlSts_TmrOvr" 6 "OxygenSplyAvlSts_BattleLo" 5 "OxygenSplyAvlSts_PwrLo" 4 "OxygenSplyAvlSts_None" 3 "OxygenSplyAvlSts_Error" 2 "OxygenSplyAvlSts_NasalCannula" 1 "OxygenSplyAvlSts_Diffuse" 0 "OxygenSplyAvlSts_Off" ;
VAL_ 897 OxygenSplyErr 1 "Err1_Err" 0 "Err1_NoErr" ;
VAL_ 769 OGMMissingSlaveSignal 1 "Boolean_TRUE" 0 "Boolean_FALSE" ;
VAL_ 1329 WakeUpReasonsforOGM 741 "WakeupReasons_871868" 740 "WakeupReasons_871957" 739 "WakeupReasons_871729" 738 "WakeupReasons_700779" 737 "WakeupReasons_839414" 736 "WakeupReasons_675025" 735 "WakeupReasons_671146" 734 "WakeupReasons_1031929" 733 "WakeupReasons_1033548" 732 "WakeupReasons_1033537" 731 "WakeupReasons_1033479" 730 "WakeupReasons_1030765" 729 "WakeupReasons_1028674" 728 "WakeupReasons_1033567" 727 "WakeupReasons_1033543" 726 "WakeupReasons_1033549" 725 "WakeupReasons_1033554" 724 "WakeupReasons_1033563" 723 "WakeupReasons_1033558" 722 "WakeupReasons_1029384" 721 "WakeupReasons_1029383" 720 "WakeupReasons_1029382" 719 "WakeupReasons_1032619" 718 "WakeupReasons_1024928" 717 "WakeupReasons_1033547" 716 "WakeupReasons_1033541" 715 "WakeupReasons_1033562" 714 "WakeupReasons_1033564" 713 "WakeupReasons_986765" 712 "WakeupReasons_1026103" 711 "WakeupReasons_1030764" 710 "WakeupReasons_1030941" 709 "WakeupReasons_1033556" 708 "WakeupReasons_1033539" 707 "WakeupReasons_1033534" 706 "WakeupReasons_1032477" 705 "WakeupReasons_1031280" 704 "WakeupReasons_1033542" 703 "WakeupReasons_1033632" 702 "WakeupReasons_1033533" 701 "WakeupReasons_1029166" 700 "WakeupReasons_1033538" 699 "WakeupReasons_1031789" 698 "WakeupReasons_1033552" 697 "WakeupReasons_1033553" 696 "WakeupReasons_1033559" 695 "WakeupReasons_1033544" 694 "WakeupReasons_1033561" 693 "WakeupReasons_1031029" 692 "WakeupReasons_1030360" 691 "WakeupReasons_1030761" 690 "WakeupReasons_1033550" 689 "WakeupReasons_1032579" 688 "WakeupReasons_1033557" 687 "WakeupReasons_1031936" 686 "WakeupReasons_1033566" 685 "WakeupReasons_1033551" 684 "WakeupReasons_1033540" 683 "WakeupReasons_1030760" 682 "WakeupReasons_1029735" 681 "WakeupReasons_1033565" 680 "WakeupReasons_852370" 679 "WakeupReasons_1033555" 678 "WakeupReasons_1033546" 677 "WakeupReasons_1032743" 676 "WakeupReasons_1032791" 675 "WakeupReasons_1033569" 674 "WakeupReasons_1031030" 673 "WakeupReasons_1028778" 672 "WakeupReasons_1030759" 671 "WakeupReasons_1031907" 670 "WakeupReasons_1033560" 669 "WakeupReasons_1031288" 668 "WakeupReasons_1030302" 667 "WakeupReasons_1031765" 666 "WakeupReasons_1031990" 665 "WakeupReasons_1028729" 664 "WakeupReasons_1030362" 663 "WakeupReasons_1030361" 662 "WakeupReasons_1030297" 661 "WakeupReasons_1030293" 660 "WakeupReasons_527345" 659 "WakeupReasons_988154" 658 "WakeupReasons_533580" 657 "WakeupReasons_533581" 656 "WakeupReasons_533576" 655 "WakeupReasons_1030255" 654 "WakeupReasons_527348" 653 "WakeupReasons_533578" 652 "WakeupReasons_527347" 651 "WakeupReasons_527346" 650 "WakeupReasons_ADCUReserve" 649 "WakeupReasons_885767" 648 "WakeupReasons_909025" 647 "WakeupReasons_909026" 646 "WakeupReasons_858177" 645 "WakeupReasons_858169" 644 "WakeupReasons_858152" 643 "WakeupReasons_973575" 642 "WakeupReason_973574" 641 "WakeupReason_987405" 640 "WakeupReason_858187" 639 "WakeupReason_988826" 638 "WakeupReason_988821" 637 "WakeupReason_987485" 636 "WakeupReason_908128" 635 "WakeupReason_908115" 634 "WakeupReason_856234" 633 "WakeupReason_856224" 632 "WakeupReason_858189" 631 "WakeupReason_858188" 630 "WakeupReason_872056" 629 "WakeupReason_870276" 628 "WakeupReason_858191" 627 "WakeupReason_847054" 626 "WakeupReason_856465" 625 "WakeupReason_872253" 624 "WakeupReason_855003" 623 "WakeupReason_855002" 622 "WakeupReason_854947" 621 "WakeupReason_855134" 620 "WakeupReason_854839" 619 "WakeupReason_854999" 618 "WakeupReason_855029" 617 "WakeupReason_714340" 616 "WakeupReason_852947" 615 "WakeupReason_852944" 614 "WakeupReason_852646" 613 "WakeupReason_852537" 612 "WakeupReason_852388" 611 "WakeupReason_852385" 610 "WakeupReason_852298" 609 "WakeupReason_852273" 608 "WakeupReason_852248" 607 "WakeupReason_852219" 606 "WakeupReason_852218" 605 "WakeupReason_852215" 604 "WakeupReason_852200" 603 "WakeupReason_852195" 602 "WakeupReason_852194" 601 "WakeupReason_852184" 600 "WakeupReason_852180" 599 "WakeupReason_852050" 598 "WakeupReason_852010" 597 "WakeupReason_851743" 596 "WakeupReason_851482" 595 "WakeupReason_702420" 594 "WakeupReason_667533" 593 "WakeupReason_645735" 592 "WakeupReason_362462" 591 "WakeupReason_361474" 590 "WakeupReason_361441" 589 "WakeupReason_846002" 588 "WakeupReason_845930" 587 "WakeupReason_842273" 586 "WakeupReason_846372" 585 "WakeupReason_675489" 584 "WakeupReason_675452" 583 "WakeupReason_298032" 582 "WakeupReason_322113" 581 "WakeupReason_320145" 580 "WakeupReason_841275" 579 "WakeupReason_839787" 578 "WakeupReason_839181" 577 "WakeupReason_714677" 576 "WakeupReason_840035" 566 "WakeupReason_839458" 565 "WakeupReason_837760" 564 "WakeupReason_702903" 563 "WakeupReason_837962" 562 "WakeupReason_703140" 561 "WakeupReason_837833" 560 "WakeupReason_839705" 559 "WakeupReason_839473" 558 "WakeupReason_838116" 557 "WakeupReason_717832" 556 "WakeupReason_714697" 555 "WakeupReason_714799" 554 "WakeupReason_714806" 553 "WakeupReason_709196" 552 "WakeupReason_710893" 551 "WakeupReason_708964" 550 "WakeupReason_715529" 549 "WakeupReason_714265" 548 "WakeupReason_714172" 547 "WakeupReason_713799" 546 "WakeupReason_706194" 545 "WakeupReason_713568" 544 "WakeupReason_710807" 543 "WakeupReason_714679" 542 "WakeupReason_714678" 541 "WakeupReason_715842" 540 "WakeupReason_714030" 539 "WakeupReason_710922" 538 "WakeupReason_716243" 537 "WakeupReason_713786" 536 "WakeupReason_714675" 535 "WakeupReason_702478" 534 "WakeupReason_713752" 533 "WakeupReasons_700530" 532 "WakeupReasons_698631" 531 "WakeupReasons_702452" 530 "WakeupReasons_700565" 529 "WakeupReasons_702402" 528 "WakeupReasons_702439" 527 "WakeupReasons_702448" 526 "WakeupReasons_701872" 525 "WakeupReasons_699114" 524 "WakeupReasons_702240" 523 "WakeupReasons_701270" 522 "WakeupReasons_533751" 521 "WakeupReasons_698581" 520 "WakeupReasons_698130" 519 "WakeupReasons_700130" 518 "WakeupReasons_699921" 517 "WakeupReasons_699919" 516 "WakeupReasons_700486" 515 "WakeupReasons_700782" 514 "WakeupReasons_696971" 513 "WakeupReasons_700692" 512 "WakeupReasons_698385" 511 "WakeupReasons_699922" 510 "WakeupReasons_697967" 509 "WakeupReasons_700684" 508 "WakeupReasons_644379" 507 "WakeupReasons_336435" 506 "WakeupReasons_683263" 505 "WakeupReasons_700554" 504 "WakeupReasons_691992" 503 "WakeupReasons_698129" 502 "WakeupReasons_696850" 501 "WakeupReasons_702088" 500 "WakeupReasons_696612" 499 "WakeupReasons_691994" 498 "WakeupReasons_700483" 497 "WakeupReasons_702204" 496 "WakeupReasons_700603" 495 "WakeupReasons_700215" 494 "WakeupReasons_701509" 493 "WakeupReasons_701508" 492 "WakeupReasons_700484" 491 "WakeupReasons_217907" 490 "WakeupReasons_194966" 489 "WakeupReasons_702174" 488 "WakeupReasons_697145" 487 "WakeupReasons_296931" 486 "WakeupReasons_700687" 485 "WakeupReasons_700686" 484 "WakeupReasons_698409" 483 "WakeupReasons_533750" 482 "WakeupReasons_700467" 481 "WakeupReasons_687404" 480 "WakeupReasons_681813" 479 "WakeupReasons_698288" 478 "WakeupReasons_698660" 477 "WakeupReasons_691993" 476 "WakeupReasons_700485" 475 "WakeupReasons_700425" 474 "WakeupReasons_702197" 473 "WakeupReasons_637992" 472 "WakeupReasons_698488" 471 "WakeupReasons_691991" 470 "WakeupReasons_692547" 469 "WakeupReasons_693914" 468 "WakeupReasons_693024" 467 "WakeupReasons_693005" 466 "WakeupReasons_667949" 465 "WakeupReasons_686281" 464 "WakeupReasons_680764" 463 "WakeupReasons_512384" 462 "WakeupReasons_692019" 461 "WakeupReasons_533850" 460 "WakeupReasons_533849" 459 "WakeupReasons_667188" 458 "WakeupReasons_514652" 457 "WakeupReasons_514651" 456 "WakeupReasons_112024" 455 "WakeupReasons_300690" 454 "WakeupReasons_299532" 453 "WakeupReasons_299531" 452 "WakeupReasons_299120" 451 "WakeupReasons_273516" 450 "WakeupReasons_265694" 449 "WakeupReasons_692439" 448 "WakeupReasons_354831" 447 "WakeupReasons_680765" 446 "WakeupReasons_45895" 445 "WakeupReasons_644275" 444 "WakeupReasons_351189" 443 "WakeupReasons_226570" 442 "WakeupReasons_654489" 441 "WakeupReasons_110181" 440 "WakeupReasons_226569" 439 "WakeupReasons_45896" 438 "WakeupReasons_112031" 437 "WakeupReasons_110173" 436 "WakeupReasons_677781" 435 "WakeupReasons_690939" 434 "WakeupReasons_354809" 433 "WakeupReasons_692022" 432 "WakeupReasons_690593" 431 "WakeupReasons_226571" 430 "WakeupReasons_675594" 429 "WakeupReasons_226565" 428 "WakeupReasons_692020" 427 "WakeupReasons_112035" 426 "WakeupReasons_112027" 425 "WakeupReasons_354672" 424 "WakeupReasons_168967" 423 "WakeupReasons_354674" 422 "WakeupReasons_168968" 421 "WakeupReasons_641483" 420 "WakeupReasons_641482" 419 "WakeupReasons_265698" 418 "WakeupReasons_265699" 417 "WakeupReasons_360491" 416 "WakeupReasons_357498" 415 "WakeupReasons_170290" 414 "WakeupReasons_690385" 413 "WakeupReasons_692021" 412 "WakeupReasons_91254" 411 "WakeupReasons_346654" 410 "WakeupReasons_200637" 409 "WakeupReasons_170285" 408 "WakeupReasons_265678" 407 "WakeupReasons_683934" 406 "WakeupReasons_680763" 405 "WakeupReasons_682074" 404 "WakeupReasons_682154" 403 "WakeupReasons_682152" 402 "WakeupReasons_682155" 401 "WakeupReasons_682153" 400 "WakeupReasons_682078" 399 "WakeupReasons_682076" 398 "WakeupReasons_682077" 397 "WakeupReasons_676285" 396 "WakeupReasons_681023" 395 "WakeupReasons_682023" 394 "WakeupReasons_681789" 393 "WakeupReasons_682688" 392 "WakeupReasons_682037" 391 "WakeupReasons_682032" 390 "WakeupReasons_681915" 389 "WakeupReasons_674839" 388 "WakeupReasons_682034" 387 "WakeupReasons_681711" 386 "WakeupReasons_681031" 385 "WakeupReasons_681134" 384 "WakeupReasons_670462" 383 "WakeupReasons_681028" 382 "WakeupReasons_680975" 381 "WakeupReasons_680974" 380 "WakeupReasons_668523" 379 "WakeupReasons_669822" 378 "WakeupReasons_680712" 377 "WakeupReasons_671005" 376 "WakeupReasons_177214" 375 "WakeupReasons_45655" 374 "WakeupReasons_667872" 373 "WakeupReasons_264964" 372 "WakeupReasons_262871" 371 "WakeupReasons_264691" 370 "WakeupReasons_297056" 369 "WakeupReasons_233755" 368 "WakeupReasons_145161" 367 "WakeupReasons_667842" 366 "WakeupReasons_46020" 365 "WakeupReasons_667874" 364 "WakeupReasons_667981" 363 "WakeupReasons_224211" 362 "WakeupReasons_45902" 361 "WakeupReasons_329457" 360 "WakeupReasons_88458" 359 "WakeupReasons_45900" 358 "WakeupReasons_83199" 357 "WakeupReasons_532933" 356 "WakeupReasons_532932" 355 "WakeupReasons_670942" 354 "WakeupReasons_305818" 353 "WakeupReasons_75103" 352 "WakeupReasons_667987" 351 "WakeupReasons_667983" 350 "WakeupReasons_675745" 349 "WakeupReasons_356598" 348 "WakeupReasons_128671" 347 "WakeupReasons_69216" 346 "WakeupReasons_264697" 345 "WakeupReasons_264943" 344 "WakeupReasons_197644" 343 "WakeupReasons_675564" 342 "WakeupReasons_657120" 341 "WakeupReasons_265745" 340 "WakeupReasons_657121" 339 "WakeupReasons_667982" 338 "WakeupReasons_674223" 337 "WakeupReasons_127926" 336 "WakeupReasons_127924" 335 "WakeupReasons_262872" 334 "WakeupReasons_45848" 333 "WakeupReasons_45847" 332 "WakeupReasons_45846" 331 "WakeupReasons_667869" 330 "WakeupReasons_45890" 329 "WakeupReasons_45888" 328 "WakeupReasons_670962" 327 "WakeupReasons_667973" 326 "WakeupReasons_45877" 325 "WakeupReasons_667980" 324 "WakeupReasons_45876" 323 "WakeupReasons_45871" 322 "WakeupReasons_45875" 321 "WakeupReasons_45872" 320 "WakeupReasons_45870" 319 "WakeupReasons_45869" 318 "WakeupReasons_80608" 317 "WakeupReasons_45898" 316 "WakeupReasons_45897" 315 "WakeupReasons_69679" 314 "WakeupReasons_69678" 313 "WakeupReasons_45887" 312 "WakeupReasons_263473" 311 "WakeupReasons_265131" 310 "WakeupReasons_268983" 309 "WakeupReasons_139075" 308 "WakeupReasons_200090" 307 "WakeupReasons_199714" 306 "WakeupReasons_80609" 305 "WakeupReasons_106669" 304 "WakeupReasons_675742" 303 "WakeupReasons_46017" 302 "WakeupReasons_670354" 301 "WakeupReasons_667985" 300 "WakeupReasons_670966" 299 "WakeupReasons_667871" 298 "WakeupReasons_193474" 297 "WakeupReasons_113348" 296 "WakeupReasons_532556" 295 "WakeupReasons_532555" 294 "WakeupReasons_667988" 293 "WakeupReasons_182918" 292 "WakeupReasons_311279" 291 "WakeupReasons_667848" 290 "WakeupReasons_667850" 289 "WakeupReasons_668393" 288 "WakeupReasons_668395" 287 "WakeupReasons_670753" 286 "WakeupReasons_667922" 285 "WakeupReasons_669447" 284 "WakeupReasons_670928" 283 "WakeupReasons_669465" 282 "WakeupReasons_676265" 281 "WakeupReasons_667947" 280 "WakeupReasons_667879" 279 "WakeupReasons_675837" 278 "WakeupReasons_675494" 277 "WakeupReasons_674958" 276 "WakeupReasons_675064" 275 "WakeupReasons_674953" 274 "WakeupReasons_658188" 273 "WakeupReasons_337991" 272 "WakeupReasons_197653" 271 "WakeupReasons_269140" 270 "WakeupReasons_312881" 269 "WakeupReasons_215560" 268 "WakeupReasons_269034" 267 "WakeupReasons_4471" 266 "WakeupReasons_185490" 265 "WakeupReasons_185457" 264 "WakeupReasons_198452" 263 "WakeupReasons_200683" 262 "WakeupReasons_358832" 261 "WakeupReasons_NMPDUReceived" 260 "WakeupReasons_670345" 259 "WakeupReasons_109467" 258 "WakeupReasons_109466" 257 "WakeupReasons_636801" 256 "WakeupReasons_45849" 255 "WakeupReasons_45850" 254 "WakeupReasons_45851" 253 "WakeupReasons_45852" 252 "WakeupReasons_45854" 251 "WakeupReasons_45853" 250 "WakeupReasons_45856" 249 "WakeupReasons_533872" 248 "WakeupReasons_516327" 247 "WakeupReasons_359559" 246 "WakeupReasons_241902" 245 "WakeupReasons_533372" 244 "WakeupReasons_533371" 243 "WakeupReasons_533370" 242 "WakeupReasons_315981" 241 "WakeupReasons_45858" 240 "WakeupReasons_668529" 239 "WakeupReasons_670087" 238 "WakeupReasons_668531" 237 "WakeupReasons_223920" 236 "WakeupReasons_176748" 235 "WakeupReasons_146470" 234 "WakeupReasons_112799" 233 "WakeupReasons_95949" 232 "WakeupReasons_156440" 231 "WakeupReasons_166267" 230 "WakeupReasons_101727" 229 "WakeupReasons_101728" 228 "WakeupReasons_101725" 227 "WakeupReasons_101706" 226 "WakeupReasons_659350" 225 "WakeupReasons_667820" 224 "WakeupReasons_331194" 223 "WakeupReasons_652546" 222 "WakeupReasons_224553" 221 "WakeupReasons_224552" 220 "WakeupReasons_110885" 219 "WakeupReasons_667953" 218 "WakeupReasons_667962" 217 "WakeupReasons_224550" 216 "WakeupReasons_197665" 215 "WakeupReasons_225961" 214 "WakeupReasons_198433" 213 "WakeupReasons_526438" 212 "WakeupReasons_316796" 211 "WakeupReasons_335068" 210 "WakeupReasons_535214" 209 "WakeupReasons_264726" 208 "WakeupReasons_360542" 207 "WakeupReasons_531743" 206 "WakeupReasons_226967" 205 "WakeupReasons_318382" 204 "WakeupReasons_199159" 203 "WakeupReasons_223715" 202 "WakeupReasons_643973" 201 "WakeupReasons_319401" 200 "WakeupReasons_264712" 199 "WakeupReasons_526426" 198 "WakeupReasons_533050" 197 "WakeupReasons_265937" 196 "WakeupReasons_108834" 195 "WakeupReasons_636556" 194 "WakeupReasons_655340" 193 "WakeupReasons_320895" 192 "WakeupReasons_321077" 191 "WakeupReasons_321323" 190 "WakeupReasons_321319" 189 "WakeupReasons_321057" 188 "WakeupReasons_359187" 187 "WakeupReasons_321317" 186 "WakeupReasons_355214" 185 "WakeupReasons_652361" 184 "WakeupReasons_192030" 183 "WakeupReasons_534145" 182 "WakeupReasons_526445" 181 "WakeupReasons_360299" 180 "WakeupReasons_525705" 179 "WakeupReasons_534077" 178 "WakeupReasons_359211" 177 "WakeupReasons_300681" 176 "WakeupReasons_198484" 175 "WakeupReasons_356549" 174 "WakeupReasons_360543" 173 "WakeupReasons_318342" 172 "WakeupReasons_299547" 171 "WakeupReasons_646109" 170 "WakeupReasons_645753" 169 "WakeupReasons_514502" 168 "WakeupReasons_515804" 167 "WakeupReasons_298808" 166 "WakeupReasons_265330" 165 "WakeupReasons_265328" 164 "WakeupReasons_265305" 163 "WakeupReasons_361279" 162 "WakeupReasons_361272" 161 "WakeupReasons_160596" 160 "WakeupReasons_197648" 159 "WakeupReasons_658603" 158 "WakeupReasons_322857" 157 "WakeupReasons_108810" 156 "WakeupReasons_179103" 155 "WakeupReasons_321845" 154 "WakeupReasons_340667" 153 "WakeupReasons_299117" 152 "WakeupReasons_514503" 151 "WakeupReasons_532007" 150 "WakeupReasons_337565" 149 "WakeupReasons_320631" 148 "WakeupReasons_354791" 147 "WakeupReasons_317616" 146 "WakeupReasons_644550" 145 "WakeupReasons_265232" 144 "WakeupReasons_514545" 143 "WakeupReasons_526429" 142 "WakeupReasons_265569" 141 "WakeupReasons_108841" 140 "WakeupReasons_160602" 139 "WakeupReasons_160597" 138 "WakeupReasons_264958" 137 "WakeupReasons_300682" 136 "WakeupReasons_224634" 135 "WakeupReasons_224617" 134 "WakeupReasons_220322" 133 "WakeupReasons_300427" 132 "WakeupReasons_269156" 131 "WakeupReasons_145462" 130 "WakeupReasons_145454" 129 "WakeupReasons_145419" 128 "WakeupReasons_145288" 127 "WakeupReasons_145373" 126 "WakeupReasons_145385" 125 "WakeupReasons_145362" 124 "WakeupReasons_145399" 123 "WakeupReasons_145388" 122 "WakeupReasons_145330" 121 "WakeupReasons_152774" 120 "WakeupReasons_145319" 119 "WakeupReasons_145311" 118 "WakeupReasons_106774" 117 "WakeupReasons_533044" 116 "WakeupReasons_636692" 115 "WakeupReasons_355409" 114 "WakeupReasons_133749" 113 "WakeupReasons_156412" 112 "WakeupReasons_320287" 111 "WakeupReasons_201348" 110 "WakeupReasons_264962" 109 "WakeupReasons_169884" 108 "WakeupReasons_45867" 107 "WakeupReasons_45866" 106 "WakeupReasons_659549" 105 "WakeupReasons_45864" 104 "WakeupReasons_201815" 103 "WakeupReasons_224831" 102 "WakeupReasons_222553" 101 "WakeupReasons_140678" 100 "WakeupReasons_169945" 99 "WakeupReasons_95444" 98 "WakeupReasons_145688" 97 "WakeupReasons_356190" 96 "WakeupReasons_264934" 95 "WakeupReasons_264932" 94 "WakeupReasons_152786" 93 "WakeupReasons_144970" 92 "WakeupReasons_186489" 91 "WakeupReasons_144897" 90 "WakeupReasons_199172" 89 "WakeupReasons_145707" 88 "WakeupReasons_152237" 87 "WakeupReasons_67182" 86 "WakeupReasons_338820" 85 "WakeupReasons_634710" 84 "WakeupReasons_109387" 83 "WakeupReasons_320126" 82 "WakeupReasons_109367" 81 "WakeupReasons_315364" 80 "WakeupReasons_297868" 79 "WakeupReasons_645810" 78 "WakeupReasons_634696" 77 "WakeupReasons_138997" 76 "WakeupReasons_360006" 75 "WakeupReasons_224061" 74 "WakeupReasons_68481" 73 "WakeupReasons_109364" 72 "WakeupReasons_68644" 71 "WakeupReasons_224065" 70 "WakeupReasons_119273" 69 "WakeupReasons_109382" 68 "WakeupReasons_360008" 67 "WakeupReasons_68676" 66 "WakeupReasons_645094" 65 "WakeupReasons_361509" 64 "WakeupReasons_361505" 63 "WakeupReasons_360904" 62 "WakeupReasons_355601" 61 "WakeupReasons_320277" 60 "WakeupReasons_319422" 59 "WakeupReasons_320282" 58 "WakeupReasons_169894" 57 "WakeupReasons_266860" 56 "WakeupReasons_45656" 55 "WakeupReasons_21997" 54 "WakeupReasons_225696" 53 "WakeupReasons_200156" 52 "WakeupReasons_161066" 51 "WakeupReasons_185670" 50 "WakeupReasons_197826" 49 "WakeupReasons_176921" 48 "WakeupReasons_108776" 47 "WakeupReasons_265333" 46 "WakeupReasons_100281" 45 "WakeupReasons_100278" 44 "WakeupReasons_100300" 43 "WakeupReasons_100275" 42 "WakeupReasons_100298" 41 "WakeupReasons_319139" 40 "WakeupReasons_170807" 39 "WakeupReasons_200937" 38 "WakeupReasons_182033" 37 "WakeupReasons_191050" 36 "WakeupReasons_264876" 35 "WakeupReasons_197642" 34 "WakeupReasons_170865" 33 "WakeupReasons_168966" 32 "WakeupReasons_667948" 31 "WakeupReasons_169655" 30 "WakeupReasons_667945" 29 "WakeupReasons_74188" 28 "WakeupReasons_321583" 27 "WakeupReasons_88125" 26 "WakeupReasons_88123" 25 "WakeupReasons_91253" 24 "WakeupReasons_21973" 23 "WakeupReasons_140084" 22 "WakeupReasons_45657" 21 "WakeupReasons_45659" 20 "WakeupReasons_22100" 19 "WakeupReasons_22013" 18 "WakeupReasons_22005" 17 "WakeupReasons_45794" 16 "WakeupReasons_45793" 15 "WakeupReasons_21901" 14 "WakeupReasons_658500" 13 "WakeupReasons_269739" 12 "WakeupReasons_269735" 11 "WakeupReasons_269740" 10 "WakeupReasons_22060" 9 "WakeupReasons_49446" 8 "WakeupReasons_22058" 7 "WakeupReasons_45654" 6 "WakeupReasons_264933" 5 "WakeupReasons_197643" 4 "WakeupReasons_168965" 3 "WakeupReasons_667951" 2 "WakeupReasons_169654" 1 "WakeupReasons_667950" 0 "WakeupReasons_0" ;
VAL_ 1346 VFCVectorOGMVFCid0 1 "VFCOnOff_On" 0 "VFCOnOff_Off" ;
VAL_ 1346 VFCVectorOGMVFCid1 1 "VFCOnOff_On" 0 "VFCOnOff_Off" ;
VAL_ 1346 VFCVectorOGMVFCid10 1 "VFCOnOff_On" 0 "VFCOnOff_Off" ;
VAL_ 1346 VFCVectorOGMVFCid11 1 "VFCOnOff_On" 0 "VFCOnOff_Off" ;
VAL_ 1346 VFCVectorOGMVFCid12 1 "VFCOnOff_On" 0 "VFCOnOff_Off" ;
VAL_ 1346 VFCVectorOGMVFCid13 1 "VFCOnOff_On" 0 "VFCOnOff_Off" ;
VAL_ 1346 VFCVectorOGMVFCid14 1 "VFCOnOff_On" 0 "VFCOnOff_Off" ;
VAL_ 1346 VFCVectorOGMVFCid15 1 "VFCOnOff_On" 0 "VFCOnOff_Off" ;
VAL_ 1346 VFCVectorOGMVFCid16 1 "VFCOnOff_On" 0 "VFCOnOff_Off" ;
VAL_ 1346 VFCVectorOGMVFCid17 1 "VFCOnOff_On" 0 "VFCOnOff_Off" ;
VAL_ 1346 VFCVectorOGMVFCid18 1 "VFCOnOff_On" 0 "VFCOnOff_Off" ;
VAL_ 1346 VFCVectorOGMVFCid19 1 "VFCOnOff_On" 0 "VFCOnOff_Off" ;
VAL_ 1346 VFCVectorOGMVFCid2 1 "VFCOnOff_On" 0 "VFCOnOff_Off" ;
VAL_ 1346 VFCVectorOGMVFCid20 1 "VFCOnOff_On" 0 "VFCOnOff_Off" ;
VAL_ 1346 VFCVectorOGMVFCid21 1 "VFCOnOff_On" 0 "VFCOnOff_Off" ;
VAL_ 1346 VFCVectorOGMVFCid22 1 "VFCOnOff_On" 0 "VFCOnOff_Off" ;
VAL_ 1346 VFCVectorOGMVFCid23 1 "VFCOnOff_On" 0 "VFCOnOff_Off" ;
VAL_ 1346 VFCVectorOGMVFCid24 1 "VFCOnOff_On" 0 "VFCOnOff_Off" ;
VAL_ 1346 VFCVectorOGMVFCid25 1 "VFCOnOff_On" 0 "VFCOnOff_Off" ;
VAL_ 1346 VFCVectorOGMVFCid26 1 "VFCOnOff_On" 0 "VFCOnOff_Off" ;
VAL_ 1346 VFCVectorOGMVFCid27 1 "VFCOnOff_On" 0 "VFCOnOff_Off" ;
VAL_ 1346 VFCVectorOGMVFCid28 1 "VFCOnOff_On" 0 "VFCOnOff_Off" ;
VAL_ 1346 VFCVectorOGMVFCid29 1 "VFCOnOff_On" 0 "VFCOnOff_Off" ;
VAL_ 1346 VFCVectorOGMVFCid3 1 "VFCOnOff_On" 0 "VFCOnOff_Off" ;
VAL_ 1346 VFCVectorOGMVFCid30 1 "VFCOnOff_On" 0 "VFCOnOff_Off" ;
VAL_ 1346 VFCVectorOGMVFCid31 1 "VFCOnOff_On" 0 "VFCOnOff_Off" ;
VAL_ 1346 VFCVectorOGMVFCid32 1 "VFCOnOff_On" 0 "VFCOnOff_Off" ;
VAL_ 1346 VFCVectorOGMVFCid33 1 "VFCOnOff_On" 0 "VFCOnOff_Off" ;
VAL_ 1346 VFCVectorOGMVFCid34 1 "VFCOnOff_On" 0 "VFCOnOff_Off" ;
VAL_ 1346 VFCVectorOGMVFCid35 1 "VFCOnOff_On" 0 "VFCOnOff_Off" ;
VAL_ 1346 VFCVectorOGMVFCid36 1 "VFCOnOff_On" 0 "VFCOnOff_Off" ;
VAL_ 1346 VFCVectorOGMVFCid37 1 "VFCOnOff_On" 0 "VFCOnOff_Off" ;
VAL_ 1346 VFCVectorOGMVFCid38 1 "VFCOnOff_On" 0 "VFCOnOff_Off" ;
VAL_ 1346 VFCVectorOGMVFCid39 1 "VFCOnOff_On" 0 "VFCOnOff_Off" ;
VAL_ 1346 VFCVectorOGMVFCid4 1 "VFCOnOff_On" 0 "VFCOnOff_Off" ;
VAL_ 1346 VFCVectorOGMVFCid40 1 "VFCOnOff_On" 0 "VFCOnOff_Off" ;
VAL_ 1346 VFCVectorOGMVFCid41 1 "VFCOnOff_On" 0 "VFCOnOff_Off" ;
VAL_ 1346 VFCVectorOGMVFCid42 1 "VFCOnOff_On" 0 "VFCOnOff_Off" ;
VAL_ 1346 VFCVectorOGMVFCid43 1 "VFCOnOff_On" 0 "VFCOnOff_Off" ;
VAL_ 1346 VFCVectorOGMVFCid44 1 "VFCOnOff_On" 0 "VFCOnOff_Off" ;
VAL_ 1346 VFCVectorOGMVFCid45 1 "VFCOnOff_On" 0 "VFCOnOff_Off" ;
VAL_ 1346 VFCVectorOGMVFCid46 1 "VFCOnOff_On" 0 "VFCOnOff_Off" ;
VAL_ 1346 VFCVectorOGMVFCid47 1 "VFCOnOff_On" 0 "VFCOnOff_Off" ;
VAL_ 1346 VFCVectorOGMVFCid48 1 "VFCOnOff_On" 0 "VFCOnOff_Off" ;
VAL_ 1346 VFCVectorOGMVFCid49 1 "VFCOnOff_On" 0 "VFCOnOff_Off" ;
VAL_ 1346 VFCVectorOGMVFCid5 1 "VFCOnOff_On" 0 "VFCOnOff_Off" ;
VAL_ 1346 VFCVectorOGMVFCid50 1 "VFCOnOff_On" 0 "VFCOnOff_Off" ;
VAL_ 1346 VFCVectorOGMVFCid51 1 "VFCOnOff_On" 0 "VFCOnOff_Off" ;
VAL_ 1346 VFCVectorOGMVFCid52 1 "VFCOnOff_On" 0 "VFCOnOff_Off" ;
VAL_ 1346 VFCVectorOGMVFCid53 1 "VFCOnOff_On" 0 "VFCOnOff_Off" ;
VAL_ 1346 VFCVectorOGMVFCid54 1 "VFCOnOff_On" 0 "VFCOnOff_Off" ;
VAL_ 1346 VFCVectorOGMVFCid55 1 "VFCOnOff_On" 0 "VFCOnOff_Off" ;
VAL_ 1346 VFCVectorOGMVFCid56 1 "VFCOnOff_On" 0 "VFCOnOff_Off" ;
VAL_ 1346 VFCVectorOGMVFCid57 1 "VFCOnOff_On" 0 "VFCOnOff_Off" ;
VAL_ 1346 VFCVectorOGMVFCid58 1 "VFCOnOff_On" 0 "VFCOnOff_Off" ;
VAL_ 1346 VFCVectorOGMVFCid59 1 "VFCOnOff_On" 0 "VFCOnOff_Off" ;
VAL_ 1346 VFCVectorOGMVFCid6 1 "VFCOnOff_On" 0 "VFCOnOff_Off" ;
VAL_ 1346 VFCVectorOGMVFCid60 1 "VFCOnOff_On" 0 "VFCOnOff_Off" ;
VAL_ 1346 VFCVectorOGMVFCid61 1 "VFCOnOff_On" 0 "VFCOnOff_Off" ;
VAL_ 1346 VFCVectorOGMVFCid7 1 "VFCOnOff_On" 0 "VFCOnOff_Off" ;
VAL_ 1346 VFCVectorOGMVFCid8 1 "VFCOnOff_On" 0 "VFCOnOff_Off" ;
VAL_ 1346 VFCVectorOGMVFCid9 1 "VFCOnOff_On" 0 "VFCOnOff_Off" ;
VAL_ 416 TrCrashUnlckSts 1 "Unlck" 0 "Default" ;
VAL_ 149 TrInsdOpenSwtSts 1 "PsdNotPsd_Psd" 0 "PsdNotPsd_NotPsd" ;
VAL_ 578 TrCinhSwt 1 "PsdNotPsd1_Psd" 0 "PsdNotPsd1_NotPsd" ;
VAL_ 578 TrLatPosn 3 "DoorPos_FullyOpen" 2 "DoorPos_SecondaryPosition" 1 "DoorPos_FullyClosed" 0 "DoorPos_Undefined" ;
VAL_ 803 SecRowLeHeatgLvl 3 "SeatClimaLvl_Lvl3" 2 "SeatClimaLvl_Lvl2" 1 "SeatClimaLvl_Lvl1" 0 "SeatClimaLvl_Off" ;
VAL_ 803 SecRowLeVentnLvl 3 "SeatClimaLvl_Lvl3" 2 "SeatClimaLvl_Lvl2" 1 "SeatClimaLvl_Lvl1" 0 "SeatClimaLvl_Off" ;
VAL_ 262 RowReLeModSwtSts 1 "OnOff1_On" 0 "OnOff1_Off" ;
VAL_ 261 RowReRiModSwtSts 1 "OnOff1_On" 0 "OnOff1_Off" ;
VAL_ 137 AgDataRawSafeRollRateQf 3 "Qf1_DataCalcdWithDevDefd" 2 "Qf1_DevOfDataNotWithinRngAllwd" 1 "Qf1_DataTmpUndefdAndEvlnInProgs" 0 "Qf1_DevOfDataUndefd" ;
VAL_ 137 AgDataRawSafeYawRateQf 3 "Qf1_DataCalcdWithDevDefd" 2 "Qf1_DevOfDataNotWithinRngAllwd" 1 "Qf1_DataTmpUndefdAndEvlnInProgs" 0 "Qf1_DevOfDataUndefd" ;
VAL_ 137 BltLockStAtDrvrBltLockSt1 1 "BltLockSt1_Lock" 0 "BltLockSt1_Unlock" ;
VAL_ 137 BltLockStAtDrvrBltLockSts 1 "DevErrSts2_Flt" 0 "DevErrSts2_NoFlt" ;
VAL_ 137 BltLockStAtPassBltLockSt1 1 "BltLockSt1_Lock" 0 "BltLockSt1_Unlock" ;
VAL_ 137 BltLockStAtPassBltLockSts 1 "DevErrSts2_Flt" 0 "DevErrSts2_NoFlt" ;
VAL_ 16 CrashStsSafeSts 1 "CrashSts2_Crash" 0 "CrashSts2_NoCrash" ;
VAL_ 16 PassAirbStsChgNotifReq 1 "ReqForDisp_IndcnReqd" 0 "ReqForDisp_Idle" ;
VAL_ 18 ADataRawSafeALat1Qf 3 "Qf1_DataCalcdWithDevDefd" 2 "Qf1_DevOfDataNotWithinRngAllwd" 1 "Qf1_DataTmpUndefdAndEvlnInProgs" 0 "Qf1_DevOfDataUndefd" ;
VAL_ 18 ADataRawSafeALgt1Qf 3 "Qf1_DataCalcdWithDevDefd" 2 "Qf1_DevOfDataNotWithinRngAllwd" 1 "Qf1_DataTmpUndefdAndEvlnInProgs" 0 "Qf1_DevOfDataUndefd" ;
VAL_ 18 ADataRawSafeAVertQf 3 "Qf1_DataCalcdWithDevDefd" 2 "Qf1_DevOfDataNotWithinRngAllwd" 1 "Qf1_DataTmpUndefdAndEvlnInProgs" 0 "Qf1_DevOfDataUndefd" ;
VAL_ 19 AsyDataWithCmpSafeALat1Qf 3 "Qf1_DataCalcdWithDevDefd" 2 "Qf1_DevOfDataNotWithinRngAllwd" 1 "Qf1_DataTmpUndefdAndEvlnInProgs" 0 "Qf1_DevOfDataUndefd" ;
VAL_ 19 AsyDataWithCmpSafeALgt1Qf 3 "Qf1_DataCalcdWithDevDefd" 2 "Qf1_DevOfDataNotWithinRngAllwd" 1 "Qf1_DataTmpUndefdAndEvlnInProgs" 0 "Qf1_DevOfDataUndefd" ;
VAL_ 19 AsyDataWithCmpSafeYawRateQf 3 "Qf1_DataCalcdWithDevDefd" 2 "Qf1_DevOfDataNotWithinRngAllwd" 1 "Qf1_DataTmpUndefdAndEvlnInProgs" 0 "Qf1_DevOfDataUndefd" ;
VAL_ 33 ActvnReqOfRtrctrRvsbLe 4 "Resd2" 3 "Resd1" 2 "ActvnFHi" 1 "ActvnFLo" 0 "NoActvn" ;
VAL_ 33 ActvnReqOfRtrctrRvsbRi 4 "Resd2" 3 "Resd1" 2 "ActvnFHi" 1 "ActvnFLo" 0 "NoActvn" ;
VAL_ 33 BltLockStSafeAtDrvrBltLockSt1 1 "BltLockSt1_Lock" 0 "BltLockSt1_Unlock" ;
VAL_ 33 BltLockStSafeAtDrvrBltLockStErrS 1 "DevErrSts2_Flt" 0 "DevErrSts2_NoFlt" ;
VAL_ 33 BrkPedlSts 1 "OkNotOk1_NotOk" 0 "OkNotOk1_Ok" ;
VAL_ 33 CrashSts2 3 "CrashSts4_SlightCrash" 2 "CrashSts4_Crash" 1 "CrashSts4_NoCrash" 0 "CrashSts4_Resd1" ;
VAL_ 549 BltLockStAtPassMidBltLockEquid 1 "CptEquid_NotEquid" 0 "CptEquid_Equid" ;
VAL_ 549 BltLockStAtPassMidBltLockSt1 1 "BltLockSt1_Lock" 0 "BltLockSt1_Unlock" ;
VAL_ 549 BltLockStAtPassMidBltLockSts 1 "DevErrSts2_Flt" 0 "DevErrSts2_NoFlt" ;
VAL_ 549 BltLockStAtRowFrthLeBltLockEquid 1 "CptEquid_NotEquid" 0 "CptEquid_Equid" ;
VAL_ 549 BltLockStAtRowFrthLeBltLockSt1 1 "BltLockSt1_Lock" 0 "BltLockSt1_Unlock" ;
VAL_ 549 BltLockStAtRowFrthLeBltLockSts 1 "DevErrSts2_Flt" 0 "DevErrSts2_NoFlt" ;
VAL_ 549 BltLockStAtRowFrthMidBltLockEqui 1 "CptEquid_NotEquid" 0 "CptEquid_Equid" ;
VAL_ 549 BltLockStAtRowFrthMidBltLockSt1 1 "BltLockSt1_Lock" 0 "BltLockSt1_Unlock" ;
VAL_ 549 BltLockStAtRowFrthMidBltLockSts 1 "DevErrSts2_Flt" 0 "DevErrSts2_NoFlt" ;
VAL_ 549 BltLockStAtRowFrthRiBltLockEquid 1 "CptEquid_NotEquid" 0 "CptEquid_Equid" ;
VAL_ 549 BltLockStAtRowFrthRiBltLockSt1 1 "BltLockSt1_Lock" 0 "BltLockSt1_Unlock" ;
VAL_ 549 BltLockStAtRowFrthRiBltLockSts 1 "DevErrSts2_Flt" 0 "DevErrSts2_NoFlt" ;
VAL_ 549 BltLockStAtRowThrdMidBltLockEqui 1 "CptEquid_NotEquid" 0 "CptEquid_Equid" ;
VAL_ 549 BltLockStAtRowThrdMidBltLockSt1 1 "BltLockSt1_Lock" 0 "BltLockSt1_Unlock" ;
VAL_ 549 BltLockStAtRowThrdMidBltLockSts 1 "DevErrSts2_Flt" 0 "DevErrSts2_NoFlt" ;
VAL_ 549 SeatOccptAtRowFrthLe 3 "PassSeatSts1_Ukwn" 2 "PassSeatSts1_OccptLrg" 1 "PassSeatSts1_Fmale" 0 "PassSeatSts1_Empty" ;
VAL_ 549 SeatOccptAtRowFrthMid 3 "PassSeatSts1_Ukwn" 2 "PassSeatSts1_OccptLrg" 1 "PassSeatSts1_Fmale" 0 "PassSeatSts1_Empty" ;
VAL_ 549 SeatOccptAtRowFrthRi 3 "PassSeatSts1_Ukwn" 2 "PassSeatSts1_OccptLrg" 1 "PassSeatSts1_Fmale" 0 "PassSeatSts1_Empty" ;
VAL_ 549 SeatOccptAtRowThrdMid 3 "PassSeatSts1_Ukwn" 2 "PassSeatSts1_OccptLrg" 1 "PassSeatSts1_Fmale" 0 "PassSeatSts1_Empty" ;
VAL_ 322 AgDataRaw2SafePitchRateQf 3 "Qf1_DataCalcdWithDevDefd" 2 "Qf1_DevOfDataNotWithinRngAllwd" 1 "Qf1_DataTmpUndefdAndEvlnInProgs" 0 "Qf1_DevOfDataUndefd" ;
VAL_ 322 PassAirbLampReqChgOfPassAirbSts 1 "ReqForDisp_IndcnReqd" 0 "ReqForDisp_Idle" ;
VAL_ 322 PassAirbLampReqPassAirbLampDiReq 3 "PassAirbLampReq_Resd" 2 "PassAirbLampReq_LampOff" 1 "PassAirbLampReq_LampOn" 0 "PassAirbLampReq_LampNotCfgd" ;
VAL_ 322 PassAirbLampReqPassAirbLampEnaRe 3 "PassAirbLampReq_Resd" 2 "PassAirbLampReq_LampOff" 1 "PassAirbLampReq_LampOn" 0 "PassAirbLampReq_LampNotCfgd" ;
VAL_ 322 ReqForAsyDataStorgFromRestrntSys 1 "Boolean_TRUE" 0 "Boolean_FALSE" ;
VAL_ 322 ReqForHzrdInt 1 "ReqForHzrdInt_LowerCrash" 0 "ReqForHzrdInt_NoLowerCrash" ;
VAL_ 322 SftyAirbRollovrSuppSts 1 "OnOff1_On" 0 "OnOff1_Off" ;
VAL_ 864 BltCrashNotifDrvr 3 "NoYesCrit1_NotVld2" 2 "NoYesCrit1_Yes" 1 "NoYesCrit1_No" 0 "NoYesCrit1_NotVld1" ;
VAL_ 864 BltCrashNotifPass 3 "NoYesCrit1_NotVld2" 2 "NoYesCrit1_Yes" 1 "NoYesCrit1_No" 0 "NoYesCrit1_NotVld1" ;
VAL_ 864 PassAirbSts 1 "OnOff2_Off" 0 "OnOff2_On" ;
VAL_ 864 PedProtnMsgReqForFlt 3 "OnOffCrit1_NotVld2" 2 "OnOffCrit1_On" 1 "OnOffCrit1_Off" 0 "OnOffCrit1_NotVld1" ;
VAL_ 864 PedProtnMsgReqForImpct 1 "OnOff1_On" 0 "OnOff1_Off" ;
VAL_ 864 RecOfImpctCrashFrnt 1 "Boolean_TRUE" 0 "Boolean_FALSE" ;
VAL_ 864 RecOfImpctCrashOffroadA 1 "Boolean_TRUE" 0 "Boolean_FALSE" ;
VAL_ 864 RecOfImpctCrashOffroadD 1 "Boolean_TRUE" 0 "Boolean_FALSE" ;
VAL_ 864 RecOfImpctCrashOffroadRT 1 "Boolean_TRUE" 0 "Boolean_FALSE" ;
VAL_ 864 RecOfImpctCrashOffroadRTsevere 1 "Boolean_TRUE" 0 "Boolean_FALSE" ;
VAL_ 864 RecOfImpctCrashPed 1 "Boolean_TRUE" 0 "Boolean_FALSE" ;
VAL_ 864 RecOfImpctCrashRe 1 "Boolean_TRUE" 0 "Boolean_FALSE" ;
VAL_ 864 RecOfImpctCrashRollovr 1 "Boolean_TRUE" 0 "Boolean_FALSE" ;
VAL_ 864 RecOfImpctCrashSideLe 1 "Boolean_TRUE" 0 "Boolean_FALSE" ;
VAL_ 864 RecOfImpctCrashSideRi 1 "Boolean_TRUE" 0 "Boolean_FALSE" ;
VAL_ 864 RecOfImpctCrashState 3 "CrashSt_CrashEnding" 2 "CrashSt_CrashInProgress" 1 "CrashSt_CrashImminent" 0 "CrashSt_NoCrash" ;
VAL_ 864 RecOfImpctVehOri 7 "Orntn_Resd3" 6 "Orntn_Resd2" 5 "Orntn_Resd1" 4 "Orntn_Indeterminate" 3 "Orntn_OnRoof" 2 "Orntn_RightSide" 1 "Orntn_LeftSide" 0 "Orntn_OnWheels" ;
VAL_ 864 RestrntSysLampReq 3 "RestrntSysLampReq_LampOn" 2 "RestrntSysLampReq_LampFlash" 1 "RestrntSysLampReq_Ukwn" 0 "RestrntSysLampReq_LampOff" ;
VAL_ 864 RestrntSysMsgReq 3 "OnOffCrit1_NotVld2" 2 "OnOffCrit1_On" 1 "OnOffCrit1_Off" 0 "OnOffCrit1_NotVld1" ;
VAL_ 864 SafetyCrashFb 3 "CrashFb_Ok" 2 "CrashFb_Nok" 1 "CrashFb_Evln" 0 "CrashFb_Idle" ;
VAL_ 112 BltLockStAtRowSecLeBltLockEquid 1 "CptEquid_NotEquid" 0 "CptEquid_Equid" ;
VAL_ 112 BltLockStAtRowSecLeBltLockSt1 1 "BltLockSt1_Lock" 0 "BltLockSt1_Unlock" ;
VAL_ 112 BltLockStAtRowSecLeBltLockSts 1 "DevErrSts2_Flt" 0 "DevErrSts2_NoFlt" ;
VAL_ 112 BltLockStAtRowSecMidBltLockEquid 1 "CptEquid_NotEquid" 0 "CptEquid_Equid" ;
VAL_ 112 BltLockStAtRowSecMidBltLockSt1 1 "BltLockSt1_Lock" 0 "BltLockSt1_Unlock" ;
VAL_ 112 BltLockStAtRowSecMidBltLockSts 1 "DevErrSts2_Flt" 0 "DevErrSts2_NoFlt" ;
VAL_ 112 BltLockStAtRowSecRiBltLockEquid 1 "CptEquid_NotEquid" 0 "CptEquid_Equid" ;
VAL_ 112 BltLockStAtRowSecRiBltLockSt1 1 "BltLockSt1_Lock" 0 "BltLockSt1_Unlock" ;
VAL_ 112 BltLockStAtRowSecRiBltLockSts 1 "DevErrSts2_Flt" 0 "DevErrSts2_NoFlt" ;
VAL_ 112 BltLockStAtRowThrdLeBltLockEquid 1 "CptEquid_NotEquid" 0 "CptEquid_Equid" ;
VAL_ 112 BltLockStAtRowThrdLeBltLockSt1 1 "BltLockSt1_Lock" 0 "BltLockSt1_Unlock" ;
VAL_ 112 BltLockStAtRowThrdLeBltLockSts 1 "DevErrSts2_Flt" 0 "DevErrSts2_NoFlt" ;
VAL_ 112 BltLockStAtRowThrdRiBltLockEquid 1 "CptEquid_NotEquid" 0 "CptEquid_Equid" ;
VAL_ 112 BltLockStAtRowThrdRiBltLockSt1 1 "BltLockSt1_Lock" 0 "BltLockSt1_Unlock" ;
VAL_ 112 BltLockStAtRowThrdRiBltLockSts 1 "DevErrSts2_Flt" 0 "DevErrSts2_NoFlt" ;
VAL_ 112 RecOfPostImpctBrkgSuspcSuspcPost 3 "PostImpctBrkgNoYes_Undefd3" 2 "PostImpctBrkgNoYes_Yes" 1 "PostImpctBrkgNoYes_No" 0 "PostImpctBrkgNoYes_Undefd0" ;
VAL_ 559 DstTrvldVldFromSftyBkp 1 "InvldVld1_Vld" 0 "InvldVld1_Invld" ;
VAL_ 559 NotifForEmgyCall 1 "Boolean_TRUE" 0 "Boolean_FALSE" ;
VAL_ 559 PassMidSeatSts 3 "PassSeatSts1_Ukwn" 2 "PassSeatSts1_OccptLrg" 1 "PassSeatSts1_Fmale" 0 "PassSeatSts1_Empty" ;
VAL_ 328 RecOfPostImpctBrkgCfmdCrashFrnt 3 "PostImpctBrkgNoYes_Undefd3" 2 "PostImpctBrkgNoYes_Yes" 1 "PostImpctBrkgNoYes_No" 0 "PostImpctBrkgNoYes_Undefd0" ;
VAL_ 328 RecOfPostImpctBrkgCfmdCrashLarge 3 "PostImpctBrkgNoYes_Undefd3" 2 "PostImpctBrkgNoYes_Yes" 1 "PostImpctBrkgNoYes_No" 0 "PostImpctBrkgNoYes_Undefd0" ;
VAL_ 328 RecOfPostImpctBrkgCfmdCrashOffro 3 "PostImpctBrkgNoYes_Undefd3" 2 "PostImpctBrkgNoYes_Yes" 1 "PostImpctBrkgNoYes_No" 0 "PostImpctBrkgNoYes_Undefd0" ;
VAL_ 328 RecOfPostImpctBrkgCfmdCrash_0000 3 "PostImpctBrkgNoYes_Undefd3" 2 "PostImpctBrkgNoYes_Yes" 1 "PostImpctBrkgNoYes_No" 0 "PostImpctBrkgNoYes_Undefd0" ;
VAL_ 328 RecOfPostImpctBrkgCfmdCrash_0001 3 "PostImpctBrkgNoYes_Undefd3" 2 "PostImpctBrkgNoYes_Yes" 1 "PostImpctBrkgNoYes_No" 0 "PostImpctBrkgNoYes_Undefd0" ;
VAL_ 328 RecOfPostImpctBrkgCfmdCrash_0002 3 "PostImpctBrkgNoYes_Undefd3" 2 "PostImpctBrkgNoYes_Yes" 1 "PostImpctBrkgNoYes_No" 0 "PostImpctBrkgNoYes_Undefd0" ;
VAL_ 328 RecOfPostImpctBrkgCfmdCrashOz 3 "PostImpctBrkgNoYes_Undefd3" 2 "PostImpctBrkgNoYes_Yes" 1 "PostImpctBrkgNoYes_No" 0 "PostImpctBrkgNoYes_Undefd0" ;
VAL_ 328 RecOfPostImpctBrkgCfmdCrashPed 3 "PostImpctBrkgNoYes_Undefd3" 2 "PostImpctBrkgNoYes_Yes" 1 "PostImpctBrkgNoYes_No" 0 "PostImpctBrkgNoYes_Undefd0" ;
VAL_ 328 RecOfPostImpctBrkgCfmdCrashRe 3 "PostImpctBrkgNoYes_Undefd3" 2 "PostImpctBrkgNoYes_Yes" 1 "PostImpctBrkgNoYes_No" 0 "PostImpctBrkgNoYes_Undefd0" ;
VAL_ 328 RecOfPostImpctBrkgCfmdCrashRollo 3 "PostImpctBrkgNoYes_Undefd3" 2 "PostImpctBrkgNoYes_Yes" 1 "PostImpctBrkgNoYes_No" 0 "PostImpctBrkgNoYes_Undefd0" ;
VAL_ 328 RecOfPostImpctBrkgCfmdCrashSideL 3 "PostImpctBrkgNoYes_Undefd3" 2 "PostImpctBrkgNoYes_Yes" 1 "PostImpctBrkgNoYes_No" 0 "PostImpctBrkgNoYes_Undefd0" ;
VAL_ 328 RecOfPostImpctBrkgCfmdCrashSideR 3 "PostImpctBrkgNoYes_Undefd3" 2 "PostImpctBrkgNoYes_Yes" 1 "PostImpctBrkgNoYes_No" 0 "PostImpctBrkgNoYes_Undefd0" ;
VAL_ 328 RecOfPostImpctBrkgCfmdPostImpctB 3 "PostImpctBrkgNoYes_Undefd3" 2 "PostImpctBrkgNoYes_Yes" 1 "PostImpctBrkgNoYes_No" 0 "PostImpctBrkgNoYes_Undefd0" ;
VAL_ 628 HVfault 1 "Boolean_TRUE" 0 "Boolean_FALSE" ;
VAL_ 1307 WakeUpReasonsforSRS 741 "WakeupReasons_871868" 740 "WakeupReasons_871957" 739 "WakeupReasons_871729" 738 "WakeupReasons_700779" 737 "WakeupReasons_839414" 736 "WakeupReasons_675025" 735 "WakeupReasons_671146" 734 "WakeupReasons_1031929" 733 "WakeupReasons_1033548" 732 "WakeupReasons_1033537" 731 "WakeupReasons_1033479" 730 "WakeupReasons_1030765" 729 "WakeupReasons_1028674" 728 "WakeupReasons_1033567" 727 "WakeupReasons_1033543" 726 "WakeupReasons_1033549" 725 "WakeupReasons_1033554" 724 "WakeupReasons_1033563" 723 "WakeupReasons_1033558" 722 "WakeupReasons_1029384" 721 "WakeupReasons_1029383" 720 "WakeupReasons_1029382" 719 "WakeupReasons_1032619" 718 "WakeupReasons_1024928" 717 "WakeupReasons_1033547" 716 "WakeupReasons_1033541" 715 "WakeupReasons_1033562" 714 "WakeupReasons_1033564" 713 "WakeupReasons_986765" 712 "WakeupReasons_1026103" 711 "WakeupReasons_1030764" 710 "WakeupReasons_1030941" 709 "WakeupReasons_1033556" 708 "WakeupReasons_1033539" 707 "WakeupReasons_1033534" 706 "WakeupReasons_1032477" 705 "WakeupReasons_1031280" 704 "WakeupReasons_1033542" 703 "WakeupReasons_1033632" 702 "WakeupReasons_1033533" 701 "WakeupReasons_1029166" 700 "WakeupReasons_1033538" 699 "WakeupReasons_1031789" 698 "WakeupReasons_1033552" 697 "WakeupReasons_1033553" 696 "WakeupReasons_1033559" 695 "WakeupReasons_1033544" 694 "WakeupReasons_1033561" 693 "WakeupReasons_1031029" 692 "WakeupReasons_1030360" 691 "WakeupReasons_1030761" 690 "WakeupReasons_1033550" 689 "WakeupReasons_1032579" 688 "WakeupReasons_1033557" 687 "WakeupReasons_1031936" 686 "WakeupReasons_1033566" 685 "WakeupReasons_1033551" 684 "WakeupReasons_1033540" 683 "WakeupReasons_1030760" 682 "WakeupReasons_1029735" 681 "WakeupReasons_1033565" 680 "WakeupReasons_852370" 679 "WakeupReasons_1033555" 678 "WakeupReasons_1033546" 677 "WakeupReasons_1032743" 676 "WakeupReasons_1032791" 675 "WakeupReasons_1033569" 674 "WakeupReasons_1031030" 673 "WakeupReasons_1028778" 672 "WakeupReasons_1030759" 671 "WakeupReasons_1031907" 670 "WakeupReasons_1033560" 669 "WakeupReasons_1031288" 668 "WakeupReasons_1030302" 667 "WakeupReasons_1031765" 666 "WakeupReasons_1031990" 665 "WakeupReasons_1028729" 664 "WakeupReasons_1030362" 663 "WakeupReasons_1030361" 662 "WakeupReasons_1030297" 661 "WakeupReasons_1030293" 660 "WakeupReasons_527345" 659 "WakeupReasons_988154" 658 "WakeupReasons_533580" 657 "WakeupReasons_533581" 656 "WakeupReasons_533576" 655 "WakeupReasons_1030255" 654 "WakeupReasons_527348" 653 "WakeupReasons_533578" 652 "WakeupReasons_527347" 651 "WakeupReasons_527346" 650 "WakeupReasons_ADCUReserve" 649 "WakeupReasons_885767" 648 "WakeupReasons_909025" 647 "WakeupReasons_909026" 646 "WakeupReasons_858177" 645 "WakeupReasons_858169" 644 "WakeupReasons_858152" 643 "WakeupReasons_973575" 642 "WakeupReason_973574" 641 "WakeupReason_987405" 640 "WakeupReason_858187" 639 "WakeupReason_988826" 638 "WakeupReason_988821" 637 "WakeupReason_987485" 636 "WakeupReason_908128" 635 "WakeupReason_908115" 634 "WakeupReason_856234" 633 "WakeupReason_856224" 632 "WakeupReason_858189" 631 "WakeupReason_858188" 630 "WakeupReason_872056" 629 "WakeupReason_870276" 628 "WakeupReason_858191" 627 "WakeupReason_847054" 626 "WakeupReason_856465" 625 "WakeupReason_872253" 624 "WakeupReason_855003" 623 "WakeupReason_855002" 622 "WakeupReason_854947" 621 "WakeupReason_855134" 620 "WakeupReason_854839" 619 "WakeupReason_854999" 618 "WakeupReason_855029" 617 "WakeupReason_714340" 616 "WakeupReason_852947" 615 "WakeupReason_852944" 614 "WakeupReason_852646" 613 "WakeupReason_852537" 612 "WakeupReason_852388" 611 "WakeupReason_852385" 610 "WakeupReason_852298" 609 "WakeupReason_852273" 608 "WakeupReason_852248" 607 "WakeupReason_852219" 606 "WakeupReason_852218" 605 "WakeupReason_852215" 604 "WakeupReason_852200" 603 "WakeupReason_852195" 602 "WakeupReason_852194" 601 "WakeupReason_852184" 600 "WakeupReason_852180" 599 "WakeupReason_852050" 598 "WakeupReason_852010" 597 "WakeupReason_851743" 596 "WakeupReason_851482" 595 "WakeupReason_702420" 594 "WakeupReason_667533" 593 "WakeupReason_645735" 592 "WakeupReason_362462" 591 "WakeupReason_361474" 590 "WakeupReason_361441" 589 "WakeupReason_846002" 588 "WakeupReason_845930" 587 "WakeupReason_842273" 586 "WakeupReason_846372" 585 "WakeupReason_675489" 584 "WakeupReason_675452" 583 "WakeupReason_298032" 582 "WakeupReason_322113" 581 "WakeupReason_320145" 580 "WakeupReason_841275" 579 "WakeupReason_839787" 578 "WakeupReason_839181" 577 "WakeupReason_714677" 576 "WakeupReason_840035" 566 "WakeupReason_839458" 565 "WakeupReason_837760" 564 "WakeupReason_702903" 563 "WakeupReason_837962" 562 "WakeupReason_703140" 561 "WakeupReason_837833" 560 "WakeupReason_839705" 559 "WakeupReason_839473" 558 "WakeupReason_838116" 557 "WakeupReason_717832" 556 "WakeupReason_714697" 555 "WakeupReason_714799" 554 "WakeupReason_714806" 553 "WakeupReason_709196" 552 "WakeupReason_710893" 551 "WakeupReason_708964" 550 "WakeupReason_715529" 549 "WakeupReason_714265" 548 "WakeupReason_714172" 547 "WakeupReason_713799" 546 "WakeupReason_706194" 545 "WakeupReason_713568" 544 "WakeupReason_710807" 543 "WakeupReason_714679" 542 "WakeupReason_714678" 541 "WakeupReason_715842" 540 "WakeupReason_714030" 539 "WakeupReason_710922" 538 "WakeupReason_716243" 537 "WakeupReason_713786" 536 "WakeupReason_714675" 535 "WakeupReason_702478" 534 "WakeupReason_713752" 533 "WakeupReasons_700530" 532 "WakeupReasons_698631" 531 "WakeupReasons_702452" 530 "WakeupReasons_700565" 529 "WakeupReasons_702402" 528 "WakeupReasons_702439" 527 "WakeupReasons_702448" 526 "WakeupReasons_701872" 525 "WakeupReasons_699114" 524 "WakeupReasons_702240" 523 "WakeupReasons_701270" 522 "WakeupReasons_533751" 521 "WakeupReasons_698581" 520 "WakeupReasons_698130" 519 "WakeupReasons_700130" 518 "WakeupReasons_699921" 517 "WakeupReasons_699919" 516 "WakeupReasons_700486" 515 "WakeupReasons_700782" 514 "WakeupReasons_696971" 513 "WakeupReasons_700692" 512 "WakeupReasons_698385" 511 "WakeupReasons_699922" 510 "WakeupReasons_697967" 509 "WakeupReasons_700684" 508 "WakeupReasons_644379" 507 "WakeupReasons_336435" 506 "WakeupReasons_683263" 505 "WakeupReasons_700554" 504 "WakeupReasons_691992" 503 "WakeupReasons_698129" 502 "WakeupReasons_696850" 501 "WakeupReasons_702088" 500 "WakeupReasons_696612" 499 "WakeupReasons_691994" 498 "WakeupReasons_700483" 497 "WakeupReasons_702204" 496 "WakeupReasons_700603" 495 "WakeupReasons_700215" 494 "WakeupReasons_701509" 493 "WakeupReasons_701508" 492 "WakeupReasons_700484" 491 "WakeupReasons_217907" 490 "WakeupReasons_194966" 489 "WakeupReasons_702174" 488 "WakeupReasons_697145" 487 "WakeupReasons_296931" 486 "WakeupReasons_700687" 485 "WakeupReasons_700686" 484 "WakeupReasons_698409" 483 "WakeupReasons_533750" 482 "WakeupReasons_700467" 481 "WakeupReasons_687404" 480 "WakeupReasons_681813" 479 "WakeupReasons_698288" 478 "WakeupReasons_698660" 477 "WakeupReasons_691993" 476 "WakeupReasons_700485" 475 "WakeupReasons_700425" 474 "WakeupReasons_702197" 473 "WakeupReasons_637992" 472 "WakeupReasons_698488" 471 "WakeupReasons_691991" 470 "WakeupReasons_692547" 469 "WakeupReasons_693914" 468 "WakeupReasons_693024" 467 "WakeupReasons_693005" 466 "WakeupReasons_667949" 465 "WakeupReasons_686281" 464 "WakeupReasons_680764" 463 "WakeupReasons_512384" 462 "WakeupReasons_692019" 461 "WakeupReasons_533850" 460 "WakeupReasons_533849" 459 "WakeupReasons_667188" 458 "WakeupReasons_514652" 457 "WakeupReasons_514651" 456 "WakeupReasons_112024" 455 "WakeupReasons_300690" 454 "WakeupReasons_299532" 453 "WakeupReasons_299531" 452 "WakeupReasons_299120" 451 "WakeupReasons_273516" 450 "WakeupReasons_265694" 449 "WakeupReasons_692439" 448 "WakeupReasons_354831" 447 "WakeupReasons_680765" 446 "WakeupReasons_45895" 445 "WakeupReasons_644275" 444 "WakeupReasons_351189" 443 "WakeupReasons_226570" 442 "WakeupReasons_654489" 441 "WakeupReasons_110181" 440 "WakeupReasons_226569" 439 "WakeupReasons_45896" 438 "WakeupReasons_112031" 437 "WakeupReasons_110173" 436 "WakeupReasons_677781" 435 "WakeupReasons_690939" 434 "WakeupReasons_354809" 433 "WakeupReasons_692022" 432 "WakeupReasons_690593" 431 "WakeupReasons_226571" 430 "WakeupReasons_675594" 429 "WakeupReasons_226565" 428 "WakeupReasons_692020" 427 "WakeupReasons_112035" 426 "WakeupReasons_112027" 425 "WakeupReasons_354672" 424 "WakeupReasons_168967" 423 "WakeupReasons_354674" 422 "WakeupReasons_168968" 421 "WakeupReasons_641483" 420 "WakeupReasons_641482" 419 "WakeupReasons_265698" 418 "WakeupReasons_265699" 417 "WakeupReasons_360491" 416 "WakeupReasons_357498" 415 "WakeupReasons_170290" 414 "WakeupReasons_690385" 413 "WakeupReasons_692021" 412 "WakeupReasons_91254" 411 "WakeupReasons_346654" 410 "WakeupReasons_200637" 409 "WakeupReasons_170285" 408 "WakeupReasons_265678" 407 "WakeupReasons_683934" 406 "WakeupReasons_680763" 405 "WakeupReasons_682074" 404 "WakeupReasons_682154" 403 "WakeupReasons_682152" 402 "WakeupReasons_682155" 401 "WakeupReasons_682153" 400 "WakeupReasons_682078" 399 "WakeupReasons_682076" 398 "WakeupReasons_682077" 397 "WakeupReasons_676285" 396 "WakeupReasons_681023" 395 "WakeupReasons_682023" 394 "WakeupReasons_681789" 393 "WakeupReasons_682688" 392 "WakeupReasons_682037" 391 "WakeupReasons_682032" 390 "WakeupReasons_681915" 389 "WakeupReasons_674839" 388 "WakeupReasons_682034" 387 "WakeupReasons_681711" 386 "WakeupReasons_681031" 385 "WakeupReasons_681134" 384 "WakeupReasons_670462" 383 "WakeupReasons_681028" 382 "WakeupReasons_680975" 381 "WakeupReasons_680974" 380 "WakeupReasons_668523" 379 "WakeupReasons_669822" 378 "WakeupReasons_680712" 377 "WakeupReasons_671005" 376 "WakeupReasons_177214" 375 "WakeupReasons_45655" 374 "WakeupReasons_667872" 373 "WakeupReasons_264964" 372 "WakeupReasons_262871" 371 "WakeupReasons_264691" 370 "WakeupReasons_297056" 369 "WakeupReasons_233755" 368 "WakeupReasons_145161" 367 "WakeupReasons_667842" 366 "WakeupReasons_46020" 365 "WakeupReasons_667874" 364 "WakeupReasons_667981" 363 "WakeupReasons_224211" 362 "WakeupReasons_45902" 361 "WakeupReasons_329457" 360 "WakeupReasons_88458" 359 "WakeupReasons_45900" 358 "WakeupReasons_83199" 357 "WakeupReasons_532933" 356 "WakeupReasons_532932" 355 "WakeupReasons_670942" 354 "WakeupReasons_305818" 353 "WakeupReasons_75103" 352 "WakeupReasons_667987" 351 "WakeupReasons_667983" 350 "WakeupReasons_675745" 349 "WakeupReasons_356598" 348 "WakeupReasons_128671" 347 "WakeupReasons_69216" 346 "WakeupReasons_264697" 345 "WakeupReasons_264943" 344 "WakeupReasons_197644" 343 "WakeupReasons_675564" 342 "WakeupReasons_657120" 341 "WakeupReasons_265745" 340 "WakeupReasons_657121" 339 "WakeupReasons_667982" 338 "WakeupReasons_674223" 337 "WakeupReasons_127926" 336 "WakeupReasons_127924" 335 "WakeupReasons_262872" 334 "WakeupReasons_45848" 333 "WakeupReasons_45847" 332 "WakeupReasons_45846" 331 "WakeupReasons_667869" 330 "WakeupReasons_45890" 329 "WakeupReasons_45888" 328 "WakeupReasons_670962" 327 "WakeupReasons_667973" 326 "WakeupReasons_45877" 325 "WakeupReasons_667980" 324 "WakeupReasons_45876" 323 "WakeupReasons_45871" 322 "WakeupReasons_45875" 321 "WakeupReasons_45872" 320 "WakeupReasons_45870" 319 "WakeupReasons_45869" 318 "WakeupReasons_80608" 317 "WakeupReasons_45898" 316 "WakeupReasons_45897" 315 "WakeupReasons_69679" 314 "WakeupReasons_69678" 313 "WakeupReasons_45887" 312 "WakeupReasons_263473" 311 "WakeupReasons_265131" 310 "WakeupReasons_268983" 309 "WakeupReasons_139075" 308 "WakeupReasons_200090" 307 "WakeupReasons_199714" 306 "WakeupReasons_80609" 305 "WakeupReasons_106669" 304 "WakeupReasons_675742" 303 "WakeupReasons_46017" 302 "WakeupReasons_670354" 301 "WakeupReasons_667985" 300 "WakeupReasons_670966" 299 "WakeupReasons_667871" 298 "WakeupReasons_193474" 297 "WakeupReasons_113348" 296 "WakeupReasons_532556" 295 "WakeupReasons_532555" 294 "WakeupReasons_667988" 293 "WakeupReasons_182918" 292 "WakeupReasons_311279" 291 "WakeupReasons_667848" 290 "WakeupReasons_667850" 289 "WakeupReasons_668393" 288 "WakeupReasons_668395" 287 "WakeupReasons_670753" 286 "WakeupReasons_667922" 285 "WakeupReasons_669447" 284 "WakeupReasons_670928" 283 "WakeupReasons_669465" 282 "WakeupReasons_676265" 281 "WakeupReasons_667947" 280 "WakeupReasons_667879" 279 "WakeupReasons_675837" 278 "WakeupReasons_675494" 277 "WakeupReasons_674958" 276 "WakeupReasons_675064" 275 "WakeupReasons_674953" 274 "WakeupReasons_658188" 273 "WakeupReasons_337991" 272 "WakeupReasons_197653" 271 "WakeupReasons_269140" 270 "WakeupReasons_312881" 269 "WakeupReasons_215560" 268 "WakeupReasons_269034" 267 "WakeupReasons_4471" 266 "WakeupReasons_185490" 265 "WakeupReasons_185457" 264 "WakeupReasons_198452" 263 "WakeupReasons_200683" 262 "WakeupReasons_358832" 261 "WakeupReasons_NMPDUReceived" 260 "WakeupReasons_670345" 259 "WakeupReasons_109467" 258 "WakeupReasons_109466" 257 "WakeupReasons_636801" 256 "WakeupReasons_45849" 255 "WakeupReasons_45850" 254 "WakeupReasons_45851" 253 "WakeupReasons_45852" 252 "WakeupReasons_45854" 251 "WakeupReasons_45853" 250 "WakeupReasons_45856" 249 "WakeupReasons_533872" 248 "WakeupReasons_516327" 247 "WakeupReasons_359559" 246 "WakeupReasons_241902" 245 "WakeupReasons_533372" 244 "WakeupReasons_533371" 243 "WakeupReasons_533370" 242 "WakeupReasons_315981" 241 "WakeupReasons_45858" 240 "WakeupReasons_668529" 239 "WakeupReasons_670087" 238 "WakeupReasons_668531" 237 "WakeupReasons_223920" 236 "WakeupReasons_176748" 235 "WakeupReasons_146470" 234 "WakeupReasons_112799" 233 "WakeupReasons_95949" 232 "WakeupReasons_156440" 231 "WakeupReasons_166267" 230 "WakeupReasons_101727" 229 "WakeupReasons_101728" 228 "WakeupReasons_101725" 227 "WakeupReasons_101706" 226 "WakeupReasons_659350" 225 "WakeupReasons_667820" 224 "WakeupReasons_331194" 223 "WakeupReasons_652546" 222 "WakeupReasons_224553" 221 "WakeupReasons_224552" 220 "WakeupReasons_110885" 219 "WakeupReasons_667953" 218 "WakeupReasons_667962" 217 "WakeupReasons_224550" 216 "WakeupReasons_197665" 215 "WakeupReasons_225961" 214 "WakeupReasons_198433" 213 "WakeupReasons_526438" 212 "WakeupReasons_316796" 211 "WakeupReasons_335068" 210 "WakeupReasons_535214" 209 "WakeupReasons_264726" 208 "WakeupReasons_360542" 207 "WakeupReasons_531743" 206 "WakeupReasons_226967" 205 "WakeupReasons_318382" 204 "WakeupReasons_199159" 203 "WakeupReasons_223715" 202 "WakeupReasons_643973" 201 "WakeupReasons_319401" 200 "WakeupReasons_264712" 199 "WakeupReasons_526426" 198 "WakeupReasons_533050" 197 "WakeupReasons_265937" 196 "WakeupReasons_108834" 195 "WakeupReasons_636556" 194 "WakeupReasons_655340" 193 "WakeupReasons_320895" 192 "WakeupReasons_321077" 191 "WakeupReasons_321323" 190 "WakeupReasons_321319" 189 "WakeupReasons_321057" 188 "WakeupReasons_359187" 187 "WakeupReasons_321317" 186 "WakeupReasons_355214" 185 "WakeupReasons_652361" 184 "WakeupReasons_192030" 183 "WakeupReasons_534145" 182 "WakeupReasons_526445" 181 "WakeupReasons_360299" 180 "WakeupReasons_525705" 179 "WakeupReasons_534077" 178 "WakeupReasons_359211" 177 "WakeupReasons_300681" 176 "WakeupReasons_198484" 175 "WakeupReasons_356549" 174 "WakeupReasons_360543" 173 "WakeupReasons_318342" 172 "WakeupReasons_299547" 171 "WakeupReasons_646109" 170 "WakeupReasons_645753" 169 "WakeupReasons_514502" 168 "WakeupReasons_515804" 167 "WakeupReasons_298808" 166 "WakeupReasons_265330" 165 "WakeupReasons_265328" 164 "WakeupReasons_265305" 163 "WakeupReasons_361279" 162 "WakeupReasons_361272" 161 "WakeupReasons_160596" 160 "WakeupReasons_197648" 159 "WakeupReasons_658603" 158 "WakeupReasons_322857" 157 "WakeupReasons_108810" 156 "WakeupReasons_179103" 155 "WakeupReasons_321845" 154 "WakeupReasons_340667" 153 "WakeupReasons_299117" 152 "WakeupReasons_514503" 151 "WakeupReasons_532007" 150 "WakeupReasons_337565" 149 "WakeupReasons_320631" 148 "WakeupReasons_354791" 147 "WakeupReasons_317616" 146 "WakeupReasons_644550" 145 "WakeupReasons_265232" 144 "WakeupReasons_514545" 143 "WakeupReasons_526429" 142 "WakeupReasons_265569" 141 "WakeupReasons_108841" 140 "WakeupReasons_160602" 139 "WakeupReasons_160597" 138 "WakeupReasons_264958" 137 "WakeupReasons_300682" 136 "WakeupReasons_224634" 135 "WakeupReasons_224617" 134 "WakeupReasons_220322" 133 "WakeupReasons_300427" 132 "WakeupReasons_269156" 131 "WakeupReasons_145462" 130 "WakeupReasons_145454" 129 "WakeupReasons_145419" 128 "WakeupReasons_145288" 127 "WakeupReasons_145373" 126 "WakeupReasons_145385" 125 "WakeupReasons_145362" 124 "WakeupReasons_145399" 123 "WakeupReasons_145388" 122 "WakeupReasons_145330" 121 "WakeupReasons_152774" 120 "WakeupReasons_145319" 119 "WakeupReasons_145311" 118 "WakeupReasons_106774" 117 "WakeupReasons_533044" 116 "WakeupReasons_636692" 115 "WakeupReasons_355409" 114 "WakeupReasons_133749" 113 "WakeupReasons_156412" 112 "WakeupReasons_320287" 111 "WakeupReasons_201348" 110 "WakeupReasons_264962" 109 "WakeupReasons_169884" 108 "WakeupReasons_45867" 107 "WakeupReasons_45866" 106 "WakeupReasons_659549" 105 "WakeupReasons_45864" 104 "WakeupReasons_201815" 103 "WakeupReasons_224831" 102 "WakeupReasons_222553" 101 "WakeupReasons_140678" 100 "WakeupReasons_169945" 99 "WakeupReasons_95444" 98 "WakeupReasons_145688" 97 "WakeupReasons_356190" 96 "WakeupReasons_264934" 95 "WakeupReasons_264932" 94 "WakeupReasons_152786" 93 "WakeupReasons_144970" 92 "WakeupReasons_186489" 91 "WakeupReasons_144897" 90 "WakeupReasons_199172" 89 "WakeupReasons_145707" 88 "WakeupReasons_152237" 87 "WakeupReasons_67182" 86 "WakeupReasons_338820" 85 "WakeupReasons_634710" 84 "WakeupReasons_109387" 83 "WakeupReasons_320126" 82 "WakeupReasons_109367" 81 "WakeupReasons_315364" 80 "WakeupReasons_297868" 79 "WakeupReasons_645810" 78 "WakeupReasons_634696" 77 "WakeupReasons_138997" 76 "WakeupReasons_360006" 75 "WakeupReasons_224061" 74 "WakeupReasons_68481" 73 "WakeupReasons_109364" 72 "WakeupReasons_68644" 71 "WakeupReasons_224065" 70 "WakeupReasons_119273" 69 "WakeupReasons_109382" 68 "WakeupReasons_360008" 67 "WakeupReasons_68676" 66 "WakeupReasons_645094" 65 "WakeupReasons_361509" 64 "WakeupReasons_361505" 63 "WakeupReasons_360904" 62 "WakeupReasons_355601" 61 "WakeupReasons_320277" 60 "WakeupReasons_319422" 59 "WakeupReasons_320282" 58 "WakeupReasons_169894" 57 "WakeupReasons_266860" 56 "WakeupReasons_45656" 55 "WakeupReasons_21997" 54 "WakeupReasons_225696" 53 "WakeupReasons_200156" 52 "WakeupReasons_161066" 51 "WakeupReasons_185670" 50 "WakeupReasons_197826" 49 "WakeupReasons_176921" 48 "WakeupReasons_108776" 47 "WakeupReasons_265333" 46 "WakeupReasons_100281" 45 "WakeupReasons_100278" 44 "WakeupReasons_100300" 43 "WakeupReasons_100275" 42 "WakeupReasons_100298" 41 "WakeupReasons_319139" 40 "WakeupReasons_170807" 39 "WakeupReasons_200937" 38 "WakeupReasons_182033" 37 "WakeupReasons_191050" 36 "WakeupReasons_264876" 35 "WakeupReasons_197642" 34 "WakeupReasons_170865" 33 "WakeupReasons_168966" 32 "WakeupReasons_667948" 31 "WakeupReasons_169655" 30 "WakeupReasons_667945" 29 "WakeupReasons_74188" 28 "WakeupReasons_321583" 27 "WakeupReasons_88125" 26 "WakeupReasons_88123" 25 "WakeupReasons_91253" 24 "WakeupReasons_21973" 23 "WakeupReasons_140084" 22 "WakeupReasons_45657" 21 "WakeupReasons_45659" 20 "WakeupReasons_22100" 19 "WakeupReasons_22013" 18 "WakeupReasons_22005" 17 "WakeupReasons_45794" 16 "WakeupReasons_45793" 15 "WakeupReasons_21901" 14 "WakeupReasons_658500" 13 "WakeupReasons_269739" 12 "WakeupReasons_269735" 11 "WakeupReasons_269740" 10 "WakeupReasons_22060" 9 "WakeupReasons_49446" 8 "WakeupReasons_22058" 7 "WakeupReasons_45654" 6 "WakeupReasons_264933" 5 "WakeupReasons_197643" 4 "WakeupReasons_168965" 3 "WakeupReasons_667951" 2 "WakeupReasons_169654" 1 "WakeupReasons_667950" 0 "WakeupReasons_0" ;
VAL_ 1371 VFCVectorSRSVFCid0 1 "VFCOnOff_On" 0 "VFCOnOff_Off" ;
VAL_ 1371 VFCVectorSRSVFCid1 1 "VFCOnOff_On" 0 "VFCOnOff_Off" ;
VAL_ 1371 VFCVectorSRSVFCid10 1 "VFCOnOff_On" 0 "VFCOnOff_Off" ;
VAL_ 1371 VFCVectorSRSVFCid11 1 "VFCOnOff_On" 0 "VFCOnOff_Off" ;
VAL_ 1371 VFCVectorSRSVFCid12 1 "VFCOnOff_On" 0 "VFCOnOff_Off" ;
VAL_ 1371 VFCVectorSRSVFCid13 1 "VFCOnOff_On" 0 "VFCOnOff_Off" ;
VAL_ 1371 VFCVectorSRSVFCid14 1 "VFCOnOff_On" 0 "VFCOnOff_Off" ;
VAL_ 1371 VFCVectorSRSVFCid15 1 "VFCOnOff_On" 0 "VFCOnOff_Off" ;
VAL_ 1371 VFCVectorSRSVFCid16 1 "VFCOnOff_On" 0 "VFCOnOff_Off" ;
VAL_ 1371 VFCVectorSRSVFCid17 1 "VFCOnOff_On" 0 "VFCOnOff_Off" ;
VAL_ 1371 VFCVectorSRSVFCid18 1 "VFCOnOff_On" 0 "VFCOnOff_Off" ;
VAL_ 1371 VFCVectorSRSVFCid19 1 "VFCOnOff_On" 0 "VFCOnOff_Off" ;
VAL_ 1371 VFCVectorSRSVFCid2 1 "VFCOnOff_On" 0 "VFCOnOff_Off" ;
VAL_ 1371 VFCVectorSRSVFCid20 1 "VFCOnOff_On" 0 "VFCOnOff_Off" ;
VAL_ 1371 VFCVectorSRSVFCid21 1 "VFCOnOff_On" 0 "VFCOnOff_Off" ;
VAL_ 1371 VFCVectorSRSVFCid22 1 "VFCOnOff_On" 0 "VFCOnOff_Off" ;
VAL_ 1371 VFCVectorSRSVFCid23 1 "VFCOnOff_On" 0 "VFCOnOff_Off" ;
VAL_ 1371 VFCVectorSRSVFCid24 1 "VFCOnOff_On" 0 "VFCOnOff_Off" ;
VAL_ 1371 VFCVectorSRSVFCid25 1 "VFCOnOff_On" 0 "VFCOnOff_Off" ;
VAL_ 1371 VFCVectorSRSVFCid26 1 "VFCOnOff_On" 0 "VFCOnOff_Off" ;
VAL_ 1371 VFCVectorSRSVFCid27 1 "VFCOnOff_On" 0 "VFCOnOff_Off" ;
VAL_ 1371 VFCVectorSRSVFCid28 1 "VFCOnOff_On" 0 "VFCOnOff_Off" ;
VAL_ 1371 VFCVectorSRSVFCid29 1 "VFCOnOff_On" 0 "VFCOnOff_Off" ;
VAL_ 1371 VFCVectorSRSVFCid3 1 "VFCOnOff_On" 0 "VFCOnOff_Off" ;
VAL_ 1371 VFCVectorSRSVFCid30 1 "VFCOnOff_On" 0 "VFCOnOff_Off" ;
VAL_ 1371 VFCVectorSRSVFCid31 1 "VFCOnOff_On" 0 "VFCOnOff_Off" ;
VAL_ 1371 VFCVectorSRSVFCid32 1 "VFCOnOff_On" 0 "VFCOnOff_Off" ;
VAL_ 1371 VFCVectorSRSVFCid33 1 "VFCOnOff_On" 0 "VFCOnOff_Off" ;
VAL_ 1371 VFCVectorSRSVFCid34 1 "VFCOnOff_On" 0 "VFCOnOff_Off" ;
VAL_ 1371 VFCVectorSRSVFCid35 1 "VFCOnOff_On" 0 "VFCOnOff_Off" ;
VAL_ 1371 VFCVectorSRSVFCid36 1 "VFCOnOff_On" 0 "VFCOnOff_Off" ;
VAL_ 1371 VFCVectorSRSVFCid37 1 "VFCOnOff_On" 0 "VFCOnOff_Off" ;
VAL_ 1371 VFCVectorSRSVFCid38 1 "VFCOnOff_On" 0 "VFCOnOff_Off" ;
VAL_ 1371 VFCVectorSRSVFCid39 1 "VFCOnOff_On" 0 "VFCOnOff_Off" ;
VAL_ 1371 VFCVectorSRSVFCid4 1 "VFCOnOff_On" 0 "VFCOnOff_Off" ;
VAL_ 1371 VFCVectorSRSVFCid40 1 "VFCOnOff_On" 0 "VFCOnOff_Off" ;
VAL_ 1371 VFCVectorSRSVFCid41 1 "VFCOnOff_On" 0 "VFCOnOff_Off" ;
VAL_ 1371 VFCVectorSRSVFCid42 1 "VFCOnOff_On" 0 "VFCOnOff_Off" ;
VAL_ 1371 VFCVectorSRSVFCid43 1 "VFCOnOff_On" 0 "VFCOnOff_Off" ;
VAL_ 1371 VFCVectorSRSVFCid44 1 "VFCOnOff_On" 0 "VFCOnOff_Off" ;
VAL_ 1371 VFCVectorSRSVFCid45 1 "VFCOnOff_On" 0 "VFCOnOff_Off" ;
VAL_ 1371 VFCVectorSRSVFCid46 1 "VFCOnOff_On" 0 "VFCOnOff_Off" ;
VAL_ 1371 VFCVectorSRSVFCid47 1 "VFCOnOff_On" 0 "VFCOnOff_Off" ;
VAL_ 1371 VFCVectorSRSVFCid48 1 "VFCOnOff_On" 0 "VFCOnOff_Off" ;
VAL_ 1371 VFCVectorSRSVFCid49 1 "VFCOnOff_On" 0 "VFCOnOff_Off" ;
VAL_ 1371 VFCVectorSRSVFCid5 1 "VFCOnOff_On" 0 "VFCOnOff_Off" ;
VAL_ 1371 VFCVectorSRSVFCid50 1 "VFCOnOff_On" 0 "VFCOnOff_Off" ;
VAL_ 1371 VFCVectorSRSVFCid51 1 "VFCOnOff_On" 0 "VFCOnOff_Off" ;
VAL_ 1371 VFCVectorSRSVFCid52 1 "VFCOnOff_On" 0 "VFCOnOff_Off" ;
VAL_ 1371 VFCVectorSRSVFCid53 1 "VFCOnOff_On" 0 "VFCOnOff_Off" ;
VAL_ 1371 VFCVectorSRSVFCid54 1 "VFCOnOff_On" 0 "VFCOnOff_Off" ;
VAL_ 1371 VFCVectorSRSVFCid55 1 "VFCOnOff_On" 0 "VFCOnOff_Off" ;
VAL_ 1371 VFCVectorSRSVFCid56 1 "VFCOnOff_On" 0 "VFCOnOff_Off" ;
VAL_ 1371 VFCVectorSRSVFCid57 1 "VFCOnOff_On" 0 "VFCOnOff_Off" ;
VAL_ 1371 VFCVectorSRSVFCid58 1 "VFCOnOff_On" 0 "VFCOnOff_Off" ;
VAL_ 1371 VFCVectorSRSVFCid59 1 "VFCOnOff_On" 0 "VFCOnOff_Off" ;
VAL_ 1371 VFCVectorSRSVFCid6 1 "VFCOnOff_On" 0 "VFCOnOff_Off" ;
VAL_ 1371 VFCVectorSRSVFCid60 1 "VFCOnOff_On" 0 "VFCOnOff_Off" ;
VAL_ 1371 VFCVectorSRSVFCid61 1 "VFCOnOff_On" 0 "VFCOnOff_Off" ;
VAL_ 1371 VFCVectorSRSVFCid7 1 "VFCOnOff_On" 0 "VFCOnOff_Off" ;
VAL_ 1371 VFCVectorSRSVFCid8 1 "VFCOnOff_On" 0 "VFCOnOff_Off" ;
VAL_ 1371 VFCVectorSRSVFCid9 1 "VFCOnOff_On" 0 "VFCOnOff_Off" ;
VAL_ 208 TrlrFogLiSts 1 "OnOff1_On" 0 "OnOff1_Off" ;
VAL_ 208 TrlrLampActvtChk 1 "TrlrLampChkSts1_TrlrLampChkAvl" 0 "TrlrLampChkSts1_TrlrLampChkNotAvl" ;
VAL_ 208 TrlrLampChkSts 7 "TrlrLampChkSts2_Resd3" 6 "TrlrLampChkSts2_Resd2" 5 "TrlrLampChkSts2_Resd1" 4 "TrlrLampChkSts2_TrlrLampEngOffReqd" 3 "TrlrLampChkSts2_CnclOper" 2 "TrlrLampChkSts2_TrlrLampChkCmpl" 1 "TrlrLampChkSts2_TrlrLampChkStrtd" 0 "TrlrLampChkSts2_Idle" ;
VAL_ 208 TrlrLeIndcrFltSts 1 "DevErrSts2_Flt" 0 "DevErrSts2_NoFlt" ;
VAL_ 208 TrlrLiFltSts 7 "LampFailrSts1_BrkAndIndcrTurnAllFailr" 6 "LampFailrSts1_BrkLampAndIndcrTurnLeFailr" 5 "LampFailrSts1_BrkLampAndIndcrTurnRiFailr" 4 "LampFailrSts1_BrkLampFailr" 3 "LampFailrSts1_LampIndcrTurnLeAndRiFailr" 2 "LampFailrSts1_LampIndcrTurnLeFailr" 1 "LampFailrSts1_LampIndcrTurnRiFailr" 0 "LampFailrSts1_LampNoFailr" ;
VAL_ 208 TrlrPrmntPwrActv 1 "YesNo1_No" 0 "YesNo1_Yes" ;
VAL_ 208 TrlrPrsnt 1 "TrlrPrsntSts_TrlrPrsnt" 0 "TrlrPrsntSts_TrlrNotPrsnt" ;
VAL_ 208 TrlrRiIndcrFltSts 1 "DevErrSts2_Flt" 0 "DevErrSts2_NoFlt" ;
VAL_ 208 TrlrSrvReq 1 "DevErrSts2_Flt" 0 "DevErrSts2_NoFlt" ;
VAL_ 145 TrlrBrkLiSts 1 "OnOff1_On" 0 "OnOff1_Off" ;
VAL_ 145 TrlrIndcrTurnSts 3 "IndcrSts1_LeAndRiOn" 2 "IndcrSts1_RiOn" 1 "IndcrSts1_LeOn" 0 "IndcrSts1_Off" ;
VAL_ 145 TrlrPosnLiSts 1 "OnOff1_On" 0 "OnOff1_Off" ;
VAL_ 145 TrlrRvsgLiSts 1 "OnOff1_On" 0 "OnOff1_Off" ;
VAL_ 145 TwbrLockdPosn 3 "TwbrLockdPosn_Reserved" 2 "TwbrLockdPosn_Lockd" 1 "TwbrLockdPosn_Unlckd" 0 "TwbrLockdPosn_Ukwn" ;
VAL_ 145 TwbrWarnStsYesNo 3 "YesNoRes_Resd2" 2 "YesNoRes_No" 1 "YesNoRes_Yes" 0 "YesNoRes_Resd1" ;
VAL_ 345 FullElecTwbrPosn 7 "FullElecTwbrPosn_reserved3" 6 "FullElecTwbrPosn_reserved2" 5 "FullElecTwbrPosn_reserved1" 4 "FullElecTwbrPosn_MovingIn" 3 "FullElecTwbrPosn_MovingOut" 2 "FullElecTwbrPosn_Outfolded" 1 "FullElecTwbrPosn_Infolded" 0 "FullElecTwbrPosn_Unknow" ;
VAL_ 345 SemiElecTwbrPosn 7 "FullElecTwbrPosn_reserved3" 6 "FullElecTwbrPosn_reserved2" 5 "FullElecTwbrPosn_reserved1" 4 "FullElecTwbrPosn_MovingIn" 3 "FullElecTwbrPosn_MovingOut" 2 "FullElecTwbrPosn_Outfolded" 1 "FullElecTwbrPosn_Infolded" 0 "FullElecTwbrPosn_Unknow" ;
VAL_ 345 TwbrRelsBtn 1 "PsdNotPsd1_Psd" 0 "PsdNotPsd1_NotPsd" ;
SIG_GROUP_ 962 SRSdevelpsignalgroupRX 1 : SRSdevelpsignalgroupRXFunct_0004 SRSdevelpsignalgroupRXFunct_0002 SRSdevelpsignalgroupRXFunct_0005 SRSdevelpsignalgroupRXFunct_0001 SRSdevelpsignalgroupRXFunct_0000 SRSdevelpsignalgroupRXFunct_0006 SRSdevelpsignalgroupRXFunct_0003 SRSdevelpsignalgroupRXFunctionde;
SIG_GROUP_ 1346 VFCVectorOGM 1 : VFCVectorOGMVFCid55 VFCVectorOGMVFCid18 VFCVectorOGMVFCid45 VFCVectorOGMVFCid22 VFCVectorOGMVFCid51 VFCVectorOGMVFCid1 VFCVectorOGMVFCid31 VFCVectorOGMVFCid57 VFCVectorOGMVFCid27 VFCVectorOGMVFCid24 VFCVectorOGMVFCid26 VFCVectorOGMVFCid40 VFCVectorOGMVFCid50 VFCVectorOGMVFCid16 VFCVectorOGMVFCid34 VFCVectorOGMVFCid10 VFCVectorOGMVFCid12 VFCVectorOGMVFCid19 VFCVectorOGMVFCid28 VFCVectorOGMVFCid17 VFCVectorOGMVFCid21 VFCVectorOGMVFCid59 VFCVectorOGMVFCid5 VFCVectorOGMVFCid36 VFCVectorOGMVFCid33 VFCVectorOGMVFCid32 VFCVectorOGMVFCid54 VFCVectorOGMVFCid29 VFCVectorOGMVFCid20 VFCVectorOGMVFCid37 VFCVectorOGMVFCid46 VFCVectorOGMVFCid30 VFCVectorOGMVFCid47 VFCVectorOGMVFCid58 VFCVectorOGMVFCid9 VFCVectorOGMVFCid48 VFCVectorOGMVFCid44 VFCVectorOGMVFCid2 VFCVectorOGMVFCid35 VFCVectorOGMVFCid60 VFCVectorOGMVFCid25 VFCVectorOGMVFCid41 VFCVectorOGMVFCid13 VFCVectorOGMVFCid56 VFCVectorOGMVFCid43 VFCVectorOGMVFCid42 VFCVectorOGMVFCid38 VFCVectorOGMVFCid23 VFCVectorOGMVFCid52 VFCVectorOGMVFCid49 VFCVectorOGMVFCid4 VFCVectorOGMVFCid3 VFCVectorOGMVFCid8 VFCVectorOGMVFCid0 VFCVectorOGMVFCid15 VFCVectorOGMVFCid53 VFCVectorOGMVFCid14 VFCVectorOGMBlockID VFCVectorOGMVFCid6 VFCVectorOGMVFCid61 VFCVectorOGMVFCid39 VFCVectorOGMVFCid11 VFCVectorOGMVFCid7;
SIG_GROUP_ 961 SRSdevelpsignalgroupTX 1 : SRSdevelpsignalgroupTXFunct_0001 SRSdevelpsignalgroupTXFunct_0004 SRSdevelpsignalgroupTXFunct_0005 SRSdevelpsignalgroupTXFunct_0000 SRSdevelpsignalgroupTXFunct_0006 SRSdevelpsignalgroupTXFunct_0002 SRSdevelpsignalgroupTXFunctionde SRSdevelpsignalgroupTXFunct_0003;
SIG_GROUP_ 137 BltLockStAtDrvr 1 : BltLockStAtDrvrBltLockSts BltLockStAtDrvrBltLockSt1;
SIG_GROUP_ 137 AgDataRawSafe 1 : AgDataRawSafeRollRate AgDataRawSafeYawRateQf AgDataRawSafeCntr AgDataRawSafeChks AgDataRawSafeRollRateQf AgDataRawSafeYawRate;
SIG_GROUP_ 137 BltLockStAtPass 1 : BltLockStAtPassBltLockSts BltLockStAtPassBltLockSt1;
SIG_GROUP_ 16 CrashStsSafe 1 : CrashStsSafeCntr CrashStsSafeSts CrashStsSafeChks;
SIG_GROUP_ 18 ADataRawSafe 1 : ADataRawSafeALat1Qf ADataRawSafeAVert ADataRawSafeALat ADataRawSafeCntr ADataRawSafeALgt1Qf ADataRawSafeAVertQf ADataRawSafeALgt ADataRawSafeChks;
SIG_GROUP_ 19 AsyDataWithCmpSafe 1 : AsyDataWithCmpSafeCntr AsyDataWithCmpSafeChks AsyDataWithCmpSafeYawRateQf AsyDataWithCmpSafeALgt1Qf AsyDataWithCmpSafeALatWithCmp AsyDataWithCmpSafeALat1Qf AsyDataWithCmpSafeGrdtOfALgt AsyDataWithCmpSafeYawRateWithCmp;
SIG_GROUP_ 33 BltLockStSafeAtDrvr 1 : BltLockStSafeAtDrvrChks BltLockStSafeAtDrvrBltLockStErrS BltLockStSafeAtDrvrBltLockSt1 BltLockStSafeAtDrvrCntr;
SIG_GROUP_ 549 BltLockStAtRowFrthMid 1 : BltLockStAtRowFrthMidBltLockSts BltLockStAtRowFrthMidBltLockEqui BltLockStAtRowFrthMidBltLockSt1;
SIG_GROUP_ 549 BltLockStAtRowThrdMid 1 : BltLockStAtRowThrdMidBltLockEqui BltLockStAtRowThrdMidBltLockSt1 BltLockStAtRowThrdMidBltLockSts;
SIG_GROUP_ 549 BltLockStAtRowFrthRi 1 : BltLockStAtRowFrthRiBltLockSts BltLockStAtRowFrthRiBltLockSt1 BltLockStAtRowFrthRiBltLockEquid;
SIG_GROUP_ 549 BltLockStAtPassMid 1 : BltLockStAtPassMidBltLockSt1 BltLockStAtPassMidBltLockEquid BltLockStAtPassMidBltLockSts;
SIG_GROUP_ 549 BltLockStAtRowFrthLe 1 : BltLockStAtRowFrthLeBltLockSt1 BltLockStAtRowFrthLeBltLockSts BltLockStAtRowFrthLeBltLockEquid;
SIG_GROUP_ 322 PassAirbLampReq 1 : PassAirbLampReqPassAirbLampDiReq PassAirbLampReqChgOfPassAirbSts PassAirbLampReqChks PassAirbLampReqPassAirbLampEnaRe PassAirbLampReqCntr;
SIG_GROUP_ 322 AgDataRaw2Safe 1 : AgDataRaw2SafePitchRate AgDataRaw2SafeCntr AgDataRaw2SafePitchRateQf AgDataRaw2SafeChks;
SIG_GROUP_ 554 JID 1 : JIDByte6 JIDByte1 JIDByte5 JIDByte4 JIDByte7 JIDByte3 JIDByte2 JIDByte0;
SIG_GROUP_ 864 BltCrashNotif 1 : BltCrashNotifDrvr BltCrashNotifPass;
SIG_GROUP_ 864 RecOfImpct 1 : RecOfImpctCrashFrnt RecOfImpctCrashOffroadD RecOfImpctImpctRollAg RecOfImpctVehOri RecOfImpctCrashRollovr RecOfImpctCrashOffroadA RecOfImpctCrashState RecOfImpctCrashRe RecOfImpctCrashOffroadRT RecOfImpctImpctDvx RecOfImpctCrashOffroadRTsevere RecOfImpctCrashSideLe RecOfImpctCrashSideRi RecOfImpctImpctDvy RecOfImpctCrashPed;
SIG_GROUP_ 112 BltLockStAtRowThrdRi 1 : BltLockStAtRowThrdRiBltLockSt1 BltLockStAtRowThrdRiBltLockSts BltLockStAtRowThrdRiBltLockEquid;
SIG_GROUP_ 112 BltLockStAtRowSecRi 1 : BltLockStAtRowSecRiBltLockEquid BltLockStAtRowSecRiBltLockSts BltLockStAtRowSecRiBltLockSt1;
SIG_GROUP_ 112 RecOfPostImpctBrkgSuspc 1 : RecOfPostImpctBrkgSuspcSuspcPost RecOfPostImpctBrkgSuspcCntr RecOfPostImpctBrkgSuspcChks;
SIG_GROUP_ 112 BltLockStAtRowSecLe 1 : BltLockStAtRowSecLeBltLockEquid BltLockStAtRowSecLeBltLockSts BltLockStAtRowSecLeBltLockSt1;
SIG_GROUP_ 112 BltLockStAtRowThrdLe 1 : BltLockStAtRowThrdLeBltLockSts BltLockStAtRowThrdLeBltLockEquid BltLockStAtRowThrdLeBltLockSt1;
SIG_GROUP_ 112 BltLockStAtRowSecMid 1 : BltLockStAtRowSecMidBltLockSt1 BltLockStAtRowSecMidBltLockEquid BltLockStAtRowSecMidBltLockSts;
SIG_GROUP_ 328 RecOfImpct2 1 : RecOfImpct2ImpctDvySigned RecOfImpct2ImpctDvxSigned;
SIG_GROUP_ 328 RecOfPostImpctBrkgCfmd 1 : RecOfPostImpctBrkgCfmdCrash_0001 RecOfPostImpctBrkgCfmdCrashLarge RecOfPostImpctBrkgCfmdCrashRollo RecOfPostImpctBrkgCfmdCrashSideR RecOfPostImpctBrkgCfmdCrashRe RecOfPostImpctBrkgCfmdPostImpctB RecOfPostImpctBrkgCfmdCrash_0000 RecOfPostImpctBrkgCfmdCrashFrnt RecOfPostImpctBrkgCfmdChks RecOfPostImpctBrkgCfmdCrashPed RecOfPostImpctBrkgCfmdCrashOffro RecOfPostImpctBrkgCfmdCntr RecOfPostImpctBrkgCfmdCrashOz RecOfPostImpctBrkgCfmdCrash_0002 RecOfPostImpctBrkgCfmdCrashSideL;
SIG_GROUP_ 628 SRSResdSig1ToZCUDMSafety 1 : SRSResdSig1ToZCUDMSafetyChks SRSResdSig1ToZCUDMSafetyCntr SRSResdSig1ToZCUDMSafetyUInt32;
SIG_GROUP_ 560 AgDataCmpQuality 1 : AgDataCmpQualityYawRateCmpQualit AgDataCmpQualityRollRateCmpQuali AgDataCmpQualityPitchRateCmpQual;
SIG_GROUP_ 1371 VFCVectorSRS 1 : VFCVectorSRSVFCid56 VFCVectorSRSVFCid36 VFCVectorSRSVFCid53 VFCVectorSRSVFCid32 VFCVectorSRSVFCid12 VFCVectorSRSVFCid28 VFCVectorSRSVFCid1 VFCVectorSRSVFCid37 VFCVectorSRSVFCid11 VFCVectorSRSVFCid15 VFCVectorSRSVFCid49 VFCVectorSRSVFCid42 VFCVectorSRSVFCid34 VFCVectorSRSVFCid30 VFCVectorSRSVFCid21 VFCVectorSRSVFCid26 VFCVectorSRSVFCid18 VFCVectorSRSVFCid46 VFCVectorSRSVFCid55 VFCVectorSRSVFCid54 VFCVectorSRSVFCid19 VFCVectorSRSVFCid27 VFCVectorSRSVFCid43 VFCVectorSRSVFCid14 VFCVectorSRSVFCid0 VFCVectorSRSVFCid44 VFCVectorSRSVFCid61 VFCVectorSRSVFCid3 VFCVectorSRSVFCid4 VFCVectorSRSVFCid8 VFCVectorSRSVFCid25 VFCVectorSRSVFCid39 VFCVectorSRSVFCid6 VFCVectorSRSVFCid23 VFCVectorSRSVFCid24 VFCVectorSRSVFCid57 VFCVectorSRSVFCid13 VFCVectorSRSVFCid47 VFCVectorSRSVFCid35 VFCVectorSRSVFCid2 VFCVectorSRSVFCid7 VFCVectorSRSVFCid40 VFCVectorSRSVFCid9 VFCVectorSRSVFCid60 VFCVectorSRSBlockID VFCVectorSRSVFCid5 VFCVectorSRSVFCid29 VFCVectorSRSVFCid22 VFCVectorSRSVFCid31 VFCVectorSRSVFCid52 VFCVectorSRSVFCid38 VFCVectorSRSVFCid41 VFCVectorSRSVFCid17 VFCVectorSRSVFCid33 VFCVectorSRSVFCid10 VFCVectorSRSVFCid45 VFCVectorSRSVFCid51 VFCVectorSRSVFCid58 VFCVectorSRSVFCid59 VFCVectorSRSVFCid16 VFCVectorSRSVFCid20 VFCVectorSRSVFCid48 VFCVectorSRSVFCid50;
SIG_GROUP_ 145 TwbrWarnSts 1 : TwbrWarnStsChks TwbrWarnStsYesNo TwbrWarnStsCntr;
